VERSION ""

NS_ :

BS_:

BU_: CLU H_U CGW

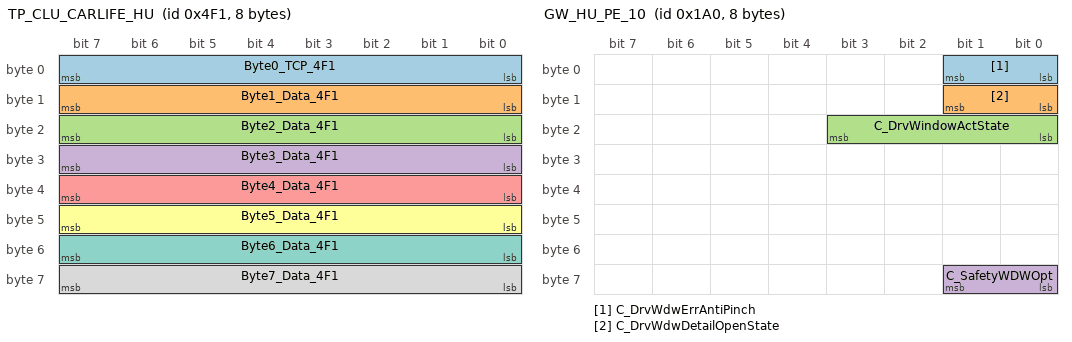
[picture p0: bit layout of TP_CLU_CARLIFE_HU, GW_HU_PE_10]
BO_ 1265 TP_CLU_CARLIFE_HU: 8 CLU
 SG_ Byte0_TCP_4F1 : 7|8@0+ (1,0) [0|0] ""  H_U
 SG_ Byte1_Data_4F1 : 15|8@0+ (1,0) [0|0] ""  H_U
 SG_ Byte2_Data_4F1 : 23|8@0+ (1,0) [0|0] ""  H_U
 SG_ Byte3_Data_4F1 : 31|8@0+ (1,0) [0|0] ""  H_U
 SG_ Byte4_Data_4F1 : 39|8@0+ (1,0) [0|0] ""  H_U
 SG_ Byte5_Data_4F1 : 47|8@0+ (1,0) [0|0] ""  H_U
 SG_ Byte6_Data_4F1 : 55|8@0+ (1,0) [0|0] ""  H_U
 SG_ Byte7_Data_4F1 : 63|8@0+ (1,0) [0|0] ""  H_U

BO_ 416 GW_HU_PE_10: 8 CGW
 SG_ C_DrvWdwErrAntiPinch : 1|2@0+ (1,0) [0|0] ""  H_U
 SG_ C_DrvWdwDetailOpenState : 9|2@0+ (1,0) [0|0] ""  H_U
 SG_ C_DrvWindowActState : 19|4@0+ (1,0) [0|0] ""  H_U
 SG_ C_SafetyWDWOpt : 57|2@0+ (1,0) [0|0] ""  H_U

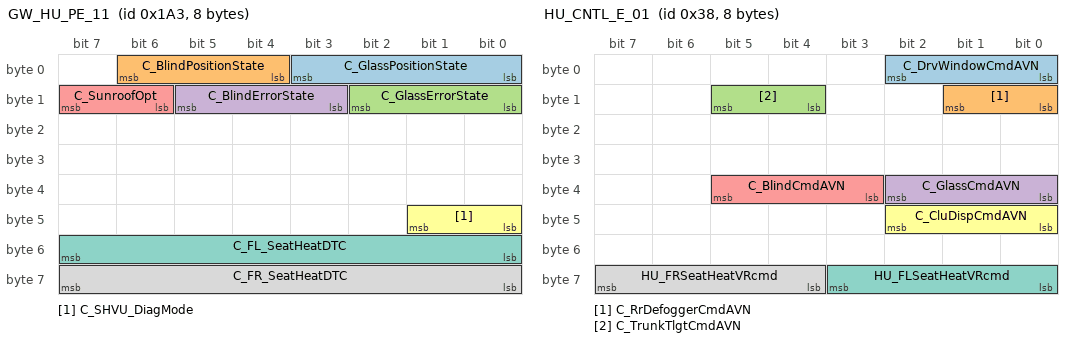
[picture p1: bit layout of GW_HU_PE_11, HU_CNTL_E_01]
BO_ 419 GW_HU_PE_11: 8 CGW
 SG_ C_GlassPositionState : 3|4@0+ (1,0) [0|0] ""  H_U
 SG_ C_BlindPositionState : 6|3@0+ (1,0) [0|0] ""  H_U
 SG_ C_GlassErrorState : 10|3@0+ (1,0) [0|0] ""  H_U
 SG_ C_BlindErrorState : 13|3@0+ (1,0) [0|0] ""  H_U
 SG_ C_SunroofOpt : 15|2@0+ (1,0) [0|0] ""  H_U
 SG_ C_SHVU_DiagMode : 41|2@0+ (1,0) [0|0] ""  H_U
 SG_ C_FL_SeatHeatDTC : 55|8@0+ (1,0) [0|0] ""  H_U
 SG_ C_FR_SeatHeatDTC : 63|8@0+ (1,0) [0|0] ""  H_U

BO_ 56 HU_CNTL_E_01: 8 H_U
 SG_ C_DrvWindowCmdAVN : 2|3@0+ (1,0) [0|0] ""  CGW,CLU
 SG_ C_RrDefoggerCmdAVN : 9|2@0+ (1,0) [0|0] ""  CGW,CLU
 SG_ C_TrunkTlgtCmdAVN : 13|2@0+ (1,0) [0|0] ""  CGW,CLU
 SG_ C_GlassCmdAVN : 34|3@0+ (1,0) [0|0] ""  CGW,CLU
 SG_ C_BlindCmdAVN : 37|3@0+ (1,0) [0|0] ""  CGW,CLU
 SG_ C_CluDispCmdAVN : 42|3@0+ (1,0) [0|0] ""  CLU
 SG_ HU_FLSeatHeatVRcmd : 59|4@0+ (1,0) [0|0] ""  CGW
 SG_ HU_FRSeatHeatVRcmd : 63|4@0+ (1,0) [0|0] ""  CGW

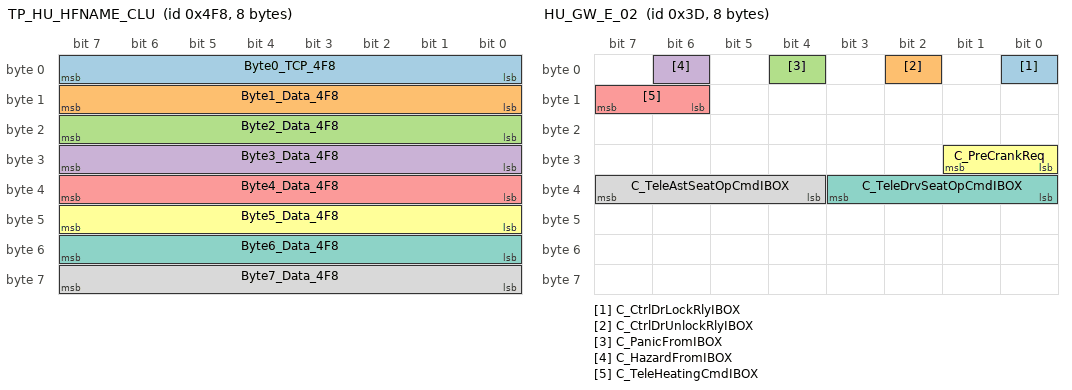
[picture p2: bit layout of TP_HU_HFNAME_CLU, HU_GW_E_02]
BO_ 1272 TP_HU_HFNAME_CLU: 8 H_U
 SG_ Byte0_TCP_4F8 : 7|8@0+ (1,0) [0|0] ""  CLU
 SG_ Byte1_Data_4F8 : 15|8@0+ (1,0) [0|0] ""  CLU
 SG_ Byte2_Data_4F8 : 23|8@0+ (1,0) [0|0] ""  CLU
 SG_ Byte3_Data_4F8 : 31|8@0+ (1,0) [0|0] ""  CLU
 SG_ Byte4_Data_4F8 : 39|8@0+ (1,0) [0|0] ""  CLU
 SG_ Byte5_Data_4F8 : 47|8@0+ (1,0) [0|0] ""  CLU
 SG_ Byte6_Data_4F8 : 55|8@0+ (1,0) [0|0] ""  CLU
 SG_ Byte7_Data_4F8 : 63|8@0+ (1,0) [0|0] ""  CLU

BO_ 61 HU_GW_E_02: 8 H_U
 SG_ C_CtrlDrLockRlyIBOX : 0|1@0+ (1,0) [0|0] ""  CGW
 SG_ C_CtrlDrUnlockRlyIBOX : 2|1@0+ (1,0) [0|0] ""  CGW
 SG_ C_PanicFromIBOX : 4|1@0+ (1,0) [0|0] ""  CGW
 SG_ C_HazardFromIBOX : 6|1@0+ (1,0) [0|0] ""  CGW
 SG_ C_TeleHeatingCmdIBOX : 15|2@0+ (1,0) [0|0] ""  CGW
 SG_ C_PreCrankReq : 25|2@0+ (1,0) [0|0] ""  CGW
 SG_ C_TeleDrvSeatOpCmdIBOX : 35|4@0+ (1,0) [0|0] ""  CGW
 SG_ C_TeleAstSeatOpCmdIBOX : 39|4@0+ (1,0) [0|0] ""  CGW

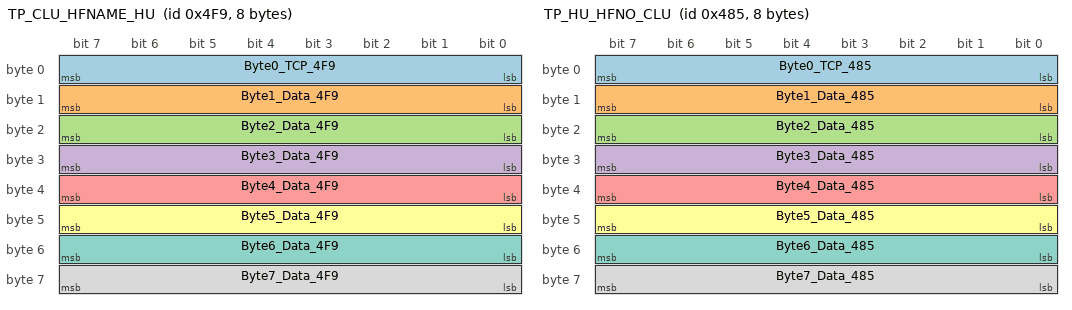
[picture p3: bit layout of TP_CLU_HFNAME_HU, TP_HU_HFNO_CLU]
BO_ 1273 TP_CLU_HFNAME_HU: 8 CLU
 SG_ Byte0_TCP_4F9 : 7|8@0+ (1,0) [0|0] ""  H_U
 SG_ Byte1_Data_4F9 : 15|8@0+ (1,0) [0|0] ""  H_U
 SG_ Byte2_Data_4F9 : 23|8@0+ (1,0) [0|0] ""  H_U
 SG_ Byte3_Data_4F9 : 31|8@0+ (1,0) [0|0] ""  H_U
 SG_ Byte4_Data_4F9 : 39|8@0+ (1,0) [0|0] ""  H_U
 SG_ Byte5_Data_4F9 : 47|8@0+ (1,0) [0|0] ""  H_U
 SG_ Byte6_Data_4F9 : 55|8@0+ (1,0) [0|0] ""  H_U
 SG_ Byte7_Data_4F9 : 63|8@0+ (1,0) [0|0] ""  H_U

BO_ 479 CLU_HU_PE_01: 8 CLU
 SG_ Clu_RheostatLvl : 55|5@0+ (1,0) [0|0] ""  CGW,H_U

BO_ 1157 TP_HU_HFNO_CLU: 8 H_U
 SG_ Byte0_TCP_485 : 7|8@0+ (1,0) [0|0] ""  CLU
 SG_ Byte1_Data_485 : 15|8@0+ (1,0) [0|0] ""  CLU
 SG_ Byte2_Data_485 : 23|8@0+ (1,0) [0|0] ""  CLU
 SG_ Byte3_Data_485 : 31|8@0+ (1,0) [0|0] ""  CLU
 SG_ Byte4_Data_485 : 39|8@0+ (1,0) [0|0] ""  CLU
 SG_ Byte5_Data_485 : 47|8@0+ (1,0) [0|0] ""  CLU
 SG_ Byte6_Data_485 : 55|8@0+ (1,0) [0|0] ""  CLU
 SG_ Byte7_Data_485 : 63|8@0+ (1,0) [0|0] ""  CLU

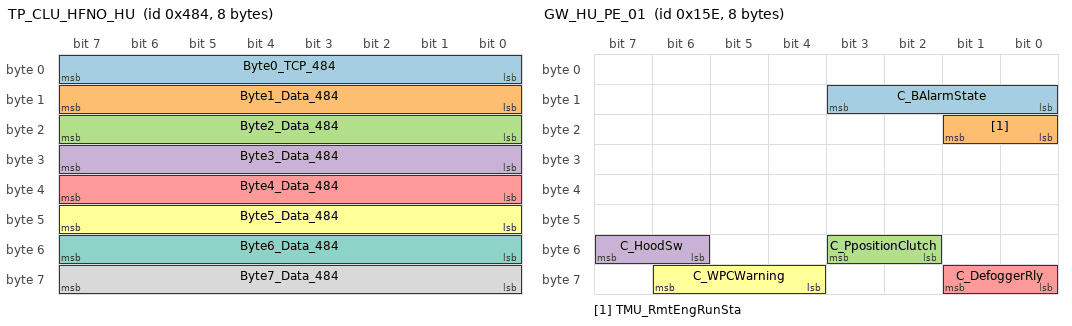
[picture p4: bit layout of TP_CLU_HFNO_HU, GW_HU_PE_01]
BO_ 1156 TP_CLU_HFNO_HU: 8 CLU
 SG_ Byte0_TCP_484 : 7|8@0+ (1,0) [0|0] ""  H_U
 SG_ Byte1_Data_484 : 15|8@0+ (1,0) [0|0] ""  H_U
 SG_ Byte2_Data_484 : 23|8@0+ (1,0) [0|0] ""  H_U
 SG_ Byte3_Data_484 : 31|8@0+ (1,0) [0|0] ""  H_U
 SG_ Byte4_Data_484 : 39|8@0+ (1,0) [0|0] ""  H_U
 SG_ Byte5_Data_484 : 47|8@0+ (1,0) [0|0] ""  H_U
 SG_ Byte6_Data_484 : 55|8@0+ (1,0) [0|0] ""  H_U
 SG_ Byte7_Data_484 : 63|8@0+ (1,0) [0|0] ""  H_U

BO_ 336 GW_AMP_PE_01: 8 CGW
 SG_ ANC_EngineCHR : 37|4@0+ (1,0) [0|15] ""  H_U

BO_ 1434 GW_HU_P_00: 8 CGW
 SG_ SAS_Angle : 7|16@0- (0.1,0) [-3276.8|3276.7] "Deg"  H_U

BO_ 350 GW_HU_PE_01: 8 CGW
 SG_ C_BAlarmState : 11|4@0+ (1,0) [0|0] ""  H_U
 SG_ TMU_RmtEngRunSta : 17|2@0+ (1,0) [0|0] ""  H_U
 SG_ C_PpositionClutch : 51|2@0+ (1,0) [0|0] ""  H_U
 SG_ C_HoodSw : 55|2@0+ (1,0) [0|0] ""  H_U
 SG_ C_DefoggerRly : 57|2@0+ (1,0) [0|0] ""  H_U
 SG_ C_WPCWarning : 62|3@0+ (1,0) [0|0] ""  H_U

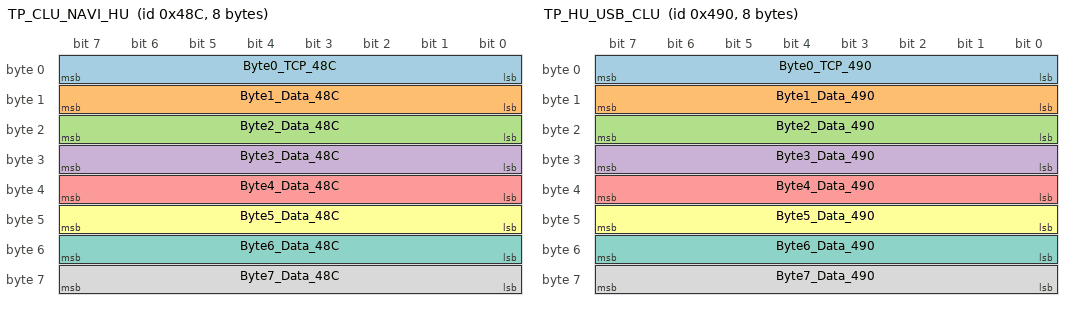
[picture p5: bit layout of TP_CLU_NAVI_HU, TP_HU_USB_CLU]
BO_ 1164 TP_CLU_NAVI_HU: 8 CLU
 SG_ Byte0_TCP_48C : 7|8@0+ (1,0) [0|0] ""  H_U
 SG_ Byte1_Data_48C : 15|8@0+ (1,0) [0|0] ""  H_U
 SG_ Byte2_Data_48C : 23|8@0+ (1,0) [0|0] ""  H_U
 SG_ Byte3_Data_48C : 31|8@0+ (1,0) [0|0] ""  H_U
 SG_ Byte4_Data_48C : 39|8@0+ (1,0) [0|0] ""  H_U
 SG_ Byte5_Data_48C : 47|8@0+ (1,0) [0|0] ""  H_U
 SG_ Byte6_Data_48C : 55|8@0+ (1,0) [0|0] ""  H_U
 SG_ Byte7_Data_48C : 63|8@0+ (1,0) [0|0] ""  H_U

BO_ 344 GW_CLU_PE: 8 CGW
 SG_ CF_Clu_LowfuelWarning : 13|2@0+ (1,0) [0|0] ""  H_U
 SG_ C_InhibitRMT : 15|2@0+ (1,0) [0|0] ""  H_U

BO_ 1168 TP_HU_USB_CLU: 8 H_U
 SG_ Byte0_TCP_490 : 7|8@0+ (1,0) [0|0] ""  CLU
 SG_ Byte1_Data_490 : 15|8@0+ (1,0) [0|0] ""  CLU
 SG_ Byte2_Data_490 : 23|8@0+ (1,0) [0|0] ""  CLU
 SG_ Byte3_Data_490 : 31|8@0+ (1,0) [0|0] ""  CLU
 SG_ Byte4_Data_490 : 39|8@0+ (1,0) [0|0] ""  CLU
 SG_ Byte5_Data_490 : 47|8@0+ (1,0) [0|0] ""  CLU
 SG_ Byte6_Data_490 : 55|8@0+ (1,0) [0|0] ""  CLU
 SG_ Byte7_Data_490 : 63|8@0+ (1,0) [0|0] ""  CLU

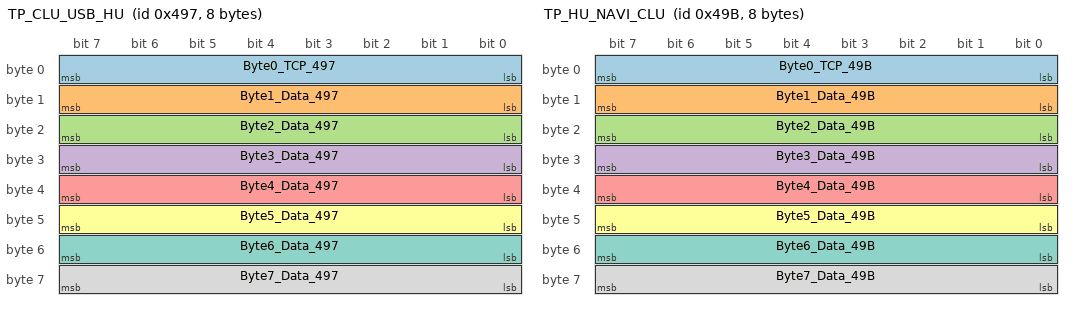
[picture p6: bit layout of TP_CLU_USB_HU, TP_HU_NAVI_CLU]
BO_ 1175 TP_CLU_USB_HU: 8 CLU
 SG_ Byte0_TCP_497 : 7|8@0+ (1,0) [0|0] ""  H_U
 SG_ Byte1_Data_497 : 15|8@0+ (1,0) [0|0] ""  H_U
 SG_ Byte2_Data_497 : 23|8@0+ (1,0) [0|0] ""  H_U
 SG_ Byte3_Data_497 : 31|8@0+ (1,0) [0|0] ""  H_U
 SG_ Byte4_Data_497 : 39|8@0+ (1,0) [0|0] ""  H_U
 SG_ Byte5_Data_497 : 47|8@0+ (1,0) [0|0] ""  H_U
 SG_ Byte6_Data_497 : 55|8@0+ (1,0) [0|0] ""  H_U
 SG_ Byte7_Data_497 : 63|8@0+ (1,0) [0|0] ""  H_U

BO_ 1179 TP_HU_NAVI_CLU: 8 H_U
 SG_ Byte0_TCP_49B : 7|8@0+ (1,0) [0|0] ""  CLU
 SG_ Byte1_Data_49B : 15|8@0+ (1,0) [0|0] ""  CLU
 SG_ Byte2_Data_49B : 23|8@0+ (1,0) [0|0] ""  CLU
 SG_ Byte3_Data_49B : 31|8@0+ (1,0) [0|0] ""  CLU
 SG_ Byte4_Data_49B : 39|8@0+ (1,0) [0|0] ""  CLU
 SG_ Byte5_Data_49B : 47|8@0+ (1,0) [0|0] ""  CLU
 SG_ Byte6_Data_49B : 55|8@0+ (1,0) [0|0] ""  CLU
 SG_ Byte7_Data_49B : 63|8@0+ (1,0) [0|0] ""  CLU

BO_ 448 HU_DATC_PE_00: 8 H_U
 SG_ HU_VRActivity : 33|2@0+ (1,0) [0|0] ""  CGW,CLU

BO_ 372 HU_GW_PE_02: 8 H_U
 SG_ HU_TeleSoCAlertValueSet : 7|8@0+ (1,0) [0|100] "%"  CGW
 SG_ HU_TeleVehicleStatusReq : 9|2@0+ (1,0) [0|3] ""  CGW

BO_ 369 HU_Car_PE_01: 8 H_U
 SG_ HU_VehiclePwr : 3|4@0+ (1,0) [0|0] ""  CLU

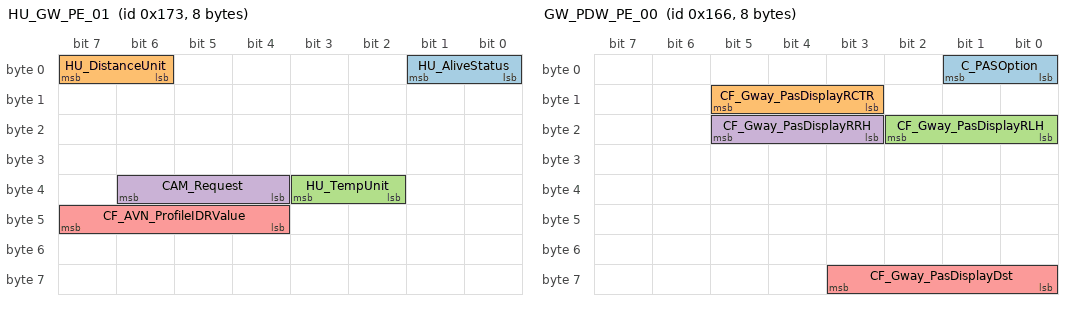
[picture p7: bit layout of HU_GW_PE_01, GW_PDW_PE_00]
BO_ 371 HU_GW_PE_01: 8 H_U
 SG_ HU_AliveStatus : 1|2@0+ (1,0) [0|0] ""  CGW,CLU
 SG_ HU_DistanceUnit : 7|2@0+ (1,0) [0|0] ""  CLU
 SG_ HU_TempUnit : 35|2@0+ (1,0) [0|0] ""  CGW,CLU
 SG_ CAM_Request : 38|3@0+ (1,0) [0|0] ""  CGW
 SG_ CF_AVN_ProfileIDRValue : 47|4@0+ (1,0) [0|0] ""  CGW,CLU

BO_ 232 HU_GW_E_00: 8 H_U
 SG_ C_SHVU_DTC_Mode : 29|2@0+ (1,0) [0|0] ""  CGW

BO_ 1329 DATC_P_02: 8 CGW
 SG_ DATC_AmbientTempC : 7|8@0+ (0.5,-41) [-40|60] "C"  H_U
 SG_ DATC_AmbientTempF : 23|8@0+ (1,-42) [-40|140] "F"  H_U

BO_ 383 GW_HU_PE_06: 8 CGW
 SG_ Warn_DrvDrSwSta : 1|2@0+ (1,0) [0|0] ""  H_U
 SG_ Warn_AsstDrSwSta : 3|2@0+ (1,0) [0|0] ""  H_U
 SG_ Warn_RrLftDrSwSta : 5|2@0+ (1,0) [0|0] ""  H_U
 SG_ Warn_RrRtDrSwSta : 7|2@0+ (1,0) [0|0] ""  H_U
 SG_ DoorLock_DrvDrUnLkSta : 9|2@0+ (1,0) [0|0] ""  H_U
 SG_ DoorLock_AsstDrUnLkSta : 11|2@0+ (1,0) [0|0] ""  H_U
 SG_ DoorLock_RrLftDrUnLkSta : 13|2@0+ (1,0) [0|0] ""  H_U
 SG_ DoorLock_RrRtDrUnLkSta : 15|2@0+ (1,0) [0|0] ""  H_U
 SG_ Trunk_TrnkTlgtSwSta : 17|2@0+ (1,0) [0|0] ""  H_U
 SG_ Warn_SunRoofOpnSta : 19|2@0+ (1,0) [0|0] ""  H_U
 SG_ BAlarm_PncAlrmReq : 21|2@0+ (1,0) [0|0] ""  H_U
 SG_ Lamp_AutoLtSnsrNightSta : 23|2@0+ (1,0) [0|0] ""  H_U
 SG_ ExtLamp_ExtrnlTailLmpSta : 25|2@0+ (1,0) [0|0] ""  H_U
 SG_ ExtLamp_FrFgLmpSta : 27|2@0+ (1,0) [0|0] ""  H_U
 SG_ ExtLamp_HdLmpHiSta : 29|2@0+ (1,0) [0|0] ""  H_U
 SG_ ExtLamp_HdLmpLoSta : 31|2@0+ (1,0) [0|0] ""  H_U
 SG_ C_DrvWindowOpenState : 33|2@0+ (1,0) [0|0] ""  H_U
 SG_ C_FOBBatteryStatusInfo : 41|2@0+ (1,0) [0|0] ""  H_U
 SG_ C_BrakeFluidSw : 43|2@0+ (1,0) [0|0] ""  H_U
 SG_ C_BCMFobID : 46|3@0+ (1,0) [0|0] ""  H_U
 SG_ C_SMKFobID : 50|3@0+ (1,0) [0|0] ""  H_U

BO_ 119 HU_BLE_E_03: 8 H_U
 SG_ C_BLE_Encrypted_Result4 : 7|64@0+ (1,0) [0|0] ""  CGW

BO_ 118 HU_BLE_E_02: 8 H_U
 SG_ C_BLE_Encrypted_Result3 : 7|64@0+ (1,0) [0|0] ""  CGW

BO_ 358 GW_PDW_PE_00: 8 CGW
 SG_ C_PASOption : 1|2@0+ (1,0) [0|0] ""  H_U
 SG_ CF_Gway_PasDisplayRCTR : 13|3@0+ (1,0) [0|0] ""  H_U
 SG_ CF_Gway_PasDisplayRLH : 18|3@0+ (1,0) [0|0] ""  H_U
 SG_ CF_Gway_PasDisplayRRH : 21|3@0+ (1,0) [0|0] ""  H_U
 SG_ CF_Gway_PasDisplayDst : 59|4@0+ (1,0) [0|0] ""  H_U

BO_ 117 HU_BLE_E_01: 8 H_U
 SG_ C_BLE_Encrypted_Result2 : 7|64@0+ (1,0) [0|0] ""  CGW

BO_ 116 HU_BLE_E_00: 8 H_U
 SG_ C_BLE_Encrypted_Result1 : 7|64@0+ (1,0) [0|0] ""  CGW

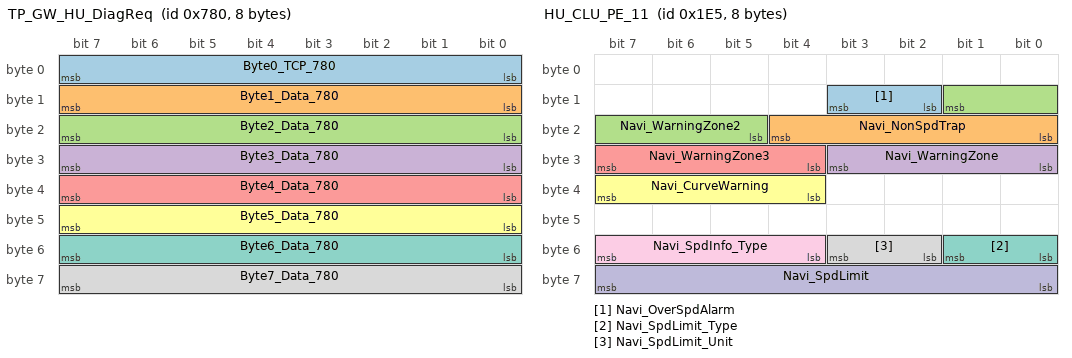
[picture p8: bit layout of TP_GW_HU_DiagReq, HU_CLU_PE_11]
BO_ 1920 TP_GW_HU_DiagReq: 8 CGW
 SG_ Byte0_TCP_780 : 7|8@0+ (1,0) [0|0] ""  H_U
 SG_ Byte1_Data_780 : 15|8@0+ (1,0) [0|0] ""  H_U
 SG_ Byte2_Data_780 : 23|8@0+ (1,0) [0|0] ""  H_U
 SG_ Byte3_Data_780 : 31|8@0+ (1,0) [0|0] ""  H_U
 SG_ Byte4_Data_780 : 39|8@0+ (1,0) [0|0] ""  H_U
 SG_ Byte5_Data_780 : 47|8@0+ (1,0) [0|0] ""  H_U
 SG_ Byte6_Data_780 : 55|8@0+ (1,0) [0|0] ""  H_U
 SG_ Byte7_Data_780 : 63|8@0+ (1,0) [0|0] ""  H_U

BO_ 485 HU_CLU_PE_11: 8 H_U
 SG_ Navi_OverSpdAlarm : 11|2@0+ (1,0) [0|0] ""  CGW,CLU
 SG_ Navi_NonSpdTrap : 20|5@0+ (1,0) [0|0] ""  CLU
 SG_ Navi_WarningZone2 : 9|5@0+ (1,0) [0|0] ""  CLU
 SG_ Navi_WarningZone : 27|4@0+ (1,0) [0|0] ""  CLU
 SG_ Navi_WarningZone3 : 31|4@0+ (1,0) [0|0] ""  CLU
 SG_ Navi_CurveWarning : 39|4@0+ (1,0) [0|0] ""  CLU
 SG_ Navi_SpdLimit_Type : 49|2@0+ (1,0) [0|0] ""  CLU
 SG_ Navi_SpdLimit_Unit : 51|2@0+ (1,0) [0|0] ""  CLU
 SG_ Navi_SpdInfo_Type : 55|4@0+ (1,0) [0|0] ""  CLU
 SG_ Navi_SpdLimit : 63|8@0+ (1,0) [1|254] ""  CLU

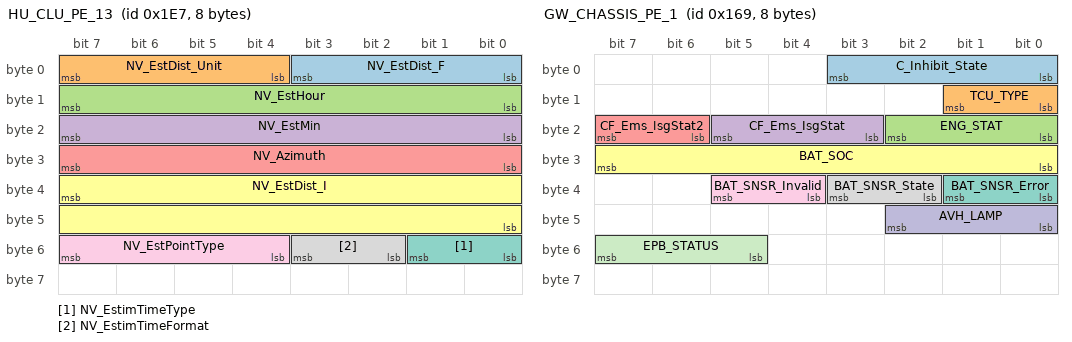
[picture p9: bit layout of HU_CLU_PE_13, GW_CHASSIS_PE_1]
BO_ 487 HU_CLU_PE_13: 8 H_U
 SG_ NV_EstDist_F : 3|4@0+ (1,0) [0|0] ""  CGW,CLU
 SG_ NV_EstDist_Unit : 7|4@0+ (1,0) [0|0] ""  CGW,CLU
 SG_ NV_EstHour : 15|8@0+ (1,0) [0|0] ""  CGW,CLU
 SG_ NV_EstMin : 23|8@0+ (1,0) [0|0] ""  CGW,CLU
 SG_ NV_Azimuth : 31|8@0+ (7.5,0) [0|352.5] "Degree"  CGW,CLU
 SG_ NV_EstDist_I : 39|16@0+ (1,0) [0|0] ""  CGW,CLU
 SG_ NV_EstimTimeType : 49|2@0+ (1,0) [0|0] ""  CGW,CLU
 SG_ NV_EstimTimeFormat : 51|2@0+ (1,0) [0|0] ""  CGW,CLU
 SG_ NV_EstPointType : 55|4@0+ (1,0) [0|0] ""  CGW,CLU

BO_ 361 GW_CHASSIS_PE_1: 8 CGW
 SG_ C_Inhibit_State : 3|4@0+ (1,0) [0|0] ""  H_U
 SG_ TCU_TYPE : 9|2@0+ (1,0) [0|3] ""  H_U
 SG_ ENG_STAT : 18|3@0+ (1,0) [0|7] ""  H_U
 SG_ CF_Ems_IsgStat : 21|3@0+ (1,0) [0|7] ""  H_U
 SG_ CF_Ems_IsgStat2 : 23|2@0+ (2,0) [0|3] ""  H_U
 SG_ BAT_SOC : 31|8@0+ (1,0) [0|100] "%"  H_U
 SG_ BAT_SNSR_Error : 33|2@0+ (1,0) [0|0] ""  H_U
 SG_ BAT_SNSR_State : 35|2@0+ (1,0) [0|0] ""  H_U
 SG_ BAT_SNSR_Invalid : 37|2@0+ (1,0) [0|0] ""  H_U
 SG_ AVH_LAMP : 42|3@0+ (1,0) [0|7] ""  H_U
 SG_ EPB_STATUS : 55|3@0+ (1,0) [0|7] ""  H_U

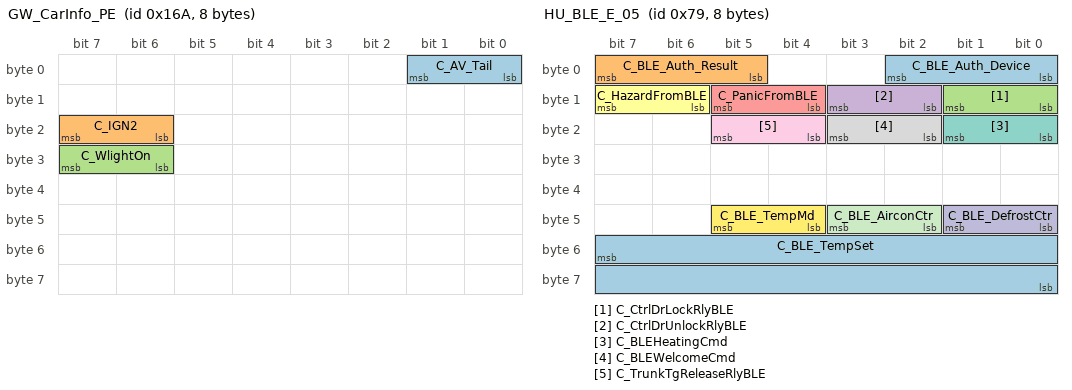
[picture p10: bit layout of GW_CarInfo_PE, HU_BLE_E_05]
BO_ 362 GW_CarInfo_PE: 8 CGW
 SG_ C_AV_Tail : 1|2@0+ (1,0) [0|0] ""  CLU,H_U
 SG_ C_IGN2 : 23|2@0+ (1,0) [0|0] ""  CLU,H_U
 SG_ C_WlightOn : 31|2@0+ (1,0) [0|0] ""  H_U

BO_ 121 HU_BLE_E_05: 8 H_U
 SG_ C_BLE_Auth_Device : 2|3@0+ (1,0) [0|0] ""  CGW
 SG_ C_BLE_Auth_Result : 7|3@0+ (1,0) [0|0] ""  CGW
 SG_ C_CtrlDrLockRlyBLE : 9|2@0+ (1,0) [0|0] ""  CGW
 SG_ C_CtrlDrUnlockRlyBLE : 11|2@0+ (1,0) [0|0] ""  CGW
 SG_ C_PanicFromBLE : 13|2@0+ (1,0) [0|0] ""  CGW
 SG_ C_HazardFromBLE : 15|2@0+ (1,0) [0|0] ""  CGW
 SG_ C_BLEHeatingCmd : 17|2@0+ (1,0) [0|0] ""  CGW
 SG_ C_BLEWelcomeCmd : 19|2@0+ (1,0) [0|0] ""  CGW
 SG_ C_TrunkTgReleaseRlyBLE : 21|2@0+ (1,0) [0|0] ""  CGW
 SG_ C_BLE_DefrostCtr : 41|2@0+ (1,0) [0|0] ""  CGW
 SG_ C_BLE_AirconCtr : 43|2@0+ (1,0) [0|0] ""  CGW
 SG_ C_BLE_TempMd : 45|2@0+ (1,0) [0|0] ""  CGW
 SG_ C_BLE_TempSet : 55|16@0+ (1,0) [0|0] ""  CGW

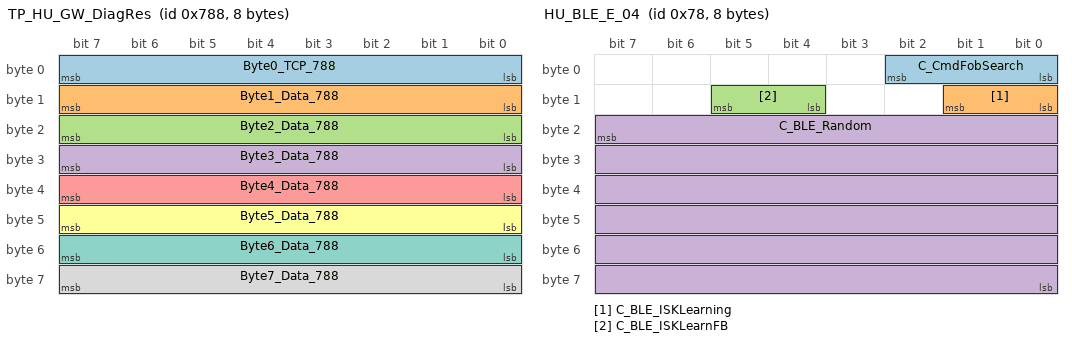
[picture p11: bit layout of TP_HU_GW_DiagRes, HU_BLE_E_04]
BO_ 1928 TP_HU_GW_DiagRes: 8 H_U
 SG_ Byte0_TCP_788 : 7|8@0+ (1,0) [0|0] ""  CGW
 SG_ Byte1_Data_788 : 15|8@0+ (1,0) [0|0] ""  CGW
 SG_ Byte2_Data_788 : 23|8@0+ (1,0) [0|0] ""  CGW
 SG_ Byte3_Data_788 : 31|8@0+ (1,0) [0|0] ""  CGW
 SG_ Byte4_Data_788 : 39|8@0+ (1,0) [0|0] ""  CGW
 SG_ Byte5_Data_788 : 47|8@0+ (1,0) [0|0] ""  CGW
 SG_ Byte6_Data_788 : 55|8@0+ (1,0) [0|0] ""  CGW
 SG_ Byte7_Data_788 : 63|8@0+ (1,0) [0|0] ""  CGW

BO_ 120 HU_BLE_E_04: 8 H_U
 SG_ C_CmdFobSearch : 2|3@0+ (1,0) [0|0] ""  CGW
 SG_ C_BLE_ISKLearning : 9|2@0+ (1,0) [0|0] ""  CGW
 SG_ C_BLE_ISKLearnFB : 13|2@0+ (1,0) [0|0] ""  CGW
 SG_ C_BLE_Random : 23|48@0+ (1,0) [0|0] ""  CGW

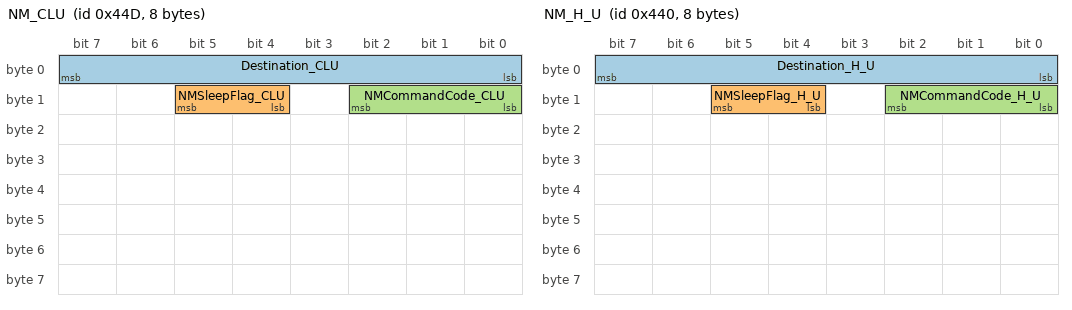
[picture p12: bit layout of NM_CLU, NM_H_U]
BO_ 1101 NM_CLU: 8 CLU
 SG_ Destination_CLU : 7|8@0+ (1,0) [0|0] ""  H_U,CGW
 SG_ NMSleepFlag_CLU : 13|2@0+ (1,0) [0|0] ""  H_U,CGW
 SG_ NMCommandCode_CLU : 10|3@0+ (1,0) [0|0] ""  H_U,CGW

BO_ 1088 NM_H_U: 8 H_U
 SG_ Destination_H_U : 7|8@0+ (1,0) [0|0] ""  CLU,CGW
 SG_ NMSleepFlag_H_U : 13|2@0+ (1,0) [0|0] ""  CLU,CGW
 SG_ NMCommandCode_H_U : 10|3@0+ (1,0) [0|0] ""  CLU,CGW

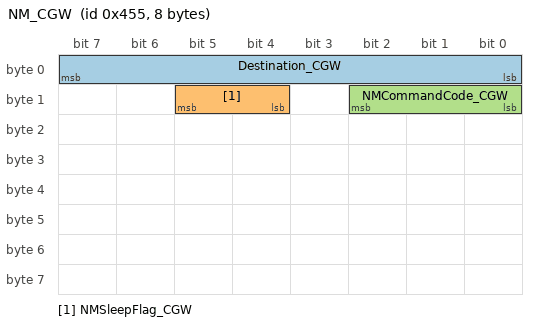
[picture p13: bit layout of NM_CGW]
BO_ 1109 NM_CGW: 8 CGW
 SG_ Destination_CGW : 7|8@0+ (1,0) [0|0] ""  CLU,H_U
 SG_ NMSleepFlag_CGW : 13|2@0+ (1,0) [0|0] ""  CLU,H_U
 SG_ NMCommandCode_CGW : 10|3@0+ (1,0) [0|0] ""  CLU,H_U

CM_ BO_ 1329 "[P] Periodic";
CM_ SG_ 1329 DATC_AmbientTempC "Ambient Temperature (C)";
CM_ SG_ 1329 DATC_AmbientTempF "Ambient Temperature (F)";
CM_ BO_ 336 "[PE] Periodic and On Event";
CM_ SG_ 336 ANC_EngineCHR "This signal indicates the characteristic of an engine system - which kind of fuel is used, whether the ETC (Electronic Throttle Contro) is applied or not.

When a normal engine system (gasoline fuel and no ETC) is used this value is 00H.

This signal is same with ENG_CHR (0x150 @CLU)";
CM_ BO_ 361 "[PE] Periodic and On Event";
CM_ SG_ 361 C_Inhibit_State "Information for TGS Lever Gear switch
- For Auto Transmission vehicles Only
- For Manual Transmission, Use C_InhibitRMT(@0x158) instead
- For IGN status, Should consider with this signal and C_IGN1(@0x15A) signal or wire
- This signal is valid only when C_IGN is on
- When C_IGN goes Off, Suppose this signal is OFF";
CM_ SG_ 361 TCU_TYPE "Information for Auto Transmission Type
 : AT 
/ CVT
 / DCT


* Manual transmission : no can signal";
CM_ SG_ 361 ENG_STAT "This signal indicates that a status of engine.
- Use ENG_STAT + CF_Ems_IsgStat or CF_Ems_IsgStat2 signal combination

- For detail logic, please refer to platform specification
* Do not use AltL status signal *";
CM_ SG_ 361 CF_Ems_IsgStat "1. ISG Status expressing CAN message divided by CF_EMS_IsgStat and CF_EMS_IsgStat2 
2. In EMS , CF_EMS_IsgStat and CF_EMS_IsgStat2 do not duplicate the output condition
(EX: If CF_EMS_IsgStat is 01h~07h, CF_EMS_IsgStat2 is 00h)

Use ENG_STAT + CF_Ems_IsgStat or CF_Ems_IsgStat2 signal combination 

For detail logic, please refer to platform specification";
CM_ SG_ 361 CF_Ems_IsgStat2 "1. ISG Status CAN message is divided by CF_EMS_IsgStat and CF_EMS_IsgStat2 
2. CF_EMS_IsgStat and CF_EMS_IsgStat2 do not duplicate the output condition
(EX: If CF_EMS_IsgStat2 is 01h~03h, CF_EMS_IsgStat is 00h)

Use ENG_STAT + CF_Ems_IsgStat or CF_Ems_IsgStat2 signal combination 

For detail logic, please refer to platform specification";
CM_ SG_ 361 BAT_SOC "This signal is battery State of Charge as calculated by battery sensor.
This signal is used for 'Scheduled Update Function' in Normal Vehicle.

PHY = 1 * (HEX Value)";
CM_ SG_ 361 BAT_SNSR_Error "This signal is response error status of battery LIN sensor signal.
HU use this signal for scheduled update function. 
Based on this single bit, HU can conclude the following : 

 - 0x0:operating correctly ==> Proceed the scheduled update.
 - 0x1:response error ==> Restrict the scheduled update.";
CM_ SG_ 361 BAT_SNSR_State "This signal is implausible state of battery SOC detection.
HU use this signal for scheduled update function. 
Based on this single bit, HU can conclude the following : 

 - 0x0:normal state ==> Proceed the scheduled update.
 - 0x1:implausible state ==> Restrict the scheduled update.";
CM_ SG_ 361 BAT_SNSR_Invalid "This signal is valid condition state of battery SOC.
HU use this signal for scheduled update function. 
Based on this single bit, HU can conclude the following : 

 - 0x0:Valid Condition ==> Proceed the scheduled update.
 - 0x1:Invalid Condition ==> Restrict the scheduled update.";
CM_ SG_ 361 AVH_LAMP "0x00 : Auto Hold Off Status
0x01 : Auto Hold Fail
0x02 : Auto Hold Active
0x03 : Auto Hold Ready
H/U should unlock the driver distraction mode even if signal is Auto hold Active(0x02).

Source: TCS15 message AVH_LAMP";
CM_ SG_ 361 EPB_STATUS "Information about the force status of the EPB.
(This signal is for NHTSA driving regulation)";
CM_ BO_ 344 "[PE] Periodic and On Event";
CM_ SG_ 344 CF_Clu_LowfuelWarning "Information for Low fuel warning for AVN";
CM_ SG_ 344 C_InhibitRMT "Information for TGS Lever - R for Manual Transmission Vehicle
For AT type, Use C_Inhibit_state(@0x169) instead";
CM_ BO_ 362 "[PE] Periodic and On Event";
CM_ SG_ 362 C_AV_Tail "Autolight Info";
CM_ SG_ 362 C_IGN2 "Information for IGN2 Status";
CM_ SG_ 362 C_WlightOn "Welcome light On/Off Order";
CM_ BO_ 350 "[PE] Periodic and On Event";
CM_ SG_ 350 C_BAlarmState "Information of Buglar Alarm State
For telematics";
CM_ SG_ 350 TMU_RmtEngRunSta "Information for Feedback of Tele-Cranking command
- Feedback of C_TeleCrankingCmdIBOX @HU_GW_PE_00(0x03D) signal";
CM_ SG_ 350 C_PpositionClutch "* Use for Telematics Remote start fail notification

This signal has different sources according to transmission type(AT/MT).
This siganl is valid when IBU has SMK function.
A/T : TGS Lever P Position Status (P Position Switch or Keyinterlock Switch)
- (Keyinterlock Switch) When TGS lever push button is pushed, though TGS lever is located at P position, this signal value can be 0x0, regardless TGS Lever Location  
M/T : Clutch Ignition Lock Switch";
CM_ SG_ 350 C_HoodSw "Information for Hood open status
For Telematics";
CM_ SG_ 350 C_DefoggerRly "This signal indicates rear glass defog status.";
CM_ SG_ 350 C_WPCWarning "Warning by WPC for User (Phone left in vehicle)

Display status of remote phone charging on H/U by using this signal.
Receiving 0x0 value means no phone or no WPC unit.
(In both cases, H/U indicates nothing)";
CM_ BO_ 383 "[PE] Periodic and On Event";
CM_ SG_ 383 Warn_DrvDrSwSta "Information for Driver Door Close SW
For H/U pre-booting, SVM(Surround View Module), Telematics Function";
CM_ SG_ 383 Warn_AsstDrSwSta "Information for Assist Door Close SW
For SVM(Surround View Module), Telematics Function";
CM_ SG_ 383 Warn_RrLftDrSwSta "Information for Rear Left Door Close SW
For SVM(Surround View Module), Telematics Function";
CM_ SG_ 383 Warn_RrRtDrSwSta "Information for Rear Right Door Close SW
For SVM(Surround View Module), Telematics Function";
CM_ SG_ 383 DoorLock_DrvDrUnLkSta "Driver Door Lock Status for Prebooting and telematics";
CM_ SG_ 383 DoorLock_AsstDrUnLkSta "Assist Door Lock Status for telematics";
CM_ SG_ 383 DoorLock_RrLftDrUnLkSta "Rear Left Door Lock Status for telematics";
CM_ SG_ 383 DoorLock_RrRtDrUnLkSta "Rear Right Door Lock Status for telematics";
CM_ SG_ 383 Trunk_TrnkTlgtSwSta "Information for Trunk Tailgate Door Close SW
For SVM(Surround View Module), Telematics Function";
CM_ SG_ 383 Warn_SunRoofOpnSta "Information of Sunroof Open/Close State";
CM_ SG_ 383 BAlarm_PncAlrmReq "Information of Panic State
For telematics";
CM_ SG_ 383 Lamp_AutoLtSnsrNightSta "This signal indicates autolight sensor output.
This signal also used for early evening status determination for LCD illumination.
* Early evening mode condition : 
When C_AV_Tail is 0x1 (Deactivated) and Lamp_AutoLtSnsrNightSta is 0x1 (Night), early evening status is activated";
CM_ SG_ 383 ExtLamp_ExtrnlTailLmpSta "Tail Lamp On/Off status signal";
CM_ SG_ 383 ExtLamp_FrFgLmpSta "Front fog lamp On/Off status signal";
CM_ SG_ 383 ExtLamp_HdLmpHiSta "High beam lead lamp On/Off status signal";
CM_ SG_ 383 ExtLamp_HdLmpLoSta "Low beam lead lamp On/Off status signal";
CM_ SG_ 383 C_DrvWindowOpenState "This signal indicates DRV Window Open/Close Status";
CM_ SG_ 383 C_FOBBatteryStatusInfo "Receive Fob Battery Status for Telematics Vehicle Information Service";
CM_ SG_ 383 C_BrakeFluidSw "Brake oil warning notification (on/off)";
CM_ SG_ 383 C_BCMFobID "Fob key ID for HU personalized function";
CM_ SG_ 383 C_SMKFobID "SMK ID for personalized function";
CM_ BO_ 416 "[PE] Periodic and On Event";
CM_ SG_ 416 C_DrvWdwErrAntiPinch "The DRV Window state whether Calibrated or not";
CM_ SG_ 416 C_DrvWdwDetailOpenState "This signal indicates DRV Window Open/Close Detail Status";
CM_ SG_ 416 C_DrvWindowActState "This signal indicates DRV Window Action Status";
CM_ SG_ 416 C_SafetyWDWOpt "Option flag for All Safety Window system";
CM_ BO_ 419 "[PE] Periodic and On Event";
CM_ SG_ 419 C_GlassPositionState "This signal indicates Sunroof Glass Open/Close Status";
CM_ SG_ 419 C_BlindPositionState "This signal indicates Sunroof Blind Open/Close Status";
CM_ SG_ 419 C_GlassErrorState "This signal indicates Sunroof Glass error Status";
CM_ SG_ 419 C_BlindErrorState "This signal indicates Sunroof Blind error Status";
CM_ SG_ 419 C_SunroofOpt "Option flag for Sunroof system";
CM_ SG_ 419 C_SHVU_DiagMode "Seat diagnosis status";
CM_ SG_ 419 C_FL_SeatHeatDTC "Driver seat DTC to show on HU";
CM_ SG_ 419 C_FR_SeatHeatDTC "Passenger seat DTC to show on HU";
CM_ BO_ 1434 "[P] Periodic";
CM_ SG_ 1434 SAS_Angle "Information regarding the steering wheel angle.

(PH) = (HEX) * 0.1 (0 <  HEX ≤ 7FFFH) or
(PH) = (HEX - 65536) * 0.1 (HEX > 7FFFH)";
CM_ BO_ 358 "[PE] Periodic and On Event";
CM_ SG_ 358 C_PASOption "PAS Option information";
CM_ SG_ 358 CF_Gway_PasDisplayRCTR "PAS Warning display : Rear Center";
CM_ SG_ 358 CF_Gway_PasDisplayRLH "PAS Warning display : Rear Left";
CM_ SG_ 358 CF_Gway_PasDisplayRRH "PAS Warning display : Rear Right";
CM_ SG_ 358 CF_Gway_PasDisplayDst "When in R gear status, IBU(BCM) send display signal to show rear distance info on HU RVM or SVM screen";
CM_ BO_ 1920 "[TP] TP Message";
CM_ BO_ 479 "[PE] Periodic and On Event";
CM_ SG_ 479 Clu_RheostatLvl "For LCD brightness Only
Keyboard brightness is using Hard Wire
Step 21 is Detent

This signal is valid at 'Tail On' condition";
CM_ BO_ 1265 "[TP] TP Message";
CM_ BO_ 1273 "[TP] TP Message";
CM_ BO_ 1156 "[TP] TP Message";
CM_ BO_ 1164 "[TP] TP Message";
CM_ BO_ 1175 "[TP] TP Message";
CM_ BO_ 116 "[EC] On Event and On Change";
CM_ SG_ 116 C_BLE_Encrypted_Result1 "This signal is for a send encrypted result of BLE.";
CM_ BO_ 117 "[EC] On Event and On Change";
CM_ SG_ 117 C_BLE_Encrypted_Result2 "This signal is for a send encrypted result of BLE.";
CM_ BO_ 118 "[EC] On Event and On Change";
CM_ SG_ 118 C_BLE_Encrypted_Result3 "This signal is for a send encrypted result of BLE.";
CM_ BO_ 119 "[EC] On Event and On Change";
CM_ SG_ 119 C_BLE_Encrypted_Result4 "This signal is for a send encrypted result of BLE.";
CM_ BO_ 120 "[EC] On Event and On Change";
CM_ SG_ 120 C_CmdFobSearch "Signal to request Fob search to IBU";
CM_ SG_ 120 C_BLE_ISKLearning "This signal is to request ISK Learning to IBU";
CM_ SG_ 120 C_BLE_ISKLearnFB "This signal is Learning Feedback";
CM_ SG_ 120 C_BLE_Random "Random number";
CM_ BO_ 121 "[EC] On Event and On Change";
CM_ SG_ 121 C_BLE_Auth_Device "This signal inform where ask to auth to HU";
CM_ SG_ 121 C_BLE_Auth_Result "This signal informs the result of authentication";
CM_ SG_ 121 C_CtrlDrLockRlyBLE "For BLE Remote Lock Command";
CM_ SG_ 121 C_CtrlDrUnlockRlyBLE "For BLE Remote UnLock Command";
CM_ SG_ 121 C_PanicFromBLE "For BLE Remote Panic Command";
CM_ SG_ 121 C_HazardFromBLE "For BLE Remote Hazard Command";
CM_ SG_ 121 C_BLEHeatingCmd "For BLE Remote Heating
(Steering Wheel, Rear Window, Side Mirror)";
CM_ SG_ 121 C_BLEWelcomeCmd "For BLE Welcome Command";
CM_ SG_ 121 C_TrunkTgReleaseRlyBLE "For BLE Remote Trunk Command";
CM_ SG_ 121 C_BLE_DefrostCtr "For BLE remote climate defrost Command";
CM_ SG_ 121 C_BLE_AirconCtr "For BLE remote climate control Command";
CM_ SG_ 121 C_BLE_TempMd "For BLE remote climate mode Command";
CM_ SG_ 121 C_BLE_TempSet "For BLE remote climate temp setting Command.
Value table
0x0:OFF, 0x1:LO, 0x2:15℃/58℉, 0x3:15.5℃/59℉, 0x4:16℃/60, 0x5:16.5℃/61℉, 0x6:17℃/62℉, 0x7:17.5℃/63℉, 0x8:18℃/64℉, 0x9:18.5℃/65℉, 0xA:19℃/66℉, 0xB:19.5℃/67℉, 0xC:20℃/68℉, 0xD:20.5℃/69℉, 0xE:21℃/70℉, 0xF:21.5℃/71℉, 0x10:22℃/72℉, 0x11:22.5℃/73℉, 0x12:23℃/74℉, 0x13:23.5℃/75℉, 0x14:24℃/76℉, 0x15:24.5℃/77℉, 0x16:25℃/78℉, 0x17:25.5℃/79℉, 0x18:26℃/80℉, 0x19:26.5℃/81℉, 0x1A:27℃/82℉, 0x1B:27.5℃/83℉, 0x1C:28℃/84℉, 0x1D:28.5℃/85℉, 0x1E:29℃/86℉, 0x1F:29.5℃/87℉, 0x20:30℃/88℉, 0x21:30.5℃/89℉, 0x22:31℃/90℉, 0x23:31.5℃/91℉, 0x24:32℃/92℉, 0xFE:HI, 0xFF:INVALID";
CM_ BO_ 485 "[PE] Periodic and On Event";
CM_ SG_ 485 Navi_OverSpdAlarm "Command for Alarm of Over speed";
CM_ SG_ 485 Navi_NonSpdTrap "Inform Non Speed-Traps";
CM_ SG_ 485 Navi_WarningZone2 "Inform warning zones";
CM_ SG_ 485 Navi_WarningZone "Inform warning zones";
CM_ SG_ 485 Navi_WarningZone3 "Inform warning zones";
CM_ SG_ 485 Navi_CurveWarning "Information for Warning a curve";
CM_ SG_ 485 Navi_SpdLimit_Type "Information for Type of Speed Limit Warning";
CM_ SG_ 485 Navi_SpdLimit_Unit "Informatin for Unit of Speed Limit Warning";
CM_ SG_ 485 Navi_SpdInfo_Type "Information for Type of Warning related with Speed";
CM_ SG_ 485 Navi_SpdLimit "Information for Speed of Speed Limit Warning";
CM_ BO_ 487 "[PE] Periodic and On Event";
CM_ SG_ 487 NV_EstDist_F "Information for distance to destination or stops (Under decimal point)";
CM_ SG_ 487 NV_EstDist_Unit "Information for distance unit
Unit for NV_EstDist_F & Nv_EstDist_F";
CM_ SG_ 487 NV_EstHour "Information for Estimate Time of Arrival / Necessary Time (Hour)";
CM_ SG_ 487 NV_EstMin "Information for Estimate Time of Arrival / Necessary Time (Minutes)";
CM_ SG_ 487 NV_Azimuth "Information for north azimuth angle
- 48 directions (7.5 deg. Interval)";
CM_ SG_ 487 NV_EstDist_I "Information for distance to destination or stops (Over decimal point)";
CM_ SG_ 487 NV_EstimTimeType "Information for Estimated time type
1. ETA(Estimated Time to Arrive)
2. RTA(Remaining Time to Arrive) - (Necessary Time)";
CM_ SG_ 487 NV_EstimTimeFormat "Information for Time Format of Estimated Arrival Time (12H/24H)";
CM_ SG_ 487 NV_EstPointType "Informatio for Destination / Waypoint Type";
CM_ BO_ 56 "[EC] On Event and On Change";
CM_ SG_ 56 C_DrvWindowCmdAVN "This signal indicates DRV Window Open/Close Command";
CM_ SG_ 56 C_RrDefoggerCmdAVN "This signal indicates Rear Defogger Button Command";
CM_ SG_ 56 C_TrunkTlgtCmdAVN "This signal indicates Trunk Open Button Command";
CM_ SG_ 56 C_GlassCmdAVN "This signal indicates Sunroof Glass Open/Close Command";
CM_ SG_ 56 C_BlindCmdAVN "This signal indicates Sunroof Blind Open/Close Command";
CM_ SG_ 56 C_CluDispCmdAVN "This signal indicates cluster display changing Command";
CM_ SG_ 56 HU_FLSeatHeatVRcmd "This signal indicated seat heat&vent VR control command (For driver seat)";
CM_ SG_ 56 HU_FRSeatHeatVRcmd "This signal indicated seat heat&vent VR control command (For passenger seat)";
CM_ BO_ 369 "[PE] Periodic and On Event";
CM_ SG_ 369 HU_VehiclePwr "Information for the H/U power status for ADM(Accessary Delay Mode)";
CM_ BO_ 448 "[PE] Periodic and On Event";
CM_ SG_ 448 HU_VRActivity "Information for Acitivity of VR (For All area)";
CM_ BO_ 232 "[EC] On Event and On Change";
CM_ SG_ 232 C_SHVU_DTC_Mode "HU diagnosis request to seat";
CM_ BO_ 61 "[EC] On Event and On Change";
CM_ SG_ 61 C_CtrlDrLockRlyIBOX "Command for Remote Door Lock";
CM_ SG_ 61 C_CtrlDrUnlockRlyIBOX "Command for Remote Door UnLock";
CM_ SG_ 61 C_PanicFromIBOX "Command for Remote Panic (Only for USA)";
CM_ SG_ 61 C_HazardFromIBOX "Command for Remote Hazard";
CM_ SG_ 61 C_TeleHeatingCmdIBOX "'Command for Remote Heating

(Steering Wheel, Rear Window, Side Mirror)";
CM_ SG_ 61 C_PreCrankReq "Command for B-CAN wake up signal
(Need to send this signal before other remote commands)";
CM_ SG_ 61 C_TeleDrvSeatOpCmdIBOX "Command for Remote Seat Heat/Vent control (Driver)";
CM_ SG_ 61 C_TeleAstSeatOpCmdIBOX "Command for Remote Seat Heat/Vent control (Passenger)";
CM_ BO_ 371 "[PE] Periodic and On Event";
CM_ SG_ 371 HU_AliveStatus "Information of the status of Head Unit
0x00 : Headunit is booting so, Headunit cant display any state
0x01 : Headunit is normal state, Headunit could display according to MM CAN  command.
0x02 : Headunit is doing their internal process, so Headunit cant communicate with other node.
For CLU/SCC/eCall
-AVN System transmission signal";
CM_ SG_ 371 HU_DistanceUnit "Request to set CLU Distance Unit";
CM_ SG_ 371 HU_TempUnit "Request to set DATC/CLU temperature unit";
CM_ SG_ 371 CAM_Request "HU command for AHD(Analog High Definition) camera to show different view screen";
CM_ SG_ 371 CF_AVN_ProfileIDRValue "This signal is User ID value in H/Unit.";
CM_ BO_ 372 "[PE] Periodic and On Event";
CM_ SG_ 372 HU_TeleSoCAlertValueSet "Alert reference value. The resolution is 1%.";
CM_ SG_ 372 HU_TeleVehicleStatusReq "Request vehicle status information.";
CM_ BO_ 1928 "[TP] TP Message";
CM_ SG_ 1928 Byte0_TCP_788 "Diagnosis Response to external tester through CGW";
CM_ SG_ 1928 Byte1_Data_788 "Diagnosis Response to external tester through CGW";
CM_ SG_ 1928 Byte2_Data_788 "Diagnosis Response to external tester through CGW";
CM_ SG_ 1928 Byte3_Data_788 "Diagnosis Response to external tester through CGW";
CM_ SG_ 1928 Byte4_Data_788 "Diagnosis Response to external tester through CGW";
CM_ SG_ 1928 Byte5_Data_788 "Diagnosis Response to external tester through CGW";
CM_ SG_ 1928 Byte6_Data_788 "Diagnosis Response to external tester through CGW";
CM_ SG_ 1928 Byte7_Data_788 "Diagnosis Response to external tester through CGW";
CM_ BO_ 1272 "[TP] TP Message";
CM_ BO_ 1157 "[TP] TP Message";
CM_ BO_ 1179 "[TP] TP Message";
CM_ BO_ 1168 "[TP] TP Message";
CM_ BO_ 1101 "NM Message";
CM_ BO_ 1088 "NM Message";
CM_ BO_ 1109 "NM Message";
BA_DEF_ SG_ "Gatewaysignal" ENUM "No","M-B","B-M","M-C","C-M","M-C-B" ;
BA_DEF_ SG_ "GenSigEnvVarType" ENUM "Int","Float","undef" ;
BA_DEF_ SG_ "GenSigSendType" ENUM "Cyclic","OnWrite","OnWriteWithRepetition","OnChange","OnChangeWithRepetition","IfActive","IfActiveWithRepetition","NoSigSendType" ;
BA_DEF_ SG_ "GenSigStartValue" INT 0 0 ;
BA_DEF_ SG_ "GwSigLatencyTime" INT 0 65535 ;
BA_DEF_ SG_ "GwSigMissingSourceType" ENUM "Undef","OldValue","DefaultValue","InitialValue" ;
BA_DEF_ SG_ "NmNetworkRequest" ENUM "No","Yes" ;
BA_DEF_ SG_ "NmNetworkRequestHoldingTime" INT 0 65535 ;
BA_DEF_ SG_ "Purpose" ENUM "<t.b.d.>","Function","Diagnostic","Development","NM" ;
BA_DEF_ SG_ "SignalCategory" HEX 10 15 ;
BA_DEF_ SG_ "TimeoutValue" STRING ;
BA_DEF_ SG_ "UpdateRateMax" INT 0 0 ;
BA_DEF_ SG_ "UpdateRateMin" INT 0 0 ;
BA_DEF_ SG_ "Validity" ENUM "B+","ACC","IGN1","IGN2" ;
BA_DEF_ BO_ "DiagRequest" ENUM "No","Yes" ;
BA_DEF_ BO_ "DiagResponse" ENUM "No","Yes" ;
BA_DEF_ BO_ "DiagState" ENUM "No","Yes" ;
BA_DEF_ BO_ "GenMsgCycleTime" INT 0 100000 ;
BA_DEF_ BO_ "GenMsgCycleTimeFast" INT 0 500 ;
BA_DEF_ BO_ "GenMsgDelayTime" INT 0 20 ;
BA_DEF_ BO_ "GenMsgEVName" STRING ;
BA_DEF_ BO_ "GenMsgILSupport" ENUM "No","Yes" ;
BA_DEF_ BO_ "GenMsgNrOfRepetition" INT 0 3 ;
BA_DEF_ BO_ "GenMsgSendType" ENUM "Cyclic","not_used","not_used","not_used","not_used","not_used","not_used","not_used","NoMsgSendType" ;
BA_DEF_ BO_ "GenMsgStartDelayTime" INT 0 2000 ;
BA_DEF_ BO_ "NmMessage" ENUM "No","Yes" ;
BA_DEF_ BO_ "RoutingType" ENUM "<n.a.>","Direct","Indirect" ;
BA_DEF_ BO_ "TpMessage" ENUM "No","Yes" ;
BA_DEF_ BO_ "TpTxIndex" INT 0 255 ;
BA_DEF_ SG_ "SigDescription" STRING ;
BA_DEF_ SG_ "Platform" STRING ;
BA_DEF_ SG_ "SigOldType" ENUM "No","Yes" ;
BA_DEF_REL_ BU_SG_REL_ "GenSigTimeoutTime" INT 0 7000 ;
BA_DEF_DEF_ "Gatewaysignal" "No" ;
BA_DEF_DEF_ "GenSigEnvVarType" "undef" ;
BA_DEF_DEF_ "GenSigSendType" "NoSigSendType" ;
BA_DEF_DEF_ "GenSigStartValue" 0 ;
BA_DEF_DEF_ "GwSigLatencyTime" 40 ;
BA_DEF_DEF_ "GwSigMissingSourceType" "Undef" ;
BA_DEF_DEF_ "NmNetworkRequest" "No" ;
BA_DEF_DEF_ "NmNetworkRequestHoldingTime" 0 ;
BA_DEF_DEF_ "Purpose" "<t.b.d.>" ;
BA_DEF_DEF_ "SignalCategory" 12 ;
BA_DEF_DEF_ "TimeoutValue" "" ;
BA_DEF_DEF_ "UpdateRateMax" 0 ;
BA_DEF_DEF_ "UpdateRateMin" 0 ;
BA_DEF_DEF_ "Validity" "ACC" ;
BA_DEF_DEF_ "DiagRequest" "No" ;
BA_DEF_DEF_ "DiagResponse" "No" ;
BA_DEF_DEF_ "DiagState" "No" ;
BA_DEF_DEF_ "GenMsgCycleTime" 0 ;
BA_DEF_DEF_ "GenMsgCycleTimeFast" 0 ;
BA_DEF_DEF_ "GenMsgDelayTime" 20 ;
BA_DEF_DEF_ "GenMsgEVName" "@Signame" ;
BA_DEF_DEF_ "GenMsgILSupport" "Yes" ;
BA_DEF_DEF_ "GenMsgNrOfRepetition" 0 ;
BA_DEF_DEF_ "GenMsgSendType" "NoMsgSendType" ;
BA_DEF_DEF_ "GenMsgStartDelayTime" 0 ;
BA_DEF_DEF_ "NmMessage" "No" ;
BA_DEF_DEF_ "RoutingType" "<n.a.>" ;
BA_DEF_DEF_ "TpMessage" "No" ;
BA_DEF_DEF_ "TpTxIndex" 0 ;
BA_DEF_DEF_ "SigDescription" "" ;
BA_DEF_DEF_ "Platform" "Standard AVN 4.0,Standard Audio 3.0,Premium AVN 3.0" ;
BA_DEF_DEF_ "SigOldType" "No" ;
BA_DEF_DEF_REL_ "GenSigTimeoutTime" 700 ;
BA_ "GenMsgSendType" BO_ 1329 0;
BA_ "GenMsgCycleTime" BO_ 1329 1000;
BA_ "GenMsgStartDelayTime" BO_ 1329 350;
BA_REL_ "GenSigTimeoutTime" BU_SG_REL_ H_U SG_ 1329 DATC_AmbientTempC 3500;
BA_ "Platform" SG_ 1329 DATC_AmbientTempC "";
BA_ "GenSigStartValue" SG_ 1329 DATC_AmbientTempC 255;
BA_ "Gatewaysignal" SG_ 1329 DATC_AmbientTempC 4;
BA_ "TimeoutValue" SG_ 1329 DATC_AmbientTempC "Old Value";
BA_ "Validity" SG_ 1329 DATC_AmbientTempC 2;
BA_REL_ "GenSigTimeoutTime" BU_SG_REL_ H_U SG_ 1329 DATC_AmbientTempF 3500;
BA_ "Platform" SG_ 1329 DATC_AmbientTempF "";
BA_ "GenSigStartValue" SG_ 1329 DATC_AmbientTempF 255;
BA_ "Gatewaysignal" SG_ 1329 DATC_AmbientTempF 4;
BA_ "TimeoutValue" SG_ 1329 DATC_AmbientTempF "Old Value";
BA_ "Validity" SG_ 1329 DATC_AmbientTempF 2;
BA_ "GenMsgSendType" BO_ 336 0;
BA_ "GenMsgCycleTime" BO_ 336 200;
BA_ "GenMsgStartDelayTime" BO_ 336 110;
BA_ "SigDescription" SG_ 336 ANC_EngineCHR "1. For the automatic variant coding at E.O.L : This signal value is valid 1.5sec later from initial IG-ON
2. In case of Delphi ECU, Output period tolerance(+1ms) will be applied to Engine Lamda3.";
BA_ "Platform" SG_ 336 ANC_EngineCHR "";
BA_ "GenSigSendType" SG_ 336 ANC_EngineCHR 3;
BA_ "Gatewaysignal" SG_ 336 ANC_EngineCHR 4;
BA_ "TimeoutValue" SG_ 336 ANC_EngineCHR "old value";
BA_ "Validity" SG_ 336 ANC_EngineCHR 2;
BA_ "GenMsgSendType" BO_ 361 0;
BA_ "GenMsgCycleTime" BO_ 361 200;
BA_ "GenMsgStartDelayTime" BO_ 361 110;
BA_ "Platform" SG_ 361 C_Inhibit_State "";
BA_ "GenSigSendType" SG_ 361 C_Inhibit_State 3;
BA_ "GenSigStartValue" SG_ 361 C_Inhibit_State 15;
BA_ "TimeoutValue" SG_ 361 C_Inhibit_State "0xF";
BA_ "Validity" SG_ 361 C_Inhibit_State 2;
BA_REL_ "GenSigTimeoutTime" BU_SG_REL_ H_U SG_ 361 TCU_TYPE 500;
BA_ "Platform" SG_ 361 TCU_TYPE "";
BA_ "GenSigSendType" SG_ 361 TCU_TYPE 3;
BA_ "Gatewaysignal" SG_ 361 TCU_TYPE 4;
BA_ "TimeoutValue" SG_ 361 TCU_TYPE "Old Value";
BA_ "Validity" SG_ 361 TCU_TYPE 2;
BA_ "Purpose" SG_ 361 ENG_STAT 1;
BA_REL_ "GenSigTimeoutTime" BU_SG_REL_ H_U SG_ 361 ENG_STAT 500;
BA_ "SigDescription" SG_ 361 ENG_STAT "In case of Delphi ECU, Output period tolerance(+1ms) will be applied to Engine Lamda3.
* ISG Applied vehicles should consider CF_Ems_IgsStat and CF_Ems_IgsStat2 signals for check alternator status ALT_L.
- If ENG_STAT is 0x3, ALT_L is On
- If ENG_STAT is not 0x3 and CF_Ems_IgsStat is 0x0 or 0x3~6, then ALT_L is off,
- If ENG_STAT is not 0x3 and CF_Ems_IgsStat2 is 0x0, 0x1 or 0x3, then ALT_L is off.
- If ENG_STAT and other signal values are diffrent from above, ALT_L is On.";
BA_ "Platform" SG_ 361 ENG_STAT "D-Audio,Integrated AVN1.0 High,Integrated AVN1.0 Mid,Standard AVN 4.0,Compact AVN";
BA_ "GenSigSendType" SG_ 361 ENG_STAT 3;
BA_ "Gatewaysignal" SG_ 361 ENG_STAT 4;
BA_ "Validity" SG_ 361 ENG_STAT 2;
BA_ "Purpose" SG_ 361 CF_Ems_IsgStat 1;
BA_REL_ "GenSigTimeoutTime" BU_SG_REL_ H_U SG_ 361 CF_Ems_IsgStat 500;
BA_ "SigDescription" SG_ 361 CF_Ems_IsgStat "In case of Delphi ECU, Output period tolerance(+1ms) will be applied to Engine Lamda3.
* ISG Applied vehicles should consider CF_Ems_IgsStat and CF_Ems_IgsStat2 signals for check alternator status ALT_L.
- If ENG_STAT is 0x3, ALT_L is On
- If ENG_STAT is not 0x3 and CF_Ems_IgsStat is 0x0 or 0x3~6, then ALT_L is off,
- If ENG_STAT is not 0x3 and CF_Ems_IgsStat2 is 0x0, 0x1 or 0x3, then ALT_L is off.
- If ENG_STAT and other signal values are diffrent from above, ALT_L is On.";
BA_ "Platform" SG_ 361 CF_Ems_IsgStat "Compact AVN,D-Audio,Integrated AVN1.0 High,Integrated AVN1.0 Mid,Standard AVN 4.0";
BA_ "GenSigSendType" SG_ 361 CF_Ems_IsgStat 3;
BA_ "Gatewaysignal" SG_ 361 CF_Ems_IsgStat 4;
BA_ "Validity" SG_ 361 CF_Ems_IsgStat 2;
BA_ "Purpose" SG_ 361 CF_Ems_IsgStat2 1;
BA_REL_ "GenSigTimeoutTime" BU_SG_REL_ H_U SG_ 361 CF_Ems_IsgStat2 500;
BA_ "SigDescription" SG_ 361 CF_Ems_IsgStat2 "In case of Delphi ECU, Output period tolerance(+1ms) will be applied to Engine Lamda3.
* ISG Applied vehicles should consider CF_Ems_IgsStat and CF_Ems_IgsStat2 signals for check alternator status ALT_L.
- If ENG_STAT is 0x3, ALT_L is On
- If ENG_STAT is not 0x3 and CF_Ems_IgsStat is 0x0 or 0x3~6, then ALT_L is off,
- If ENG_STAT is not 0x3 and CF_Ems_IgsStat2 is 0x0, 0x1 or 0x3, then ALT_L is off.
- If ENG_STAT and other signal values are diffrent from above, ALT_L is On.";
BA_ "Platform" SG_ 361 CF_Ems_IsgStat2 "Compact AVN,D-Audio,Integrated AVN1.0 High,Integrated AVN1.0 Mid,Standard AVN 4.0";
BA_ "GenSigSendType" SG_ 361 CF_Ems_IsgStat2 3;
BA_ "Validity" SG_ 361 CF_Ems_IsgStat2 2;
BA_ "Purpose" SG_ 361 BAT_SOC 1;
BA_REL_ "GenSigTimeoutTime" BU_SG_REL_ H_U SG_ 361 BAT_SOC 500;
BA_ "Platform" SG_ 361 BAT_SOC "Compact AVN,D-Audio,DIS 2,Economic Audio 3.0,Integrated AVN1.0 High,Integrated AVN1.0 Mid,Premium AVN 2.0,Standard AVN 4.0,Standard Audio 3.0,Standard Audio 4.0,UVO3 (D-Audio Kia)";
BA_ "GenSigSendType" SG_ 361 BAT_SOC 3;
BA_ "Gatewaysignal" SG_ 361 BAT_SOC 4;
BA_ "TimeoutValue" SG_ 361 BAT_SOC "0xFF";
BA_ "Validity" SG_ 361 BAT_SOC 2;
BA_ "Purpose" SG_ 361 BAT_SNSR_Error 1;
BA_REL_ "GenSigTimeoutTime" BU_SG_REL_ H_U SG_ 361 BAT_SNSR_Error 500;
BA_ "Platform" SG_ 361 BAT_SNSR_Error "Compact AVN,D-Audio,DIS 2,Economic Audio 3.0,Integrated AVN1.0 High,Integrated AVN1.0 Mid,Premium AVN 2.0,Standard AVN 4.0,Standard Audio 3.0,Standard Audio 4.0,UVO3 (D-Audio Kia)";
BA_ "GenSigSendType" SG_ 361 BAT_SNSR_Error 3;
BA_ "GenSigStartValue" SG_ 361 BAT_SNSR_Error 3;
BA_ "Gatewaysignal" SG_ 361 BAT_SNSR_Error 4;
BA_ "TimeoutValue" SG_ 361 BAT_SNSR_Error "0x3";
BA_ "Validity" SG_ 361 BAT_SNSR_Error 2;
BA_ "Purpose" SG_ 361 BAT_SNSR_State 1;
BA_REL_ "GenSigTimeoutTime" BU_SG_REL_ H_U SG_ 361 BAT_SNSR_State 500;
BA_ "Platform" SG_ 361 BAT_SNSR_State "Compact AVN,D-Audio,DIS 2,Economic Audio 3.0,Integrated AVN1.0 High,Integrated AVN1.0 Mid,Premium AVN 2.0,Standard AVN 4.0,Standard Audio 3.0,Standard Audio 4.0,UVO3 (D-Audio Kia)";
BA_ "GenSigSendType" SG_ 361 BAT_SNSR_State 3;
BA_ "GenSigStartValue" SG_ 361 BAT_SNSR_State 3;
BA_ "Gatewaysignal" SG_ 361 BAT_SNSR_State 4;
BA_ "TimeoutValue" SG_ 361 BAT_SNSR_State "0x3";
BA_ "Validity" SG_ 361 BAT_SNSR_State 2;
BA_ "Purpose" SG_ 361 BAT_SNSR_Invalid 1;
BA_REL_ "GenSigTimeoutTime" BU_SG_REL_ H_U SG_ 361 BAT_SNSR_Invalid 500;
BA_ "Platform" SG_ 361 BAT_SNSR_Invalid "Compact AVN,D-Audio,DIS 2,Economic Audio 3.0,Integrated AVN1.0 High,Integrated AVN1.0 Mid,Premium AVN 2.0,Standard AVN 4.0,Standard Audio 3.0,Standard Audio 4.0,UVO3 (D-Audio Kia)";
BA_ "GenSigSendType" SG_ 361 BAT_SNSR_Invalid 3;
BA_ "GenSigStartValue" SG_ 361 BAT_SNSR_Invalid 3;
BA_ "Gatewaysignal" SG_ 361 BAT_SNSR_Invalid 4;
BA_ "TimeoutValue" SG_ 361 BAT_SNSR_Invalid "0x3";
BA_ "Validity" SG_ 361 BAT_SNSR_Invalid 2;
BA_ "Purpose" SG_ 361 AVH_LAMP 1;
BA_REL_ "GenSigTimeoutTime" BU_SG_REL_ H_U SG_ 361 AVH_LAMP 500;
BA_ "SigDescription" SG_ 361 AVH_LAMP "This message is for “EPB (Electric Parking Brake)” system applied vehicle only.";
BA_ "Platform" SG_ 361 AVH_LAMP "Compact AVN,D-Audio,DIS 2,Economic Audio 3.0,Integrated AVN1.0 High,Integrated AVN1.0 Mid,Premium AVN 2.0,Standard AVN 4.0,Standard Audio 3.0,Standard Audio 4.0,UVO3 (D-Audio Kia)";
BA_ "GenSigSendType" SG_ 361 AVH_LAMP 3;
BA_ "TimeoutValue" SG_ 361 AVH_LAMP "0x7";
BA_ "Validity" SG_ 361 AVH_LAMP 2;
BA_ "Purpose" SG_ 361 EPB_STATUS 1;
BA_REL_ "GenSigTimeoutTime" BU_SG_REL_ H_U SG_ 361 EPB_STATUS 500;
BA_ "Platform" SG_ 361 EPB_STATUS "";
BA_ "GenSigSendType" SG_ 361 EPB_STATUS 3;
BA_ "Validity" SG_ 361 EPB_STATUS 2;
BA_ "GenMsgSendType" BO_ 344 0;
BA_ "GenMsgCycleTime" BO_ 344 200;
BA_ "GenMsgStartDelayTime" BO_ 344 120;
BA_ "Platform" SG_ 344 CF_Clu_LowfuelWarning "";
BA_ "GenSigSendType" SG_ 344 CF_Clu_LowfuelWarning 3;
BA_ "GenSigStartValue" SG_ 344 CF_Clu_LowfuelWarning 3;
BA_ "Gatewaysignal" SG_ 344 CF_Clu_LowfuelWarning 4;
BA_ "TimeoutValue" SG_ 344 CF_Clu_LowfuelWarning "Old Value";
BA_ "Platform" SG_ 344 C_InhibitRMT "";
BA_ "GenSigSendType" SG_ 344 C_InhibitRMT 3;
BA_ "GenSigStartValue" SG_ 344 C_InhibitRMT 3;
BA_ "Gatewaysignal" SG_ 344 C_InhibitRMT 2;
BA_ "TimeoutValue" SG_ 344 C_InhibitRMT "Old Value";
BA_ "Validity" SG_ 344 C_InhibitRMT 2;
BA_ "GenMsgSendType" BO_ 362 0;
BA_ "GenMsgCycleTime" BO_ 362 200;
BA_ "GenMsgStartDelayTime" BO_ 362 90;
BA_ "Platform" SG_ 362 C_AV_Tail "";
BA_ "GenSigSendType" SG_ 362 C_AV_Tail 3;
BA_ "GenSigStartValue" SG_ 362 C_AV_Tail 3;
BA_ "Gatewaysignal" SG_ 362 C_AV_Tail 4;
BA_ "TimeoutValue" SG_ 362 C_AV_Tail "0x3";
BA_ "GenMsgNrOfRepetition" BO_ 362 3;
BA_ "GenMsgCycleTimeFast" BO_ 362 40;
BA_REL_ "GenSigTimeoutTime" BU_SG_REL_ CLU SG_ 362 C_IGN2 1500;
BA_REL_ "GenSigTimeoutTime" BU_SG_REL_ H_U SG_ 362 C_IGN2 1500;
BA_ "Platform" SG_ 362 C_IGN2 "";
BA_ "GenSigSendType" SG_ 362 C_IGN2 4;
BA_ "GenSigStartValue" SG_ 362 C_IGN2 3;
BA_ "Gatewaysignal" SG_ 362 C_IGN2 2;
BA_ "NmNetworkRequest" SG_ 362 C_IGN2 1;
BA_ "TimeoutValue" SG_ 362 C_IGN2 "0x3";
BA_ "Validity" SG_ 362 C_IGN2 0;
BA_REL_ "GenSigTimeoutTime" BU_SG_REL_ H_U SG_ 362 C_WlightOn 1500;
BA_ "SigDescription" SG_ 362 C_WlightOn "0x0 : Welcome Light OFF
0x1 : Welcome Light ON
0x2 : Reserved
0x3 : Invalid";
BA_ "Platform" SG_ 362 C_WlightOn "";
BA_ "GenSigSendType" SG_ 362 C_WlightOn 4;
BA_ "Gatewaysignal" SG_ 362 C_WlightOn 2;
BA_ "NmNetworkRequest" SG_ 362 C_WlightOn 1;
BA_ "Validity" SG_ 362 C_WlightOn 0;
BA_ "GenMsgSendType" BO_ 350 0;
BA_ "GenMsgCycleTime" BO_ 350 200;
BA_ "GenMsgCycleTimeFast" BO_ 350 40;
BA_ "GenMsgNrOfRepetition" BO_ 350 3;
BA_ "GenMsgStartDelayTime" BO_ 350 60;
BA_REL_ "GenSigTimeoutTime" BU_SG_REL_ H_U SG_ 350 C_BAlarmState 1500;
BA_ "Platform" SG_ 350 C_BAlarmState "";
BA_ "GenSigSendType" SG_ 350 C_BAlarmState 4;
BA_ "Gatewaysignal" SG_ 350 C_BAlarmState 2;
BA_ "NmNetworkRequest" SG_ 350 C_BAlarmState 1;
BA_ "NmNetworkRequestHoldingTime" SG_ 350 C_BAlarmState 2;
BA_ "TimeoutValue" SG_ 350 C_BAlarmState "0x0";
BA_ "Validity" SG_ 350 C_BAlarmState 0;
BA_REL_ "GenSigTimeoutTime" BU_SG_REL_ H_U SG_ 350 TMU_RmtEngRunSta 1500;
BA_ "Platform" SG_ 350 TMU_RmtEngRunSta "";
BA_ "GenSigSendType" SG_ 350 TMU_RmtEngRunSta 4;
BA_ "Gatewaysignal" SG_ 350 TMU_RmtEngRunSta 2;
BA_ "NmNetworkRequest" SG_ 350 TMU_RmtEngRunSta 1;
BA_ "NmNetworkRequestHoldingTime" SG_ 350 TMU_RmtEngRunSta 2;
BA_ "TimeoutValue" SG_ 350 TMU_RmtEngRunSta "0x3";
BA_ "Validity" SG_ 350 TMU_RmtEngRunSta 0;
BA_REL_ "GenSigTimeoutTime" BU_SG_REL_ H_U SG_ 350 C_PpositionClutch 1500;
BA_ "SigDescription" SG_ 350 C_PpositionClutch "텔레매틱스 원격시동실패사유알림 용도";
BA_ "Platform" SG_ 350 C_PpositionClutch "D-Audio,Integrated AVN1.0 High,Premium AVN 2.0,UVO3 (D-Audio Kia)";
BA_ "GenSigSendType" SG_ 350 C_PpositionClutch 3;
BA_ "GenSigStartValue" SG_ 350 C_PpositionClutch 3;
BA_ "Gatewaysignal" SG_ 350 C_PpositionClutch 2;
BA_ "TimeoutValue" SG_ 350 C_PpositionClutch "0x3";
BA_ "Validity" SG_ 350 C_PpositionClutch 0;
BA_REL_ "GenSigTimeoutTime" BU_SG_REL_ H_U SG_ 350 C_HoodSw 1500;
BA_ "Platform" SG_ 350 C_HoodSw "";
BA_ "GenSigSendType" SG_ 350 C_HoodSw 3;
BA_ "GenSigStartValue" SG_ 350 C_HoodSw 3;
BA_ "Gatewaysignal" SG_ 350 C_HoodSw 2;
BA_ "TimeoutValue" SG_ 350 C_HoodSw "0x3";
BA_ "Validity" SG_ 350 C_HoodSw 0;
BA_REL_ "GenSigTimeoutTime" BU_SG_REL_ H_U SG_ 350 C_DefoggerRly 1500;
BA_ "SigDescription" SG_ 350 C_DefoggerRly "Use for Telematics Remote Heating Control";
BA_ "Platform" SG_ 350 C_DefoggerRly "Integrated AVN1.0 High,Premium AVN 2.0,D-Audio,UVO3 (D-Audio Kia)";
BA_ "GenSigSendType" SG_ 350 C_DefoggerRly 3;
BA_ "GenSigStartValue" SG_ 350 C_DefoggerRly 3;
BA_ "Gatewaysignal" SG_ 350 C_DefoggerRly 2;
BA_ "SignalCategory" SG_ 350 C_DefoggerRly 10;
BA_ "TimeoutValue" SG_ 350 C_DefoggerRly "0x3";
BA_ "Validity" SG_ 350 C_DefoggerRly 0;
BA_REL_ "GenSigTimeoutTime" BU_SG_REL_ H_U SG_ 350 C_WPCWarning 1500;
BA_ "Platform" SG_ 350 C_WPCWarning "";
BA_ "GenSigSendType" SG_ 350 C_WPCWarning 3;
BA_ "Gatewaysignal" SG_ 350 C_WPCWarning 2;
BA_ "TimeoutValue" SG_ 350 C_WPCWarning "0x7";
BA_ "GenMsgSendType" BO_ 383 0;
BA_ "GenMsgCycleTime" BO_ 383 200;
BA_ "GenMsgCycleTimeFast" BO_ 383 40;
BA_ "GenMsgNrOfRepetition" BO_ 383 3;
BA_ "GenMsgStartDelayTime" BO_ 383 100;
BA_REL_ "GenSigTimeoutTime" BU_SG_REL_ H_U SG_ 383 Warn_DrvDrSwSta 1500;
BA_ "Platform" SG_ 383 Warn_DrvDrSwSta "";
BA_ "GenSigSendType" SG_ 383 Warn_DrvDrSwSta 4;
BA_ "GenSigStartValue" SG_ 383 Warn_DrvDrSwSta 3;
BA_ "NmNetworkRequest" SG_ 383 Warn_DrvDrSwSta 1;
BA_ "NmNetworkRequestHoldingTime" SG_ 383 Warn_DrvDrSwSta 2;
BA_ "TimeoutValue" SG_ 383 Warn_DrvDrSwSta "0x3";
BA_ "Validity" SG_ 383 Warn_DrvDrSwSta 0;
BA_REL_ "GenSigTimeoutTime" BU_SG_REL_ H_U SG_ 383 Warn_AsstDrSwSta 1500;
BA_ "Platform" SG_ 383 Warn_AsstDrSwSta "";
BA_ "GenSigSendType" SG_ 383 Warn_AsstDrSwSta 3;
BA_ "GenSigStartValue" SG_ 383 Warn_AsstDrSwSta 3;
BA_ "TimeoutValue" SG_ 383 Warn_AsstDrSwSta "0x3";
BA_ "Validity" SG_ 383 Warn_AsstDrSwSta 0;
BA_REL_ "GenSigTimeoutTime" BU_SG_REL_ H_U SG_ 383 Warn_RrLftDrSwSta 1500;
BA_ "Platform" SG_ 383 Warn_RrLftDrSwSta "";
BA_ "GenSigSendType" SG_ 383 Warn_RrLftDrSwSta 3;
BA_ "GenSigStartValue" SG_ 383 Warn_RrLftDrSwSta 3;
BA_ "TimeoutValue" SG_ 383 Warn_RrLftDrSwSta "0x3";
BA_ "Validity" SG_ 383 Warn_RrLftDrSwSta 0;
BA_REL_ "GenSigTimeoutTime" BU_SG_REL_ H_U SG_ 383 Warn_RrRtDrSwSta 1500;
BA_ "Platform" SG_ 383 Warn_RrRtDrSwSta "";
BA_ "GenSigSendType" SG_ 383 Warn_RrRtDrSwSta 3;
BA_ "GenSigStartValue" SG_ 383 Warn_RrRtDrSwSta 3;
BA_ "TimeoutValue" SG_ 383 Warn_RrRtDrSwSta "0x3";
BA_ "Validity" SG_ 383 Warn_RrRtDrSwSta 0;
BA_REL_ "GenSigTimeoutTime" BU_SG_REL_ H_U SG_ 383 DoorLock_DrvDrUnLkSta 1500;
BA_ "Platform" SG_ 383 DoorLock_DrvDrUnLkSta "";
BA_ "GenSigSendType" SG_ 383 DoorLock_DrvDrUnLkSta 4;
BA_ "GenSigStartValue" SG_ 383 DoorLock_DrvDrUnLkSta 3;
BA_ "NmNetworkRequest" SG_ 383 DoorLock_DrvDrUnLkSta 1;
BA_ "NmNetworkRequestHoldingTime" SG_ 383 DoorLock_DrvDrUnLkSta 2;
BA_ "TimeoutValue" SG_ 383 DoorLock_DrvDrUnLkSta "0x3";
BA_ "Validity" SG_ 383 DoorLock_DrvDrUnLkSta 0;
BA_REL_ "GenSigTimeoutTime" BU_SG_REL_ H_U SG_ 383 DoorLock_AsstDrUnLkSta 1500;
BA_ "Platform" SG_ 383 DoorLock_AsstDrUnLkSta "";
BA_ "GenSigSendType" SG_ 383 DoorLock_AsstDrUnLkSta 3;
BA_ "GenSigStartValue" SG_ 383 DoorLock_AsstDrUnLkSta 3;
BA_ "TimeoutValue" SG_ 383 DoorLock_AsstDrUnLkSta "0x3";
BA_ "Validity" SG_ 383 DoorLock_AsstDrUnLkSta 0;
BA_REL_ "GenSigTimeoutTime" BU_SG_REL_ H_U SG_ 383 DoorLock_RrLftDrUnLkSta 1500;
BA_ "Platform" SG_ 383 DoorLock_RrLftDrUnLkSta "";
BA_ "GenSigSendType" SG_ 383 DoorLock_RrLftDrUnLkSta 3;
BA_ "GenSigStartValue" SG_ 383 DoorLock_RrLftDrUnLkSta 3;
BA_ "TimeoutValue" SG_ 383 DoorLock_RrLftDrUnLkSta "0x3";
BA_ "Validity" SG_ 383 DoorLock_RrLftDrUnLkSta 0;
BA_REL_ "GenSigTimeoutTime" BU_SG_REL_ H_U SG_ 383 DoorLock_RrRtDrUnLkSta 1500;
BA_ "Platform" SG_ 383 DoorLock_RrRtDrUnLkSta "";
BA_ "GenSigSendType" SG_ 383 DoorLock_RrRtDrUnLkSta 3;
BA_ "GenSigStartValue" SG_ 383 DoorLock_RrRtDrUnLkSta 3;
BA_ "TimeoutValue" SG_ 383 DoorLock_RrRtDrUnLkSta "0x3";
BA_ "Validity" SG_ 383 DoorLock_RrRtDrUnLkSta 0;
BA_REL_ "GenSigTimeoutTime" BU_SG_REL_ H_U SG_ 383 Trunk_TrnkTlgtSwSta 1500;
BA_ "Platform" SG_ 383 Trunk_TrnkTlgtSwSta "";
BA_ "GenSigSendType" SG_ 383 Trunk_TrnkTlgtSwSta 3;
BA_ "GenSigStartValue" SG_ 383 Trunk_TrnkTlgtSwSta 3;
BA_ "TimeoutValue" SG_ 383 Trunk_TrnkTlgtSwSta "0x3";
BA_ "Validity" SG_ 383 Trunk_TrnkTlgtSwSta 0;
BA_REL_ "GenSigTimeoutTime" BU_SG_REL_ H_U SG_ 383 Warn_SunRoofOpnSta 1500;
BA_ "Platform" SG_ 383 Warn_SunRoofOpnSta "";
BA_ "GenSigSendType" SG_ 383 Warn_SunRoofOpnSta 3;
BA_ "GenSigStartValue" SG_ 383 Warn_SunRoofOpnSta 3;
BA_ "TimeoutValue" SG_ 383 Warn_SunRoofOpnSta "0x3";
BA_ "Validity" SG_ 383 Warn_SunRoofOpnSta 0;
BA_REL_ "GenSigTimeoutTime" BU_SG_REL_ H_U SG_ 383 BAlarm_PncAlrmReq 1500;
BA_ "Platform" SG_ 383 BAlarm_PncAlrmReq "";
BA_ "GenSigSendType" SG_ 383 BAlarm_PncAlrmReq 4;
BA_ "GenSigStartValue" SG_ 383 BAlarm_PncAlrmReq 3;
BA_ "NmNetworkRequest" SG_ 383 BAlarm_PncAlrmReq 1;
BA_ "NmNetworkRequestHoldingTime" SG_ 383 BAlarm_PncAlrmReq 2;
BA_ "TimeoutValue" SG_ 383 BAlarm_PncAlrmReq "0x3";
BA_ "Validity" SG_ 383 BAlarm_PncAlrmReq 0;
BA_REL_ "GenSigTimeoutTime" BU_SG_REL_ H_U SG_ 383 Lamp_AutoLtSnsrNightSta 1500;
BA_ "Platform" SG_ 383 Lamp_AutoLtSnsrNightSta "";
BA_ "GenSigSendType" SG_ 383 Lamp_AutoLtSnsrNightSta 3;
BA_ "GenSigStartValue" SG_ 383 Lamp_AutoLtSnsrNightSta 3;
BA_ "TimeoutValue" SG_ 383 Lamp_AutoLtSnsrNightSta "0x3";
BA_REL_ "GenSigTimeoutTime" BU_SG_REL_ H_U SG_ 383 ExtLamp_ExtrnlTailLmpSta 1500;
BA_ "Platform" SG_ 383 ExtLamp_ExtrnlTailLmpSta "";
BA_ "GenSigSendType" SG_ 383 ExtLamp_ExtrnlTailLmpSta 3;
BA_ "GenSigStartValue" SG_ 383 ExtLamp_ExtrnlTailLmpSta 3;
BA_ "TimeoutValue" SG_ 383 ExtLamp_ExtrnlTailLmpSta "0x3";
BA_ "Validity" SG_ 383 ExtLamp_ExtrnlTailLmpSta 2;
BA_REL_ "GenSigTimeoutTime" BU_SG_REL_ H_U SG_ 383 ExtLamp_FrFgLmpSta 1500;
BA_ "Platform" SG_ 383 ExtLamp_FrFgLmpSta "";
BA_ "GenSigSendType" SG_ 383 ExtLamp_FrFgLmpSta 3;
BA_ "GenSigStartValue" SG_ 383 ExtLamp_FrFgLmpSta 3;
BA_ "TimeoutValue" SG_ 383 ExtLamp_FrFgLmpSta "0x3";
BA_ "Validity" SG_ 383 ExtLamp_FrFgLmpSta 2;
BA_REL_ "GenSigTimeoutTime" BU_SG_REL_ H_U SG_ 383 ExtLamp_HdLmpHiSta 1500;
BA_ "Platform" SG_ 383 ExtLamp_HdLmpHiSta "";
BA_ "GenSigSendType" SG_ 383 ExtLamp_HdLmpHiSta 3;
BA_ "GenSigStartValue" SG_ 383 ExtLamp_HdLmpHiSta 3;
BA_ "TimeoutValue" SG_ 383 ExtLamp_HdLmpHiSta "0x3";
BA_ "Validity" SG_ 383 ExtLamp_HdLmpHiSta 2;
BA_REL_ "GenSigTimeoutTime" BU_SG_REL_ H_U SG_ 383 ExtLamp_HdLmpLoSta 1500;
BA_ "Platform" SG_ 383 ExtLamp_HdLmpLoSta "";
BA_ "GenSigSendType" SG_ 383 ExtLamp_HdLmpLoSta 3;
BA_ "GenSigStartValue" SG_ 383 ExtLamp_HdLmpLoSta 3;
BA_ "TimeoutValue" SG_ 383 ExtLamp_HdLmpLoSta "0x3";
BA_ "Validity" SG_ 383 ExtLamp_HdLmpLoSta 2;
BA_REL_ "GenSigTimeoutTime" BU_SG_REL_ H_U SG_ 383 C_DrvWindowOpenState 1500;
BA_ "SigDescription" SG_ 383 C_DrvWindowOpenState "This signal indicates DRV Window Open/Close Status";
BA_ "Platform" SG_ 383 C_DrvWindowOpenState "Integrated AVN1.0 High";
BA_ "GenSigSendType" SG_ 383 C_DrvWindowOpenState 3;
BA_ "GenSigStartValue" SG_ 383 C_DrvWindowOpenState 3;
BA_ "TimeoutValue" SG_ 383 C_DrvWindowOpenState "0X3";
BA_ "Validity" SG_ 383 C_DrvWindowOpenState 0;
BA_REL_ "GenSigTimeoutTime" BU_SG_REL_ H_U SG_ 383 C_FOBBatteryStatusInfo 1500;
BA_ "SigDescription" SG_ 383 C_FOBBatteryStatusInfo "Receive Fob Battery Status for Telematics Vehicle Information Service";
BA_ "Platform" SG_ 383 C_FOBBatteryStatusInfo "Integrated AVN1.0 High";
BA_ "GenSigSendType" SG_ 383 C_FOBBatteryStatusInfo 3;
BA_ "GenSigStartValue" SG_ 383 C_FOBBatteryStatusInfo 3;
BA_ "TimeoutValue" SG_ 383 C_FOBBatteryStatusInfo "0x3";
BA_ "Validity" SG_ 383 C_FOBBatteryStatusInfo 0;
BA_REL_ "GenSigTimeoutTime" BU_SG_REL_ H_U SG_ 383 C_BrakeFluidSw 1500;
BA_ "SigDescription" SG_ 383 C_BrakeFluidSw "Brake oil warning notification (on/off)";
BA_ "Platform" SG_ 383 C_BrakeFluidSw "Integrated AVN1.0 High";
BA_ "GenSigSendType" SG_ 383 C_BrakeFluidSw 3;
BA_ "GenSigStartValue" SG_ 383 C_BrakeFluidSw 3;
BA_ "TimeoutValue" SG_ 383 C_BrakeFluidSw "0x3";
BA_ "Validity" SG_ 383 C_BrakeFluidSw 0;
BA_REL_ "GenSigTimeoutTime" BU_SG_REL_ H_U SG_ 383 C_BCMFobID 1500;
BA_ "Platform" SG_ 383 C_BCMFobID "";
BA_ "GenSigSendType" SG_ 383 C_BCMFobID 3;
BA_ "Gatewaysignal" SG_ 383 C_BCMFobID 2;
BA_ "TimeoutValue" SG_ 383 C_BCMFobID "0x7";
BA_REL_ "GenSigTimeoutTime" BU_SG_REL_ H_U SG_ 383 C_SMKFobID 1500;
BA_ "Platform" SG_ 383 C_SMKFobID "";
BA_ "GenSigSendType" SG_ 383 C_SMKFobID 3;
BA_ "Gatewaysignal" SG_ 383 C_SMKFobID 2;
BA_ "TimeoutValue" SG_ 383 C_SMKFobID "0x7";
BA_ "GenMsgSendType" BO_ 416 0;
BA_ "GenMsgCycleTime" BO_ 416 200;
BA_ "GenMsgStartDelayTime" BO_ 416 30;
BA_REL_ "GenSigTimeoutTime" BU_SG_REL_ H_U SG_ 416 C_DrvWdwErrAntiPinch 1500;
BA_ "Platform" SG_ 416 C_DrvWdwErrAntiPinch "";
BA_ "GenSigSendType" SG_ 416 C_DrvWdwErrAntiPinch 3;
BA_ "GenSigStartValue" SG_ 416 C_DrvWdwErrAntiPinch 1;
BA_ "TimeoutValue" SG_ 416 C_DrvWdwErrAntiPinch "0x3";
BA_REL_ "GenSigTimeoutTime" BU_SG_REL_ H_U SG_ 416 C_DrvWdwDetailOpenState 1500;
BA_ "Platform" SG_ 416 C_DrvWdwDetailOpenState "";
BA_ "GenSigSendType" SG_ 416 C_DrvWdwDetailOpenState 3;
BA_ "GenSigStartValue" SG_ 416 C_DrvWdwDetailOpenState 3;
BA_ "TimeoutValue" SG_ 416 C_DrvWdwDetailOpenState "0x3";
BA_REL_ "GenSigTimeoutTime" BU_SG_REL_ H_U SG_ 416 C_DrvWindowActState 1500;
BA_ "Platform" SG_ 416 C_DrvWindowActState "";
BA_ "GenSigSendType" SG_ 416 C_DrvWindowActState 3;
BA_ "GenSigStartValue" SG_ 416 C_DrvWindowActState 15;
BA_ "TimeoutValue" SG_ 416 C_DrvWindowActState "0xF";
BA_REL_ "GenSigTimeoutTime" BU_SG_REL_ H_U SG_ 416 C_SafetyWDWOpt 1500;
BA_ "Platform" SG_ 416 C_SafetyWDWOpt "";
BA_ "GenSigSendType" SG_ 416 C_SafetyWDWOpt 3;
BA_ "TimeoutValue" SG_ 416 C_SafetyWDWOpt "0x3";
BA_ "GenMsgSendType" BO_ 419 0;
BA_ "GenMsgCycleTime" BO_ 419 200;
BA_ "GenMsgStartDelayTime" BO_ 419 170;
BA_REL_ "GenSigTimeoutTime" BU_SG_REL_ H_U SG_ 419 C_GlassPositionState 1500;
BA_ "Platform" SG_ 419 C_GlassPositionState "";
BA_ "GenSigSendType" SG_ 419 C_GlassPositionState 3;
BA_ "GenSigStartValue" SG_ 419 C_GlassPositionState 15;
BA_ "TimeoutValue" SG_ 419 C_GlassPositionState "0xF";
BA_REL_ "GenSigTimeoutTime" BU_SG_REL_ H_U SG_ 419 C_BlindPositionState 1500;
BA_ "Platform" SG_ 419 C_BlindPositionState "";
BA_ "GenSigSendType" SG_ 419 C_BlindPositionState 3;
BA_ "GenSigStartValue" SG_ 419 C_BlindPositionState 7;
BA_ "TimeoutValue" SG_ 419 C_BlindPositionState "0x7";
BA_REL_ "GenSigTimeoutTime" BU_SG_REL_ H_U SG_ 419 C_GlassErrorState 1500;
BA_ "Platform" SG_ 419 C_GlassErrorState "";
BA_ "GenSigSendType" SG_ 419 C_GlassErrorState 3;
BA_ "TimeoutValue" SG_ 419 C_GlassErrorState "0x7";
BA_REL_ "GenSigTimeoutTime" BU_SG_REL_ H_U SG_ 419 C_BlindErrorState 1500;
BA_ "Platform" SG_ 419 C_BlindErrorState "";
BA_ "GenSigSendType" SG_ 419 C_BlindErrorState 3;
BA_ "TimeoutValue" SG_ 419 C_BlindErrorState "0x7";
BA_REL_ "GenSigTimeoutTime" BU_SG_REL_ H_U SG_ 419 C_SunroofOpt 1500;
BA_ "Platform" SG_ 419 C_SunroofOpt "";
BA_ "GenSigSendType" SG_ 419 C_SunroofOpt 3;
BA_ "TimeoutValue" SG_ 419 C_SunroofOpt "0x3";
BA_REL_ "GenSigTimeoutTime" BU_SG_REL_ H_U SG_ 419 C_SHVU_DiagMode 1500;
BA_ "SigDescription" SG_ 419 C_SHVU_DiagMode "This signal is used for displaying seat diagnosis info on HU engineer mode";
BA_ "Platform" SG_ 419 C_SHVU_DiagMode "";
BA_ "GenSigSendType" SG_ 419 C_SHVU_DiagMode 3;
BA_ "Gatewaysignal" SG_ 419 C_SHVU_DiagMode 2;
BA_ "TimeoutValue" SG_ 419 C_SHVU_DiagMode "Old Value";
BA_ "Validity" SG_ 419 C_SHVU_DiagMode 2;
BA_REL_ "GenSigTimeoutTime" BU_SG_REL_ H_U SG_ 419 C_FL_SeatHeatDTC 1500;
BA_ "SigDescription" SG_ 419 C_FL_SeatHeatDTC "This signal is used for displaying seat diagnosis info on HU engineer mode";
BA_ "Platform" SG_ 419 C_FL_SeatHeatDTC "";
BA_ "GenSigSendType" SG_ 419 C_FL_SeatHeatDTC 3;
BA_ "Gatewaysignal" SG_ 419 C_FL_SeatHeatDTC 2;
BA_ "TimeoutValue" SG_ 419 C_FL_SeatHeatDTC "Old Value";
BA_ "Validity" SG_ 419 C_FL_SeatHeatDTC 2;
BA_REL_ "GenSigTimeoutTime" BU_SG_REL_ H_U SG_ 419 C_FR_SeatHeatDTC 1500;
BA_ "SigDescription" SG_ 419 C_FR_SeatHeatDTC "This signal is for displaying seat diagnosis info on HU engineer mode";
BA_ "Platform" SG_ 419 C_FR_SeatHeatDTC "";
BA_ "GenSigSendType" SG_ 419 C_FR_SeatHeatDTC 3;
BA_ "Gatewaysignal" SG_ 419 C_FR_SeatHeatDTC 2;
BA_ "TimeoutValue" SG_ 419 C_FR_SeatHeatDTC "Old Value";
BA_ "Validity" SG_ 419 C_FR_SeatHeatDTC 2;
BA_ "GenMsgSendType" BO_ 1434 0;
BA_ "GenMsgCycleTime" BO_ 1434 100;
BA_ "Purpose" SG_ 1434 SAS_Angle 1;
BA_REL_ "GenSigTimeoutTime" BU_SG_REL_ H_U SG_ 1434 SAS_Angle 350;
BA_ "Platform" SG_ 1434 SAS_Angle "";
BA_ "GenSigStartValue" SG_ 1434 SAS_Angle 32767;
BA_ "Gatewaysignal" SG_ 1434 SAS_Angle 4;
BA_ "TimeoutValue" SG_ 1434 SAS_Angle "Old Value";
BA_ "Validity" SG_ 1434 SAS_Angle 2;
BA_ "GenMsgSendType" BO_ 358 0;
BA_ "GenMsgCycleTime" BO_ 358 200;
BA_ "GenMsgStartDelayTime" BO_ 358 150;
BA_REL_ "GenSigTimeoutTime" BU_SG_REL_ H_U SG_ 358 C_PASOption 2000;
BA_ "Platform" SG_ 358 C_PASOption "";
BA_ "GenSigSendType" SG_ 358 C_PASOption 3;
BA_ "TimeoutValue" SG_ 358 C_PASOption "Invalid";
BA_REL_ "GenSigTimeoutTime" BU_SG_REL_ H_U SG_ 358 CF_Gway_PasDisplayRCTR 2000;
BA_ "Platform" SG_ 358 CF_Gway_PasDisplayRCTR "";
BA_ "GenSigSendType" SG_ 358 CF_Gway_PasDisplayRCTR 3;
BA_ "TimeoutValue" SG_ 358 CF_Gway_PasDisplayRCTR "0x7";
BA_REL_ "GenSigTimeoutTime" BU_SG_REL_ H_U SG_ 358 CF_Gway_PasDisplayRLH 2000;
BA_ "Platform" SG_ 358 CF_Gway_PasDisplayRLH "";
BA_ "GenSigSendType" SG_ 358 CF_Gway_PasDisplayRLH 3;
BA_ "TimeoutValue" SG_ 358 CF_Gway_PasDisplayRLH "0x7";
BA_REL_ "GenSigTimeoutTime" BU_SG_REL_ H_U SG_ 358 CF_Gway_PasDisplayRRH 2000;
BA_ "Platform" SG_ 358 CF_Gway_PasDisplayRRH "";
BA_ "GenSigSendType" SG_ 358 CF_Gway_PasDisplayRRH 3;
BA_ "TimeoutValue" SG_ 358 CF_Gway_PasDisplayRRH "0x7";
BA_REL_ "GenSigTimeoutTime" BU_SG_REL_ H_U SG_ 358 CF_Gway_PasDisplayDst 2000;
BA_ "SigDescription" SG_ 358 CF_Gway_PasDisplayDst "This signal is only used in China OEM platform";
BA_ "Platform" SG_ 358 CF_Gway_PasDisplayDst "";
BA_ "GenSigSendType" SG_ 358 CF_Gway_PasDisplayDst 3;
BA_ "Gatewaysignal" SG_ 358 CF_Gway_PasDisplayDst 2;
BA_ "TimeoutValue" SG_ 358 CF_Gway_PasDisplayDst "0xF";
BA_ "DiagRequest" BO_ 1920 1;
BA_ "GenMsgILSupport" BO_ 1920 0;
BA_ "TpMessage" BO_ 1920 1;
BA_ "TpTxIndex" BO_ 1920 13;
BA_REL_ "GenSigTimeoutTime" BU_SG_REL_ H_U SG_ 1920 Byte0_TCP_780 0;
BA_ "Platform" SG_ 1920 Byte0_TCP_780 "";
BA_ "DiagRequest" BO_ 1920 1;
BA_ "GenMsgILSupport" BO_ 1920 0;
BA_ "TpMessage" BO_ 1920 1;
BA_ "TpTxIndex" BO_ 1920 13;
BA_REL_ "GenSigTimeoutTime" BU_SG_REL_ H_U SG_ 1920 Byte1_Data_780 0;
BA_ "Platform" SG_ 1920 Byte1_Data_780 "";
BA_ "DiagRequest" BO_ 1920 1;
BA_ "GenMsgILSupport" BO_ 1920 0;
BA_ "TpMessage" BO_ 1920 1;
BA_ "TpTxIndex" BO_ 1920 13;
BA_REL_ "GenSigTimeoutTime" BU_SG_REL_ H_U SG_ 1920 Byte2_Data_780 0;
BA_ "Platform" SG_ 1920 Byte2_Data_780 "";
BA_ "DiagRequest" BO_ 1920 1;
BA_ "GenMsgILSupport" BO_ 1920 0;
BA_ "TpMessage" BO_ 1920 1;
BA_ "TpTxIndex" BO_ 1920 13;
BA_REL_ "GenSigTimeoutTime" BU_SG_REL_ H_U SG_ 1920 Byte3_Data_780 0;
BA_ "Platform" SG_ 1920 Byte3_Data_780 "";
BA_ "DiagRequest" BO_ 1920 1;
BA_ "GenMsgILSupport" BO_ 1920 0;
BA_ "TpMessage" BO_ 1920 1;
BA_ "TpTxIndex" BO_ 1920 13;
BA_REL_ "GenSigTimeoutTime" BU_SG_REL_ H_U SG_ 1920 Byte4_Data_780 0;
BA_ "Platform" SG_ 1920 Byte4_Data_780 "";
BA_ "DiagRequest" BO_ 1920 1;
BA_ "GenMsgILSupport" BO_ 1920 0;
BA_ "TpMessage" BO_ 1920 1;
BA_ "TpTxIndex" BO_ 1920 13;
BA_REL_ "GenSigTimeoutTime" BU_SG_REL_ H_U SG_ 1920 Byte5_Data_780 0;
BA_ "Platform" SG_ 1920 Byte5_Data_780 "";
BA_ "DiagRequest" BO_ 1920 1;
BA_ "GenMsgILSupport" BO_ 1920 0;
BA_ "TpMessage" BO_ 1920 1;
BA_ "TpTxIndex" BO_ 1920 13;
BA_REL_ "GenSigTimeoutTime" BU_SG_REL_ H_U SG_ 1920 Byte6_Data_780 0;
BA_ "Platform" SG_ 1920 Byte6_Data_780 "";
BA_ "DiagRequest" BO_ 1920 1;
BA_ "GenMsgILSupport" BO_ 1920 0;
BA_ "TpMessage" BO_ 1920 1;
BA_ "TpTxIndex" BO_ 1920 13;
BA_REL_ "GenSigTimeoutTime" BU_SG_REL_ H_U SG_ 1920 Byte7_Data_780 0;
BA_ "Platform" SG_ 1920 Byte7_Data_780 "";
BA_ "GenMsgSendType" BO_ 479 0;
BA_ "GenMsgCycleTime" BO_ 479 200;
BA_ "GenMsgStartDelayTime" BO_ 479 140;
BA_ "SigDescription" SG_ 479 Clu_RheostatLvl "[Default Value]
Invalid (= Old value)";
BA_ "Platform" SG_ 479 Clu_RheostatLvl "";
BA_ "GenSigSendType" SG_ 479 Clu_RheostatLvl 3;
BA_ "GenSigStartValue" SG_ 479 Clu_RheostatLvl 31;
BA_ "TimeoutValue" SG_ 479 Clu_RheostatLvl "Old Value";
BA_ "GenMsgILSupport" BO_ 1265 0;
BA_ "TpMessage" BO_ 1265 1;
BA_ "TpTxIndex" BO_ 1265 38;
BA_REL_ "GenSigTimeoutTime" BU_SG_REL_ H_U SG_ 1265 Byte0_TCP_4F1 0;
BA_ "Platform" SG_ 1265 Byte0_TCP_4F1 "";
BA_ "GenMsgILSupport" BO_ 1265 0;
BA_ "TpMessage" BO_ 1265 1;
BA_ "TpTxIndex" BO_ 1265 38;
BA_REL_ "GenSigTimeoutTime" BU_SG_REL_ H_U SG_ 1265 Byte1_Data_4F1 0;
BA_ "Platform" SG_ 1265 Byte1_Data_4F1 "";
BA_ "GenMsgILSupport" BO_ 1265 0;
BA_ "TpMessage" BO_ 1265 1;
BA_ "TpTxIndex" BO_ 1265 38;
BA_REL_ "GenSigTimeoutTime" BU_SG_REL_ H_U SG_ 1265 Byte2_Data_4F1 0;
BA_ "Platform" SG_ 1265 Byte2_Data_4F1 "";
BA_ "GenMsgILSupport" BO_ 1265 0;
BA_ "TpMessage" BO_ 1265 1;
BA_ "TpTxIndex" BO_ 1265 38;
BA_REL_ "GenSigTimeoutTime" BU_SG_REL_ H_U SG_ 1265 Byte3_Data_4F1 0;
BA_ "Platform" SG_ 1265 Byte3_Data_4F1 "";
BA_ "GenMsgILSupport" BO_ 1265 0;
BA_ "TpMessage" BO_ 1265 1;
BA_ "TpTxIndex" BO_ 1265 38;
BA_REL_ "GenSigTimeoutTime" BU_SG_REL_ H_U SG_ 1265 Byte4_Data_4F1 0;
BA_ "Platform" SG_ 1265 Byte4_Data_4F1 "";
BA_ "GenMsgILSupport" BO_ 1265 0;
BA_ "TpMessage" BO_ 1265 1;
BA_ "TpTxIndex" BO_ 1265 38;
BA_REL_ "GenSigTimeoutTime" BU_SG_REL_ H_U SG_ 1265 Byte5_Data_4F1 0;
BA_ "Platform" SG_ 1265 Byte5_Data_4F1 "";
BA_ "GenMsgILSupport" BO_ 1265 0;
BA_ "TpMessage" BO_ 1265 1;
BA_ "TpTxIndex" BO_ 1265 38;
BA_REL_ "GenSigTimeoutTime" BU_SG_REL_ H_U SG_ 1265 Byte6_Data_4F1 0;
BA_ "Platform" SG_ 1265 Byte6_Data_4F1 "";
BA_ "GenMsgILSupport" BO_ 1265 0;
BA_ "TpMessage" BO_ 1265 1;
BA_ "TpTxIndex" BO_ 1265 38;
BA_REL_ "GenSigTimeoutTime" BU_SG_REL_ H_U SG_ 1265 Byte7_Data_4F1 0;
BA_ "Platform" SG_ 1265 Byte7_Data_4F1 "";
BA_ "GenMsgILSupport" BO_ 1273 0;
BA_ "TpMessage" BO_ 1273 1;
BA_ "TpTxIndex" BO_ 1273 47;
BA_REL_ "GenSigTimeoutTime" BU_SG_REL_ H_U SG_ 1273 Byte0_TCP_4F9 0;
BA_ "Platform" SG_ 1273 Byte0_TCP_4F9 "";
BA_ "GenMsgILSupport" BO_ 1273 0;
BA_ "TpMessage" BO_ 1273 1;
BA_ "TpTxIndex" BO_ 1273 47;
BA_REL_ "GenSigTimeoutTime" BU_SG_REL_ H_U SG_ 1273 Byte1_Data_4F9 0;
BA_ "Platform" SG_ 1273 Byte1_Data_4F9 "";
BA_ "GenMsgILSupport" BO_ 1273 0;
BA_ "TpMessage" BO_ 1273 1;
BA_ "TpTxIndex" BO_ 1273 47;
BA_REL_ "GenSigTimeoutTime" BU_SG_REL_ H_U SG_ 1273 Byte2_Data_4F9 0;
BA_ "Platform" SG_ 1273 Byte2_Data_4F9 "";
BA_ "GenMsgILSupport" BO_ 1273 0;
BA_ "TpMessage" BO_ 1273 1;
BA_ "TpTxIndex" BO_ 1273 47;
BA_REL_ "GenSigTimeoutTime" BU_SG_REL_ H_U SG_ 1273 Byte3_Data_4F9 0;
BA_ "Platform" SG_ 1273 Byte3_Data_4F9 "";
BA_ "GenMsgILSupport" BO_ 1273 0;
BA_ "TpMessage" BO_ 1273 1;
BA_ "TpTxIndex" BO_ 1273 47;
BA_REL_ "GenSigTimeoutTime" BU_SG_REL_ H_U SG_ 1273 Byte4_Data_4F9 0;
BA_ "Platform" SG_ 1273 Byte4_Data_4F9 "";
BA_ "GenMsgILSupport" BO_ 1273 0;
BA_ "TpMessage" BO_ 1273 1;
BA_ "TpTxIndex" BO_ 1273 47;
BA_REL_ "GenSigTimeoutTime" BU_SG_REL_ H_U SG_ 1273 Byte5_Data_4F9 0;
BA_ "Platform" SG_ 1273 Byte5_Data_4F9 "";
BA_ "GenMsgILSupport" BO_ 1273 0;
BA_ "TpMessage" BO_ 1273 1;
BA_ "TpTxIndex" BO_ 1273 47;
BA_REL_ "GenSigTimeoutTime" BU_SG_REL_ H_U SG_ 1273 Byte6_Data_4F9 0;
BA_ "Platform" SG_ 1273 Byte6_Data_4F9 "";
BA_ "GenMsgILSupport" BO_ 1273 0;
BA_ "TpMessage" BO_ 1273 1;
BA_ "TpTxIndex" BO_ 1273 47;
BA_REL_ "GenSigTimeoutTime" BU_SG_REL_ H_U SG_ 1273 Byte7_Data_4F9 0;
BA_ "Platform" SG_ 1273 Byte7_Data_4F9 "";
BA_ "GenMsgILSupport" BO_ 1156 0;
BA_ "TpMessage" BO_ 1156 1;
BA_ "TpTxIndex" BO_ 1156 10;
BA_REL_ "GenSigTimeoutTime" BU_SG_REL_ H_U SG_ 1156 Byte0_TCP_484 0;
BA_ "Platform" SG_ 1156 Byte0_TCP_484 "";
BA_ "GenMsgILSupport" BO_ 1156 0;
BA_ "TpMessage" BO_ 1156 1;
BA_ "TpTxIndex" BO_ 1156 10;
BA_REL_ "GenSigTimeoutTime" BU_SG_REL_ H_U SG_ 1156 Byte1_Data_484 0;
BA_ "Platform" SG_ 1156 Byte1_Data_484 "";
BA_ "GenMsgILSupport" BO_ 1156 0;
BA_ "TpMessage" BO_ 1156 1;
BA_ "TpTxIndex" BO_ 1156 10;
BA_REL_ "GenSigTimeoutTime" BU_SG_REL_ H_U SG_ 1156 Byte2_Data_484 0;
BA_ "Platform" SG_ 1156 Byte2_Data_484 "";
BA_ "GenMsgILSupport" BO_ 1156 0;
BA_ "TpMessage" BO_ 1156 1;
BA_ "TpTxIndex" BO_ 1156 10;
BA_REL_ "GenSigTimeoutTime" BU_SG_REL_ H_U SG_ 1156 Byte3_Data_484 0;
BA_ "Platform" SG_ 1156 Byte3_Data_484 "";
BA_ "GenMsgILSupport" BO_ 1156 0;
BA_ "TpMessage" BO_ 1156 1;
BA_ "TpTxIndex" BO_ 1156 10;
BA_REL_ "GenSigTimeoutTime" BU_SG_REL_ H_U SG_ 1156 Byte4_Data_484 0;
BA_ "Platform" SG_ 1156 Byte4_Data_484 "";
BA_ "GenMsgILSupport" BO_ 1156 0;
BA_ "TpMessage" BO_ 1156 1;
BA_ "TpTxIndex" BO_ 1156 10;
BA_REL_ "GenSigTimeoutTime" BU_SG_REL_ H_U SG_ 1156 Byte5_Data_484 0;
BA_ "Platform" SG_ 1156 Byte5_Data_484 "";
BA_ "GenMsgILSupport" BO_ 1156 0;
BA_ "TpMessage" BO_ 1156 1;
BA_ "TpTxIndex" BO_ 1156 10;
BA_REL_ "GenSigTimeoutTime" BU_SG_REL_ H_U SG_ 1156 Byte6_Data_484 0;
BA_ "Platform" SG_ 1156 Byte6_Data_484 "";
BA_ "GenMsgILSupport" BO_ 1156 0;
BA_ "TpMessage" BO_ 1156 1;
BA_ "TpTxIndex" BO_ 1156 10;
BA_REL_ "GenSigTimeoutTime" BU_SG_REL_ H_U SG_ 1156 Byte7_Data_484 0;
BA_ "Platform" SG_ 1156 Byte7_Data_484 "";
BA_ "GenMsgILSupport" BO_ 1164 0;
BA_ "TpMessage" BO_ 1164 1;
BA_ "TpTxIndex" BO_ 1164 9;
BA_REL_ "GenSigTimeoutTime" BU_SG_REL_ H_U SG_ 1164 Byte0_TCP_48C 0;
BA_ "Platform" SG_ 1164 Byte0_TCP_48C "";
BA_ "GenMsgILSupport" BO_ 1164 0;
BA_ "TpMessage" BO_ 1164 1;
BA_ "TpTxIndex" BO_ 1164 9;
BA_REL_ "GenSigTimeoutTime" BU_SG_REL_ H_U SG_ 1164 Byte1_Data_48C 0;
BA_ "Platform" SG_ 1164 Byte1_Data_48C "";
BA_ "GenMsgILSupport" BO_ 1164 0;
BA_ "TpMessage" BO_ 1164 1;
BA_ "TpTxIndex" BO_ 1164 9;
BA_REL_ "GenSigTimeoutTime" BU_SG_REL_ H_U SG_ 1164 Byte2_Data_48C 0;
BA_ "Platform" SG_ 1164 Byte2_Data_48C "";
BA_ "GenMsgILSupport" BO_ 1164 0;
BA_ "TpMessage" BO_ 1164 1;
BA_ "TpTxIndex" BO_ 1164 9;
BA_REL_ "GenSigTimeoutTime" BU_SG_REL_ H_U SG_ 1164 Byte3_Data_48C 0;
BA_ "Platform" SG_ 1164 Byte3_Data_48C "";
BA_ "GenMsgILSupport" BO_ 1164 0;
BA_ "TpMessage" BO_ 1164 1;
BA_ "TpTxIndex" BO_ 1164 9;
BA_REL_ "GenSigTimeoutTime" BU_SG_REL_ H_U SG_ 1164 Byte4_Data_48C 0;
BA_ "Platform" SG_ 1164 Byte4_Data_48C "";
BA_ "GenMsgILSupport" BO_ 1164 0;
BA_ "TpMessage" BO_ 1164 1;
BA_ "TpTxIndex" BO_ 1164 9;
BA_REL_ "GenSigTimeoutTime" BU_SG_REL_ H_U SG_ 1164 Byte5_Data_48C 0;
BA_ "Platform" SG_ 1164 Byte5_Data_48C "";
BA_ "GenMsgILSupport" BO_ 1164 0;
BA_ "TpMessage" BO_ 1164 1;
BA_ "TpTxIndex" BO_ 1164 9;
BA_REL_ "GenSigTimeoutTime" BU_SG_REL_ H_U SG_ 1164 Byte6_Data_48C 0;
BA_ "Platform" SG_ 1164 Byte6_Data_48C "";
BA_ "GenMsgILSupport" BO_ 1164 0;
BA_ "TpMessage" BO_ 1164 1;
BA_ "TpTxIndex" BO_ 1164 9;
BA_REL_ "GenSigTimeoutTime" BU_SG_REL_ H_U SG_ 1164 Byte7_Data_48C 0;
BA_ "Platform" SG_ 1164 Byte7_Data_48C "";
BA_ "GenMsgILSupport" BO_ 1175 0;
BA_ "TpMessage" BO_ 1175 1;
BA_ "TpTxIndex" BO_ 1175 14;
BA_REL_ "GenSigTimeoutTime" BU_SG_REL_ H_U SG_ 1175 Byte0_TCP_497 0;
BA_ "Platform" SG_ 1175 Byte0_TCP_497 "";
BA_ "GenMsgILSupport" BO_ 1175 0;
BA_ "TpMessage" BO_ 1175 1;
BA_ "TpTxIndex" BO_ 1175 14;
BA_REL_ "GenSigTimeoutTime" BU_SG_REL_ H_U SG_ 1175 Byte1_Data_497 0;
BA_ "Platform" SG_ 1175 Byte1_Data_497 "";
BA_ "GenMsgILSupport" BO_ 1175 0;
BA_ "TpMessage" BO_ 1175 1;
BA_ "TpTxIndex" BO_ 1175 14;
BA_REL_ "GenSigTimeoutTime" BU_SG_REL_ H_U SG_ 1175 Byte2_Data_497 0;
BA_ "Platform" SG_ 1175 Byte2_Data_497 "";
BA_ "GenMsgILSupport" BO_ 1175 0;
BA_ "TpMessage" BO_ 1175 1;
BA_ "TpTxIndex" BO_ 1175 14;
BA_REL_ "GenSigTimeoutTime" BU_SG_REL_ H_U SG_ 1175 Byte3_Data_497 0;
BA_ "Platform" SG_ 1175 Byte3_Data_497 "";
BA_ "GenMsgILSupport" BO_ 1175 0;
BA_ "TpMessage" BO_ 1175 1;
BA_ "TpTxIndex" BO_ 1175 14;
BA_REL_ "GenSigTimeoutTime" BU_SG_REL_ H_U SG_ 1175 Byte4_Data_497 0;
BA_ "Platform" SG_ 1175 Byte4_Data_497 "";
BA_ "GenMsgILSupport" BO_ 1175 0;
BA_ "TpMessage" BO_ 1175 1;
BA_ "TpTxIndex" BO_ 1175 14;
BA_REL_ "GenSigTimeoutTime" BU_SG_REL_ H_U SG_ 1175 Byte5_Data_497 0;
BA_ "Platform" SG_ 1175 Byte5_Data_497 "";
BA_ "GenMsgILSupport" BO_ 1175 0;
BA_ "TpMessage" BO_ 1175 1;
BA_ "TpTxIndex" BO_ 1175 14;
BA_REL_ "GenSigTimeoutTime" BU_SG_REL_ H_U SG_ 1175 Byte6_Data_497 0;
BA_ "Platform" SG_ 1175 Byte6_Data_497 "";
BA_ "GenMsgILSupport" BO_ 1175 0;
BA_ "TpMessage" BO_ 1175 1;
BA_ "TpTxIndex" BO_ 1175 14;
BA_REL_ "GenSigTimeoutTime" BU_SG_REL_ H_U SG_ 1175 Byte7_Data_497 0;
BA_ "Platform" SG_ 1175 Byte7_Data_497 "";
BA_REL_ "GenSigTimeoutTime" BU_SG_REL_ CGW SG_ 116 C_BLE_Encrypted_Result1 0;
BA_ "Platform" SG_ 116 C_BLE_Encrypted_Result1 "";
BA_ "GenSigSendType" SG_ 116 C_BLE_Encrypted_Result1 3;
BA_ "Gatewaysignal" SG_ 116 C_BLE_Encrypted_Result1 1;
BA_ "Validity" SG_ 116 C_BLE_Encrypted_Result1 0;
BA_REL_ "GenSigTimeoutTime" BU_SG_REL_ CGW SG_ 117 C_BLE_Encrypted_Result2 0;
BA_ "Platform" SG_ 117 C_BLE_Encrypted_Result2 "";
BA_ "GenSigSendType" SG_ 117 C_BLE_Encrypted_Result2 3;
BA_ "Gatewaysignal" SG_ 117 C_BLE_Encrypted_Result2 1;
BA_ "Validity" SG_ 117 C_BLE_Encrypted_Result2 0;
BA_REL_ "GenSigTimeoutTime" BU_SG_REL_ CGW SG_ 118 C_BLE_Encrypted_Result3 0;
BA_ "Platform" SG_ 118 C_BLE_Encrypted_Result3 "";
BA_ "GenSigSendType" SG_ 118 C_BLE_Encrypted_Result3 3;
BA_ "Gatewaysignal" SG_ 118 C_BLE_Encrypted_Result3 1;
BA_ "Validity" SG_ 118 C_BLE_Encrypted_Result3 0;
BA_REL_ "GenSigTimeoutTime" BU_SG_REL_ CGW SG_ 119 C_BLE_Encrypted_Result4 0;
BA_ "Platform" SG_ 119 C_BLE_Encrypted_Result4 "";
BA_ "GenSigSendType" SG_ 119 C_BLE_Encrypted_Result4 3;
BA_ "Gatewaysignal" SG_ 119 C_BLE_Encrypted_Result4 1;
BA_ "Validity" SG_ 119 C_BLE_Encrypted_Result4 0;
BA_REL_ "GenSigTimeoutTime" BU_SG_REL_ CGW SG_ 120 C_CmdFobSearch 0;
BA_ "Platform" SG_ 120 C_CmdFobSearch "";
BA_ "GenSigSendType" SG_ 120 C_CmdFobSearch 3;
BA_ "Gatewaysignal" SG_ 120 C_CmdFobSearch 1;
BA_ "Validity" SG_ 120 C_CmdFobSearch 0;
BA_REL_ "GenSigTimeoutTime" BU_SG_REL_ CGW SG_ 120 C_BLE_ISKLearning 0;
BA_ "Platform" SG_ 120 C_BLE_ISKLearning "";
BA_ "GenSigSendType" SG_ 120 C_BLE_ISKLearning 3;
BA_ "Gatewaysignal" SG_ 120 C_BLE_ISKLearning 1;
BA_ "Validity" SG_ 120 C_BLE_ISKLearning 0;
BA_REL_ "GenSigTimeoutTime" BU_SG_REL_ CGW SG_ 120 C_BLE_ISKLearnFB 0;
BA_ "Platform" SG_ 120 C_BLE_ISKLearnFB "";
BA_ "GenSigSendType" SG_ 120 C_BLE_ISKLearnFB 3;
BA_ "Gatewaysignal" SG_ 120 C_BLE_ISKLearnFB 1;
BA_ "Validity" SG_ 120 C_BLE_ISKLearnFB 0;
BA_REL_ "GenSigTimeoutTime" BU_SG_REL_ CGW SG_ 120 C_BLE_Random 0;
BA_ "Platform" SG_ 120 C_BLE_Random "";
BA_ "GenSigSendType" SG_ 120 C_BLE_Random 3;
BA_ "Gatewaysignal" SG_ 120 C_BLE_Random 1;
BA_ "Validity" SG_ 120 C_BLE_Random 0;
BA_ "GenMsgCycleTimeFast" BO_ 121 40;
BA_ "GenMsgNrOfRepetition" BO_ 121 3;
BA_REL_ "GenSigTimeoutTime" BU_SG_REL_ CGW SG_ 121 C_BLE_Auth_Device 0;
BA_ "Platform" SG_ 121 C_BLE_Auth_Device "";
BA_ "GenSigSendType" SG_ 121 C_BLE_Auth_Device 4;
BA_ "Gatewaysignal" SG_ 121 C_BLE_Auth_Device 1;
BA_ "NmNetworkRequest" SG_ 121 C_BLE_Auth_Device 1;
BA_ "Validity" SG_ 121 C_BLE_Auth_Device 0;
BA_REL_ "GenSigTimeoutTime" BU_SG_REL_ CGW SG_ 121 C_BLE_Auth_Result 0;
BA_ "Platform" SG_ 121 C_BLE_Auth_Result "";
BA_ "GenSigSendType" SG_ 121 C_BLE_Auth_Result 3;
BA_ "Gatewaysignal" SG_ 121 C_BLE_Auth_Result 1;
BA_ "Validity" SG_ 121 C_BLE_Auth_Result 0;
BA_REL_ "GenSigTimeoutTime" BU_SG_REL_ CGW SG_ 121 C_CtrlDrLockRlyBLE 0;
BA_ "Platform" SG_ 121 C_CtrlDrLockRlyBLE "";
BA_ "GenSigSendType" SG_ 121 C_CtrlDrLockRlyBLE 4;
BA_ "NmNetworkRequest" SG_ 121 C_CtrlDrLockRlyBLE 1;
BA_ "Validity" SG_ 121 C_CtrlDrLockRlyBLE 0;
BA_REL_ "GenSigTimeoutTime" BU_SG_REL_ CGW SG_ 121 C_CtrlDrUnlockRlyBLE 0;
BA_ "Platform" SG_ 121 C_CtrlDrUnlockRlyBLE "";
BA_ "GenSigSendType" SG_ 121 C_CtrlDrUnlockRlyBLE 4;
BA_ "Gatewaysignal" SG_ 121 C_CtrlDrUnlockRlyBLE 1;
BA_ "NmNetworkRequest" SG_ 121 C_CtrlDrUnlockRlyBLE 1;
BA_ "Validity" SG_ 121 C_CtrlDrUnlockRlyBLE 0;
BA_REL_ "GenSigTimeoutTime" BU_SG_REL_ CGW SG_ 121 C_PanicFromBLE 0;
BA_ "Platform" SG_ 121 C_PanicFromBLE "";
BA_ "GenSigSendType" SG_ 121 C_PanicFromBLE 4;
BA_ "Gatewaysignal" SG_ 121 C_PanicFromBLE 1;
BA_ "NmNetworkRequest" SG_ 121 C_PanicFromBLE 1;
BA_ "Validity" SG_ 121 C_PanicFromBLE 0;
BA_REL_ "GenSigTimeoutTime" BU_SG_REL_ CGW SG_ 121 C_HazardFromBLE 0;
BA_ "Platform" SG_ 121 C_HazardFromBLE "";
BA_ "GenSigSendType" SG_ 121 C_HazardFromBLE 4;
BA_ "Gatewaysignal" SG_ 121 C_HazardFromBLE 1;
BA_ "NmNetworkRequest" SG_ 121 C_HazardFromBLE 1;
BA_ "Validity" SG_ 121 C_HazardFromBLE 0;
BA_REL_ "GenSigTimeoutTime" BU_SG_REL_ CGW SG_ 121 C_BLEHeatingCmd 0;
BA_ "Platform" SG_ 121 C_BLEHeatingCmd "";
BA_ "GenSigSendType" SG_ 121 C_BLEHeatingCmd 4;
BA_ "NmNetworkRequest" SG_ 121 C_BLEHeatingCmd 1;
BA_ "Validity" SG_ 121 C_BLEHeatingCmd 0;
BA_REL_ "GenSigTimeoutTime" BU_SG_REL_ CGW SG_ 121 C_BLEWelcomeCmd 0;
BA_ "Platform" SG_ 121 C_BLEWelcomeCmd "";
BA_ "GenSigSendType" SG_ 121 C_BLEWelcomeCmd 4;
BA_ "Gatewaysignal" SG_ 121 C_BLEWelcomeCmd 1;
BA_ "NmNetworkRequest" SG_ 121 C_BLEWelcomeCmd 1;
BA_ "Validity" SG_ 121 C_BLEWelcomeCmd 0;
BA_REL_ "GenSigTimeoutTime" BU_SG_REL_ CGW SG_ 121 C_TrunkTgReleaseRlyBLE 0;
BA_ "Platform" SG_ 121 C_TrunkTgReleaseRlyBLE "";
BA_ "GenSigSendType" SG_ 121 C_TrunkTgReleaseRlyBLE 4;
BA_ "Gatewaysignal" SG_ 121 C_TrunkTgReleaseRlyBLE 1;
BA_ "NmNetworkRequest" SG_ 121 C_TrunkTgReleaseRlyBLE 1;
BA_ "Validity" SG_ 121 C_TrunkTgReleaseRlyBLE 0;
BA_REL_ "GenSigTimeoutTime" BU_SG_REL_ CGW SG_ 121 C_BLE_DefrostCtr 0;
BA_ "Platform" SG_ 121 C_BLE_DefrostCtr "";
BA_ "GenSigSendType" SG_ 121 C_BLE_DefrostCtr 3;
BA_ "Validity" SG_ 121 C_BLE_DefrostCtr 0;
BA_REL_ "GenSigTimeoutTime" BU_SG_REL_ CGW SG_ 121 C_BLE_AirconCtr 0;
BA_ "Platform" SG_ 121 C_BLE_AirconCtr "";
BA_ "GenSigSendType" SG_ 121 C_BLE_AirconCtr 3;
BA_ "Validity" SG_ 121 C_BLE_AirconCtr 0;
BA_REL_ "GenSigTimeoutTime" BU_SG_REL_ CGW SG_ 121 C_BLE_TempMd 0;
BA_ "Platform" SG_ 121 C_BLE_TempMd "";
BA_ "GenSigSendType" SG_ 121 C_BLE_TempMd 3;
BA_ "Validity" SG_ 121 C_BLE_TempMd 0;
BA_REL_ "GenSigTimeoutTime" BU_SG_REL_ CGW SG_ 121 C_BLE_TempSet 0;
BA_ "Platform" SG_ 121 C_BLE_TempSet "";
BA_ "GenSigSendType" SG_ 121 C_BLE_TempSet 4;
BA_ "NmNetworkRequest" SG_ 121 C_BLE_TempSet 1;
BA_ "Validity" SG_ 121 C_BLE_TempSet 0;
BA_ "GenMsgSendType" BO_ 485 0;
BA_ "GenMsgCycleTime" BO_ 485 200;
BA_ "GenMsgCycleTimeFast" BO_ 485 40;
BA_ "GenMsgNrOfRepetition" BO_ 485 3;
BA_ "GenMsgStartDelayTime" BO_ 485 140;
BA_ "Platform" SG_ 485 Navi_OverSpdAlarm "";
BA_ "GenSigSendType" SG_ 485 Navi_OverSpdAlarm 4;
BA_ "GenSigStartValue" SG_ 485 Navi_OverSpdAlarm 3;
BA_ "Gatewaysignal" SG_ 485 Navi_OverSpdAlarm 1;
BA_ "NmNetworkRequest" SG_ 485 Navi_OverSpdAlarm 1;
BA_ "SignalCategory" SG_ 485 Navi_OverSpdAlarm 13;
BA_ "TimeoutValue" SG_ 485 Navi_OverSpdAlarm "Old value";
BA_ "Platform" SG_ 485 Navi_NonSpdTrap "";
BA_ "GenSigSendType" SG_ 485 Navi_NonSpdTrap 3;
BA_ "GenSigStartValue" SG_ 485 Navi_NonSpdTrap 31;
BA_ "TimeoutValue" SG_ 485 Navi_NonSpdTrap "Old Value";
BA_ "Platform" SG_ 485 Navi_WarningZone2 "";
BA_ "GenSigSendType" SG_ 485 Navi_WarningZone2 3;
BA_ "GenSigStartValue" SG_ 485 Navi_WarningZone2 31;
BA_ "TimeoutValue" SG_ 485 Navi_WarningZone2 "Old Value";
BA_ "Platform" SG_ 485 Navi_WarningZone "";
BA_ "GenSigSendType" SG_ 485 Navi_WarningZone 3;
BA_ "GenSigStartValue" SG_ 485 Navi_WarningZone 15;
BA_ "TimeoutValue" SG_ 485 Navi_WarningZone "Old Value";
BA_ "Platform" SG_ 485 Navi_WarningZone3 "";
BA_ "GenSigSendType" SG_ 485 Navi_WarningZone3 3;
BA_ "GenSigStartValue" SG_ 485 Navi_WarningZone3 15;
BA_ "TimeoutValue" SG_ 485 Navi_WarningZone3 "Old Value";
BA_ "Platform" SG_ 485 Navi_CurveWarning "";
BA_ "GenSigSendType" SG_ 485 Navi_CurveWarning 4;
BA_ "GenSigStartValue" SG_ 485 Navi_CurveWarning 15;
BA_ "NmNetworkRequest" SG_ 485 Navi_CurveWarning 1;
BA_ "SignalCategory" SG_ 485 Navi_CurveWarning 13;
BA_ "TimeoutValue" SG_ 485 Navi_CurveWarning "Old Value";
BA_ "Platform" SG_ 485 Navi_SpdLimit_Type "";
BA_ "GenSigSendType" SG_ 485 Navi_SpdLimit_Type 4;
BA_ "GenSigStartValue" SG_ 485 Navi_SpdLimit_Type 3;
BA_ "NmNetworkRequest" SG_ 485 Navi_SpdLimit_Type 1;
BA_ "TimeoutValue" SG_ 485 Navi_SpdLimit_Type "Old Value";
BA_ "Platform" SG_ 485 Navi_SpdLimit_Unit "";
BA_ "GenSigSendType" SG_ 485 Navi_SpdLimit_Unit 4;
BA_ "GenSigStartValue" SG_ 485 Navi_SpdLimit_Unit 3;
BA_ "NmNetworkRequest" SG_ 485 Navi_SpdLimit_Unit 1;
BA_ "TimeoutValue" SG_ 485 Navi_SpdLimit_Unit "Old Value";
BA_ "SigDescription" SG_ 485 Navi_SpdInfo_Type "권장 : 고급형 2.0, 표준형 4.5(DH)의 수출향과 향후 플랫폼은 Navi_FixedSpdTrap, Navi_MobileSpdTrap, Navi)SpdRedlightTrap 신호 대신 이 신호 사용.";
BA_ "Platform" SG_ 485 Navi_SpdInfo_Type "";
BA_ "GenSigSendType" SG_ 485 Navi_SpdInfo_Type 3;
BA_ "GenSigStartValue" SG_ 485 Navi_SpdInfo_Type 15;
BA_ "TimeoutValue" SG_ 485 Navi_SpdInfo_Type "Old Value";
BA_ "Platform" SG_ 485 Navi_SpdLimit "";
BA_ "GenSigSendType" SG_ 485 Navi_SpdLimit 4;
BA_ "GenSigStartValue" SG_ 485 Navi_SpdLimit 255;
BA_ "NmNetworkRequest" SG_ 485 Navi_SpdLimit 1;
BA_ "TimeoutValue" SG_ 485 Navi_SpdLimit "Old Value";
BA_ "GenMsgSendType" BO_ 487 0;
BA_ "GenMsgCycleTime" BO_ 487 200;
BA_ "GenMsgStartDelayTime" BO_ 487 170;
BA_ "Platform" SG_ 487 NV_EstDist_F "";
BA_ "GenSigSendType" SG_ 487 NV_EstDist_F 3;
BA_ "GenSigStartValue" SG_ 487 NV_EstDist_F 15;
BA_ "Platform" SG_ 487 NV_EstDist_Unit "";
BA_ "GenSigSendType" SG_ 487 NV_EstDist_Unit 3;
BA_ "GenSigStartValue" SG_ 487 NV_EstDist_Unit 15;
BA_ "Platform" SG_ 487 NV_EstHour "";
BA_ "GenSigSendType" SG_ 487 NV_EstHour 3;
BA_ "GenSigStartValue" SG_ 487 NV_EstHour 255;
BA_ "Platform" SG_ 487 NV_EstMin "";
BA_ "GenSigSendType" SG_ 487 NV_EstMin 3;
BA_ "GenSigStartValue" SG_ 487 NV_EstMin 255;
BA_ "Platform" SG_ 487 NV_Azimuth "";
BA_ "GenSigSendType" SG_ 487 NV_Azimuth 3;
BA_ "GenSigStartValue" SG_ 487 NV_Azimuth 255;
BA_ "Platform" SG_ 487 NV_EstDist_I "";
BA_ "GenSigSendType" SG_ 487 NV_EstDist_I 3;
BA_ "GenSigStartValue" SG_ 487 NV_EstDist_I 65535;
BA_ "Platform" SG_ 487 NV_EstimTimeType "";
BA_ "GenSigSendType" SG_ 487 NV_EstimTimeType 3;
BA_ "GenSigStartValue" SG_ 487 NV_EstimTimeType 3;
BA_ "SignalCategory" SG_ 487 NV_EstimTimeType 13;
BA_ "TimeoutValue" SG_ 487 NV_EstimTimeType "Old Value";
BA_ "Platform" SG_ 487 NV_EstimTimeFormat "";
BA_ "GenSigSendType" SG_ 487 NV_EstimTimeFormat 3;
BA_ "GenSigStartValue" SG_ 487 NV_EstimTimeFormat 3;
BA_ "TimeoutValue" SG_ 487 NV_EstimTimeFormat "Old Value";
BA_ "Platform" SG_ 487 NV_EstPointType "";
BA_ "GenSigSendType" SG_ 487 NV_EstPointType 3;
BA_ "GenSigStartValue" SG_ 487 NV_EstPointType 15;
BA_REL_ "GenSigTimeoutTime" BU_SG_REL_ CGW SG_ 56 C_DrvWindowCmdAVN 0;
BA_REL_ "GenSigTimeoutTime" BU_SG_REL_ CLU SG_ 56 C_DrvWindowCmdAVN 0;
BA_ "Platform" SG_ 56 C_DrvWindowCmdAVN "";
BA_ "GenSigSendType" SG_ 56 C_DrvWindowCmdAVN 3;
BA_ "GenSigStartValue" SG_ 56 C_DrvWindowCmdAVN 7;
BA_REL_ "GenSigTimeoutTime" BU_SG_REL_ CGW SG_ 56 C_RrDefoggerCmdAVN 0;
BA_REL_ "GenSigTimeoutTime" BU_SG_REL_ CLU SG_ 56 C_RrDefoggerCmdAVN 0;
BA_ "Platform" SG_ 56 C_RrDefoggerCmdAVN "";
BA_ "GenSigSendType" SG_ 56 C_RrDefoggerCmdAVN 3;
BA_ "GenSigStartValue" SG_ 56 C_RrDefoggerCmdAVN 3;
BA_ "Validity" SG_ 56 C_RrDefoggerCmdAVN 2;
BA_REL_ "GenSigTimeoutTime" BU_SG_REL_ CGW SG_ 56 C_TrunkTlgtCmdAVN 0;
BA_REL_ "GenSigTimeoutTime" BU_SG_REL_ CLU SG_ 56 C_TrunkTlgtCmdAVN 0;
BA_ "Platform" SG_ 56 C_TrunkTlgtCmdAVN "";
BA_ "GenSigSendType" SG_ 56 C_TrunkTlgtCmdAVN 3;
BA_ "GenSigStartValue" SG_ 56 C_TrunkTlgtCmdAVN 3;
BA_ "Validity" SG_ 56 C_TrunkTlgtCmdAVN 2;
BA_REL_ "GenSigTimeoutTime" BU_SG_REL_ CGW SG_ 56 C_GlassCmdAVN 0;
BA_REL_ "GenSigTimeoutTime" BU_SG_REL_ CLU SG_ 56 C_GlassCmdAVN 0;
BA_ "Platform" SG_ 56 C_GlassCmdAVN "";
BA_ "GenSigSendType" SG_ 56 C_GlassCmdAVN 3;
BA_ "GenSigStartValue" SG_ 56 C_GlassCmdAVN 7;
BA_REL_ "GenSigTimeoutTime" BU_SG_REL_ CGW SG_ 56 C_BlindCmdAVN 0;
BA_REL_ "GenSigTimeoutTime" BU_SG_REL_ CLU SG_ 56 C_BlindCmdAVN 0;
BA_ "Platform" SG_ 56 C_BlindCmdAVN "";
BA_ "GenSigSendType" SG_ 56 C_BlindCmdAVN 3;
BA_ "GenSigStartValue" SG_ 56 C_BlindCmdAVN 7;
BA_REL_ "GenSigTimeoutTime" BU_SG_REL_ CLU SG_ 56 C_CluDispCmdAVN 0;
BA_ "Platform" SG_ 56 C_CluDispCmdAVN "";
BA_ "GenSigSendType" SG_ 56 C_CluDispCmdAVN 3;
BA_ "GenSigStartValue" SG_ 56 C_CluDispCmdAVN 7;
BA_ "Validity" SG_ 56 C_CluDispCmdAVN 2;
BA_REL_ "GenSigTimeoutTime" BU_SG_REL_ CGW SG_ 56 HU_FLSeatHeatVRcmd 0;
BA_ "SigDescription" SG_ 56 HU_FLSeatHeatVRcmd "Seat heat&vent VR control signal";
BA_ "Platform" SG_ 56 HU_FLSeatHeatVRcmd "";
BA_ "GenSigSendType" SG_ 56 HU_FLSeatHeatVRcmd 3;
BA_ "Gatewaysignal" SG_ 56 HU_FLSeatHeatVRcmd 1;
BA_ "Validity" SG_ 56 HU_FLSeatHeatVRcmd 2;
BA_REL_ "GenSigTimeoutTime" BU_SG_REL_ CGW SG_ 56 HU_FRSeatHeatVRcmd 0;
BA_ "SigDescription" SG_ 56 HU_FRSeatHeatVRcmd "Seat heat&vent VR control signal";
BA_ "Platform" SG_ 56 HU_FRSeatHeatVRcmd "";
BA_ "GenSigSendType" SG_ 56 HU_FRSeatHeatVRcmd 3;
BA_ "Gatewaysignal" SG_ 56 HU_FRSeatHeatVRcmd 1;
BA_ "Validity" SG_ 56 HU_FRSeatHeatVRcmd 2;
BA_ "GenMsgSendType" BO_ 369 0;
BA_ "GenMsgCycleTime" BO_ 369 200;
BA_ "GenMsgCycleTimeFast" BO_ 369 40;
BA_ "GenMsgNrOfRepetition" BO_ 369 3;
BA_ "GenMsgStartDelayTime" BO_ 369 120;
BA_ "SigDescription" SG_ 369 HU_VehiclePwr "[Default Value]
0x0
[KBD Wake-up Condition]
Door Open/Door Unlock/Welcome On (Pre-booting from Vehicle interrupt)";
BA_ "Platform" SG_ 369 HU_VehiclePwr "";
BA_ "GenSigSendType" SG_ 369 HU_VehiclePwr 4;
BA_ "NmNetworkRequest" SG_ 369 HU_VehiclePwr 1;
BA_ "NmNetworkRequestHoldingTime" SG_ 369 HU_VehiclePwr 5;
BA_ "TimeoutValue" SG_ 369 HU_VehiclePwr "0x0";
BA_ "Validity" SG_ 369 HU_VehiclePwr 0;
BA_ "GenMsgSendType" BO_ 448 0;
BA_ "GenMsgCycleTime" BO_ 448 1000;
BA_ "GenMsgCycleTimeFast" BO_ 448 40;
BA_ "GenMsgNrOfRepetition" BO_ 448 3;
BA_ "GenMsgStartDelayTime" BO_ 448 220;
BA_REL_ "GenSigTimeoutTime" BU_SG_REL_ CGW SG_ 448 HU_VRActivity 3500;
BA_REL_ "GenSigTimeoutTime" BU_SG_REL_ CLU SG_ 448 HU_VRActivity 3500;
BA_ "Platform" SG_ 448 HU_VRActivity "";
BA_ "GenSigSendType" SG_ 448 HU_VRActivity 4;
BA_ "GenSigStartValue" SG_ 448 HU_VRActivity 3;
BA_ "Gatewaysignal" SG_ 448 HU_VRActivity 3;
BA_ "NmNetworkRequest" SG_ 448 HU_VRActivity 1;
BA_ "SignalCategory" SG_ 448 HU_VRActivity 13;
BA_ "TimeoutValue" SG_ 448 HU_VRActivity "Old Value";
BA_REL_ "GenSigTimeoutTime" BU_SG_REL_ CGW SG_ 232 C_SHVU_DTC_Mode 0;
BA_ "SigDescription" SG_ 232 C_SHVU_DTC_Mode "This signal is used for displaying seat diagnosis info on HU engineer mode";
BA_ "Platform" SG_ 232 C_SHVU_DTC_Mode "";
BA_ "GenSigSendType" SG_ 232 C_SHVU_DTC_Mode 3;
BA_ "GenSigStartValue" SG_ 232 C_SHVU_DTC_Mode 2;
BA_ "Gatewaysignal" SG_ 232 C_SHVU_DTC_Mode 1;
BA_ "Validity" SG_ 232 C_SHVU_DTC_Mode 2;
BA_ "GenMsgCycleTimeFast" BO_ 61 40;
BA_ "GenMsgNrOfRepetition" BO_ 61 3;
BA_REL_ "GenSigTimeoutTime" BU_SG_REL_ CGW SG_ 61 C_CtrlDrLockRlyIBOX 0;
BA_ "SigDescription" SG_ 61 C_CtrlDrLockRlyIBOX "Remote Control message";
BA_ "Platform" SG_ 61 C_CtrlDrLockRlyIBOX "";
BA_ "GenSigSendType" SG_ 61 C_CtrlDrLockRlyIBOX 4;
BA_ "Gatewaysignal" SG_ 61 C_CtrlDrLockRlyIBOX 1;
BA_ "NmNetworkRequest" SG_ 61 C_CtrlDrLockRlyIBOX 1;
BA_ "NmNetworkRequestHoldingTime" SG_ 61 C_CtrlDrLockRlyIBOX 2;
BA_ "SignalCategory" SG_ 61 C_CtrlDrLockRlyIBOX 10;
BA_ "Validity" SG_ 61 C_CtrlDrLockRlyIBOX 0;
BA_REL_ "GenSigTimeoutTime" BU_SG_REL_ CGW SG_ 61 C_CtrlDrUnlockRlyIBOX 0;
BA_ "SigDescription" SG_ 61 C_CtrlDrUnlockRlyIBOX "Remote Control message";
BA_ "Platform" SG_ 61 C_CtrlDrUnlockRlyIBOX "";
BA_ "GenSigSendType" SG_ 61 C_CtrlDrUnlockRlyIBOX 4;
BA_ "Gatewaysignal" SG_ 61 C_CtrlDrUnlockRlyIBOX 1;
BA_ "NmNetworkRequest" SG_ 61 C_CtrlDrUnlockRlyIBOX 1;
BA_ "NmNetworkRequestHoldingTime" SG_ 61 C_CtrlDrUnlockRlyIBOX 2;
BA_ "SignalCategory" SG_ 61 C_CtrlDrUnlockRlyIBOX 10;
BA_ "Validity" SG_ 61 C_CtrlDrUnlockRlyIBOX 0;
BA_REL_ "GenSigTimeoutTime" BU_SG_REL_ CGW SG_ 61 C_PanicFromIBOX 0;
BA_ "SigDescription" SG_ 61 C_PanicFromIBOX "Remote Control message";
BA_ "Platform" SG_ 61 C_PanicFromIBOX "";
BA_ "GenSigSendType" SG_ 61 C_PanicFromIBOX 4;
BA_ "Gatewaysignal" SG_ 61 C_PanicFromIBOX 1;
BA_ "NmNetworkRequest" SG_ 61 C_PanicFromIBOX 1;
BA_ "NmNetworkRequestHoldingTime" SG_ 61 C_PanicFromIBOX 2;
BA_ "SignalCategory" SG_ 61 C_PanicFromIBOX 10;
BA_ "Validity" SG_ 61 C_PanicFromIBOX 0;
BA_REL_ "GenSigTimeoutTime" BU_SG_REL_ CGW SG_ 61 C_HazardFromIBOX 0;
BA_ "SigDescription" SG_ 61 C_HazardFromIBOX "Remote Control message";
BA_ "Platform" SG_ 61 C_HazardFromIBOX "";
BA_ "GenSigSendType" SG_ 61 C_HazardFromIBOX 4;
BA_ "Gatewaysignal" SG_ 61 C_HazardFromIBOX 1;
BA_ "NmNetworkRequest" SG_ 61 C_HazardFromIBOX 1;
BA_ "NmNetworkRequestHoldingTime" SG_ 61 C_HazardFromIBOX 2;
BA_ "SignalCategory" SG_ 61 C_HazardFromIBOX 10;
BA_ "Validity" SG_ 61 C_HazardFromIBOX 0;
BA_REL_ "GenSigTimeoutTime" BU_SG_REL_ CGW SG_ 61 C_TeleHeatingCmdIBOX 0;
BA_ "Platform" SG_ 61 C_TeleHeatingCmdIBOX "";
BA_ "GenSigSendType" SG_ 61 C_TeleHeatingCmdIBOX 4;
BA_ "GenSigStartValue" SG_ 61 C_TeleHeatingCmdIBOX 3;
BA_ "NmNetworkRequest" SG_ 61 C_TeleHeatingCmdIBOX 1;
BA_ "SignalCategory" SG_ 61 C_TeleHeatingCmdIBOX 10;
BA_ "Validity" SG_ 61 C_TeleHeatingCmdIBOX 0;
BA_REL_ "GenSigTimeoutTime" BU_SG_REL_ CGW SG_ 61 C_PreCrankReq 0;
BA_ "SigDescription" SG_ 61 C_PreCrankReq "Remote Control message";
BA_ "Platform" SG_ 61 C_PreCrankReq "";
BA_ "GenSigSendType" SG_ 61 C_PreCrankReq 4;
BA_ "Gatewaysignal" SG_ 61 C_PreCrankReq 1;
BA_ "NmNetworkRequest" SG_ 61 C_PreCrankReq 1;
BA_ "Validity" SG_ 61 C_PreCrankReq 0;
BA_REL_ "GenSigTimeoutTime" BU_SG_REL_ CGW SG_ 61 C_TeleDrvSeatOpCmdIBOX 0;
BA_ "SigDescription" SG_ 61 C_TeleDrvSeatOpCmdIBOX "Remote Control message";
BA_ "Platform" SG_ 61 C_TeleDrvSeatOpCmdIBOX "";
BA_ "GenSigSendType" SG_ 61 C_TeleDrvSeatOpCmdIBOX 3;
BA_ "Validity" SG_ 61 C_TeleDrvSeatOpCmdIBOX 2;
BA_REL_ "GenSigTimeoutTime" BU_SG_REL_ CGW SG_ 61 C_TeleAstSeatOpCmdIBOX 0;
BA_ "SigDescription" SG_ 61 C_TeleAstSeatOpCmdIBOX "Remote Control message";
BA_ "Platform" SG_ 61 C_TeleAstSeatOpCmdIBOX "";
BA_ "GenSigSendType" SG_ 61 C_TeleAstSeatOpCmdIBOX 3;
BA_ "Validity" SG_ 61 C_TeleAstSeatOpCmdIBOX 2;
BA_ "GenMsgSendType" BO_ 371 0;
BA_ "GenMsgCycleTime" BO_ 371 200;
BA_ "GenMsgCycleTimeFast" BO_ 371 40;
BA_ "GenMsgNrOfRepetition" BO_ 371 3;
BA_ "GenMsgStartDelayTime" BO_ 371 140;
BA_ "Platform" SG_ 371 HU_AliveStatus "";
BA_ "GenSigSendType" SG_ 371 HU_AliveStatus 4;
BA_ "GenSigStartValue" SG_ 371 HU_AliveStatus 3;
BA_ "NmNetworkRequest" SG_ 371 HU_AliveStatus 1;
BA_ "TimeoutValue" SG_ 371 HU_AliveStatus "0x00";
BA_ "Validity" SG_ 371 HU_AliveStatus 0;
BA_ "SigDescription" SG_ 371 HU_DistanceUnit "J.H.J. DR Request";
BA_ "Platform" SG_ 371 HU_DistanceUnit "";
BA_ "GenSigSendType" SG_ 371 HU_DistanceUnit 4;
BA_ "GenSigStartValue" SG_ 371 HU_DistanceUnit 3;
BA_ "NmNetworkRequest" SG_ 371 HU_DistanceUnit 1;
BA_ "TimeoutValue" SG_ 371 HU_DistanceUnit "Old";
BA_ "Platform" SG_ 371 HU_TempUnit "DIS 2,Integrated AVN1.0 High,Integrated AVN1.0 Mid,Premium AVN 2.0";
BA_ "GenSigSendType" SG_ 371 HU_TempUnit 3;
BA_ "GenSigStartValue" SG_ 371 HU_TempUnit 3;
BA_ "TimeoutValue" SG_ 371 HU_TempUnit "Invalid";
BA_ "SigDescription" SG_ 371 CAM_Request "This signal is used for AHD(Analog High Definition) camera function, and this function is only used on China OEM platform";
BA_ "Platform" SG_ 371 CAM_Request "";
BA_ "GenSigSendType" SG_ 371 CAM_Request 3;
BA_ "Gatewaysignal" SG_ 371 CAM_Request 3;
BA_ "TimeoutValue" SG_ 371 CAM_Request "Old Value";
BA_ "Validity" SG_ 371 CAM_Request 2;
BA_ "SigDescription" SG_ 371 CF_AVN_ProfileIDRValue "This signal is only used in User Profile applied H/Unit";
BA_ "Platform" SG_ 371 CF_AVN_ProfileIDRValue "";
BA_ "GenSigSendType" SG_ 371 CF_AVN_ProfileIDRValue 3;
BA_ "GenSigStartValue" SG_ 371 CF_AVN_ProfileIDRValue 15;
BA_ "Gatewaysignal" SG_ 371 CF_AVN_ProfileIDRValue 5;
BA_ "TimeoutValue" SG_ 371 CF_AVN_ProfileIDRValue "0xF";
BA_ "Validity" SG_ 371 CF_AVN_ProfileIDRValue 0;
BA_ "GenMsgSendType" BO_ 372 0;
BA_ "GenMsgCycleTime" BO_ 372 1000;
BA_ "GenMsgStartDelayTime" BO_ 372 10;
BA_ "Purpose" SG_ 372 HU_TeleSoCAlertValueSet 1;
BA_REL_ "GenSigTimeoutTime" BU_SG_REL_ CGW SG_ 372 HU_TeleSoCAlertValueSet 2500;
BA_ "SigDescription" SG_ 372 HU_TeleSoCAlertValueSet "Alert reference value. The resolution is 1%.";
BA_ "Platform" SG_ 372 HU_TeleSoCAlertValueSet "";
BA_ "GenSigSendType" SG_ 372 HU_TeleSoCAlertValueSet 3;
BA_ "GenSigStartValue" SG_ 372 HU_TeleSoCAlertValueSet 255;
BA_ "TimeoutValue" SG_ 372 HU_TeleSoCAlertValueSet "Old Value";
BA_ "Validity" SG_ 372 HU_TeleSoCAlertValueSet 0;
BA_REL_ "GenSigTimeoutTime" BU_SG_REL_ CGW SG_ 372 HU_TeleVehicleStatusReq 2500;
BA_ "SigDescription" SG_ 372 HU_TeleVehicleStatusReq "Request vehicle status information.";
BA_ "Platform" SG_ 372 HU_TeleVehicleStatusReq "";
BA_ "GenSigSendType" SG_ 372 HU_TeleVehicleStatusReq 3;
BA_ "GenSigStartValue" SG_ 372 HU_TeleVehicleStatusReq 3;
BA_ "TimeoutValue" SG_ 372 HU_TeleVehicleStatusReq "Old Value";
BA_ "Validity" SG_ 372 HU_TeleVehicleStatusReq 0;
BA_ "DiagResponse" BO_ 1928 1;
BA_ "GenMsgILSupport" BO_ 1928 0;
BA_ "TpMessage" BO_ 1928 1;
BA_ "TpTxIndex" BO_ 1928 13;
BA_REL_ "GenSigTimeoutTime" BU_SG_REL_ CGW SG_ 1928 Byte0_TCP_788 0;
BA_ "Platform" SG_ 1928 Byte0_TCP_788 "";
BA_ "DiagResponse" BO_ 1928 1;
BA_ "GenMsgILSupport" BO_ 1928 0;
BA_ "TpMessage" BO_ 1928 1;
BA_ "TpTxIndex" BO_ 1928 13;
BA_REL_ "GenSigTimeoutTime" BU_SG_REL_ CGW SG_ 1928 Byte1_Data_788 0;
BA_ "Platform" SG_ 1928 Byte1_Data_788 "";
BA_ "DiagResponse" BO_ 1928 1;
BA_ "GenMsgILSupport" BO_ 1928 0;
BA_ "TpMessage" BO_ 1928 1;
BA_ "TpTxIndex" BO_ 1928 13;
BA_REL_ "GenSigTimeoutTime" BU_SG_REL_ CGW SG_ 1928 Byte2_Data_788 0;
BA_ "Platform" SG_ 1928 Byte2_Data_788 "";
BA_ "DiagResponse" BO_ 1928 1;
BA_ "GenMsgILSupport" BO_ 1928 0;
BA_ "TpMessage" BO_ 1928 1;
BA_ "TpTxIndex" BO_ 1928 13;
BA_REL_ "GenSigTimeoutTime" BU_SG_REL_ CGW SG_ 1928 Byte3_Data_788 0;
BA_ "Platform" SG_ 1928 Byte3_Data_788 "";
BA_ "DiagResponse" BO_ 1928 1;
BA_ "GenMsgILSupport" BO_ 1928 0;
BA_ "TpMessage" BO_ 1928 1;
BA_ "TpTxIndex" BO_ 1928 13;
BA_REL_ "GenSigTimeoutTime" BU_SG_REL_ CGW SG_ 1928 Byte4_Data_788 0;
BA_ "Platform" SG_ 1928 Byte4_Data_788 "";
BA_ "DiagResponse" BO_ 1928 1;
BA_ "GenMsgILSupport" BO_ 1928 0;
BA_ "TpMessage" BO_ 1928 1;
BA_ "TpTxIndex" BO_ 1928 13;
BA_REL_ "GenSigTimeoutTime" BU_SG_REL_ CGW SG_ 1928 Byte5_Data_788 0;
BA_ "Platform" SG_ 1928 Byte5_Data_788 "";
BA_ "DiagResponse" BO_ 1928 1;
BA_ "GenMsgILSupport" BO_ 1928 0;
BA_ "TpMessage" BO_ 1928 1;
BA_ "TpTxIndex" BO_ 1928 13;
BA_REL_ "GenSigTimeoutTime" BU_SG_REL_ CGW SG_ 1928 Byte6_Data_788 0;
BA_ "Platform" SG_ 1928 Byte6_Data_788 "";
BA_ "DiagResponse" BO_ 1928 1;
BA_ "GenMsgILSupport" BO_ 1928 0;
BA_ "TpMessage" BO_ 1928 1;
BA_ "TpTxIndex" BO_ 1928 13;
BA_REL_ "GenSigTimeoutTime" BU_SG_REL_ CGW SG_ 1928 Byte7_Data_788 0;
BA_ "Platform" SG_ 1928 Byte7_Data_788 "";
BA_ "GenMsgILSupport" BO_ 1272 0;
BA_ "TpMessage" BO_ 1272 1;
BA_ "TpTxIndex" BO_ 1272 47;
BA_REL_ "GenSigTimeoutTime" BU_SG_REL_ CLU SG_ 1272 Byte0_TCP_4F8 0;
BA_ "Platform" SG_ 1272 Byte0_TCP_4F8 "";
BA_ "GenMsgILSupport" BO_ 1272 0;
BA_ "TpMessage" BO_ 1272 1;
BA_ "TpTxIndex" BO_ 1272 47;
BA_REL_ "GenSigTimeoutTime" BU_SG_REL_ CLU SG_ 1272 Byte1_Data_4F8 0;
BA_ "Platform" SG_ 1272 Byte1_Data_4F8 "";
BA_ "GenMsgILSupport" BO_ 1272 0;
BA_ "TpMessage" BO_ 1272 1;
BA_ "TpTxIndex" BO_ 1272 47;
BA_REL_ "GenSigTimeoutTime" BU_SG_REL_ CLU SG_ 1272 Byte2_Data_4F8 0;
BA_ "Platform" SG_ 1272 Byte2_Data_4F8 "";
BA_ "GenMsgILSupport" BO_ 1272 0;
BA_ "TpMessage" BO_ 1272 1;
BA_ "TpTxIndex" BO_ 1272 47;
BA_REL_ "GenSigTimeoutTime" BU_SG_REL_ CLU SG_ 1272 Byte3_Data_4F8 0;
BA_ "Platform" SG_ 1272 Byte3_Data_4F8 "";
BA_ "GenMsgILSupport" BO_ 1272 0;
BA_ "TpMessage" BO_ 1272 1;
BA_ "TpTxIndex" BO_ 1272 47;
BA_REL_ "GenSigTimeoutTime" BU_SG_REL_ CLU SG_ 1272 Byte4_Data_4F8 0;
BA_ "Platform" SG_ 1272 Byte4_Data_4F8 "";
BA_ "GenMsgILSupport" BO_ 1272 0;
BA_ "TpMessage" BO_ 1272 1;
BA_ "TpTxIndex" BO_ 1272 47;
BA_REL_ "GenSigTimeoutTime" BU_SG_REL_ CLU SG_ 1272 Byte5_Data_4F8 0;
BA_ "Platform" SG_ 1272 Byte5_Data_4F8 "";
BA_ "GenMsgILSupport" BO_ 1272 0;
BA_ "TpMessage" BO_ 1272 1;
BA_ "TpTxIndex" BO_ 1272 47;
BA_REL_ "GenSigTimeoutTime" BU_SG_REL_ CLU SG_ 1272 Byte6_Data_4F8 0;
BA_ "Platform" SG_ 1272 Byte6_Data_4F8 "";
BA_ "GenMsgILSupport" BO_ 1272 0;
BA_ "TpMessage" BO_ 1272 1;
BA_ "TpTxIndex" BO_ 1272 47;
BA_REL_ "GenSigTimeoutTime" BU_SG_REL_ CLU SG_ 1272 Byte7_Data_4F8 0;
BA_ "Platform" SG_ 1272 Byte7_Data_4F8 "";
BA_ "GenMsgILSupport" BO_ 1157 0;
BA_ "TpMessage" BO_ 1157 1;
BA_ "TpTxIndex" BO_ 1157 10;
BA_REL_ "GenSigTimeoutTime" BU_SG_REL_ CLU SG_ 1157 Byte0_TCP_485 0;
BA_ "Platform" SG_ 1157 Byte0_TCP_485 "";
BA_ "GenMsgILSupport" BO_ 1157 0;
BA_ "TpMessage" BO_ 1157 1;
BA_ "TpTxIndex" BO_ 1157 10;
BA_REL_ "GenSigTimeoutTime" BU_SG_REL_ CLU SG_ 1157 Byte1_Data_485 0;
BA_ "Platform" SG_ 1157 Byte1_Data_485 "";
BA_ "GenMsgILSupport" BO_ 1157 0;
BA_ "TpMessage" BO_ 1157 1;
BA_ "TpTxIndex" BO_ 1157 10;
BA_REL_ "GenSigTimeoutTime" BU_SG_REL_ CLU SG_ 1157 Byte2_Data_485 0;
BA_ "Platform" SG_ 1157 Byte2_Data_485 "";
BA_ "GenMsgILSupport" BO_ 1157 0;
BA_ "TpMessage" BO_ 1157 1;
BA_ "TpTxIndex" BO_ 1157 10;
BA_REL_ "GenSigTimeoutTime" BU_SG_REL_ CLU SG_ 1157 Byte3_Data_485 0;
BA_ "Platform" SG_ 1157 Byte3_Data_485 "";
BA_ "GenMsgILSupport" BO_ 1157 0;
BA_ "TpMessage" BO_ 1157 1;
BA_ "TpTxIndex" BO_ 1157 10;
BA_REL_ "GenSigTimeoutTime" BU_SG_REL_ CLU SG_ 1157 Byte4_Data_485 0;
BA_ "Platform" SG_ 1157 Byte4_Data_485 "";
BA_ "GenMsgILSupport" BO_ 1157 0;
BA_ "TpMessage" BO_ 1157 1;
BA_ "TpTxIndex" BO_ 1157 10;
BA_REL_ "GenSigTimeoutTime" BU_SG_REL_ CLU SG_ 1157 Byte5_Data_485 0;
BA_ "Platform" SG_ 1157 Byte5_Data_485 "";
BA_ "GenMsgILSupport" BO_ 1157 0;
BA_ "TpMessage" BO_ 1157 1;
BA_ "TpTxIndex" BO_ 1157 10;
BA_REL_ "GenSigTimeoutTime" BU_SG_REL_ CLU SG_ 1157 Byte6_Data_485 0;
BA_ "Platform" SG_ 1157 Byte6_Data_485 "";
BA_ "GenMsgILSupport" BO_ 1157 0;
BA_ "TpMessage" BO_ 1157 1;
BA_ "TpTxIndex" BO_ 1157 10;
BA_REL_ "GenSigTimeoutTime" BU_SG_REL_ CLU SG_ 1157 Byte7_Data_485 0;
BA_ "Platform" SG_ 1157 Byte7_Data_485 "";
BA_ "GenMsgILSupport" BO_ 1179 0;
BA_ "TpMessage" BO_ 1179 1;
BA_ "TpTxIndex" BO_ 1179 9;
BA_REL_ "GenSigTimeoutTime" BU_SG_REL_ CLU SG_ 1179 Byte0_TCP_49B 0;
BA_ "Platform" SG_ 1179 Byte0_TCP_49B "";
BA_ "GenMsgILSupport" BO_ 1179 0;
BA_ "TpMessage" BO_ 1179 1;
BA_ "TpTxIndex" BO_ 1179 9;
BA_REL_ "GenSigTimeoutTime" BU_SG_REL_ CLU SG_ 1179 Byte1_Data_49B 0;
BA_ "Platform" SG_ 1179 Byte1_Data_49B "";
BA_ "GenMsgILSupport" BO_ 1179 0;
BA_ "TpMessage" BO_ 1179 1;
BA_ "TpTxIndex" BO_ 1179 9;
BA_REL_ "GenSigTimeoutTime" BU_SG_REL_ CLU SG_ 1179 Byte2_Data_49B 0;
BA_ "Platform" SG_ 1179 Byte2_Data_49B "";
BA_ "GenMsgILSupport" BO_ 1179 0;
BA_ "TpMessage" BO_ 1179 1;
BA_ "TpTxIndex" BO_ 1179 9;
BA_REL_ "GenSigTimeoutTime" BU_SG_REL_ CLU SG_ 1179 Byte3_Data_49B 0;
BA_ "Platform" SG_ 1179 Byte3_Data_49B "";
BA_ "GenMsgILSupport" BO_ 1179 0;
BA_ "TpMessage" BO_ 1179 1;
BA_ "TpTxIndex" BO_ 1179 9;
BA_REL_ "GenSigTimeoutTime" BU_SG_REL_ CLU SG_ 1179 Byte4_Data_49B 0;
BA_ "Platform" SG_ 1179 Byte4_Data_49B "";
BA_ "GenMsgILSupport" BO_ 1179 0;
BA_ "TpMessage" BO_ 1179 1;
BA_ "TpTxIndex" BO_ 1179 9;
BA_REL_ "GenSigTimeoutTime" BU_SG_REL_ CLU SG_ 1179 Byte5_Data_49B 0;
BA_ "Platform" SG_ 1179 Byte5_Data_49B "";
BA_ "GenMsgILSupport" BO_ 1179 0;
BA_ "TpMessage" BO_ 1179 1;
BA_ "TpTxIndex" BO_ 1179 9;
BA_REL_ "GenSigTimeoutTime" BU_SG_REL_ CLU SG_ 1179 Byte6_Data_49B 0;
BA_ "Platform" SG_ 1179 Byte6_Data_49B "";
BA_ "GenMsgILSupport" BO_ 1179 0;
BA_ "TpMessage" BO_ 1179 1;
BA_ "TpTxIndex" BO_ 1179 9;
BA_REL_ "GenSigTimeoutTime" BU_SG_REL_ CLU SG_ 1179 Byte7_Data_49B 0;
BA_ "Platform" SG_ 1179 Byte7_Data_49B "";
BA_ "GenMsgILSupport" BO_ 1168 0;
BA_ "TpMessage" BO_ 1168 1;
BA_ "TpTxIndex" BO_ 1168 14;
BA_REL_ "GenSigTimeoutTime" BU_SG_REL_ CLU SG_ 1168 Byte0_TCP_490 0;
BA_ "Platform" SG_ 1168 Byte0_TCP_490 "";
BA_ "GenMsgILSupport" BO_ 1168 0;
BA_ "TpMessage" BO_ 1168 1;
BA_ "TpTxIndex" BO_ 1168 14;
BA_REL_ "GenSigTimeoutTime" BU_SG_REL_ CLU SG_ 1168 Byte1_Data_490 0;
BA_ "Platform" SG_ 1168 Byte1_Data_490 "";
BA_ "GenMsgILSupport" BO_ 1168 0;
BA_ "TpMessage" BO_ 1168 1;
BA_ "TpTxIndex" BO_ 1168 14;
BA_REL_ "GenSigTimeoutTime" BU_SG_REL_ CLU SG_ 1168 Byte2_Data_490 0;
BA_ "Platform" SG_ 1168 Byte2_Data_490 "";
BA_ "GenMsgILSupport" BO_ 1168 0;
BA_ "TpMessage" BO_ 1168 1;
BA_ "TpTxIndex" BO_ 1168 14;
BA_REL_ "GenSigTimeoutTime" BU_SG_REL_ CLU SG_ 1168 Byte3_Data_490 0;
BA_ "Platform" SG_ 1168 Byte3_Data_490 "";
BA_ "GenMsgILSupport" BO_ 1168 0;
BA_ "TpMessage" BO_ 1168 1;
BA_ "TpTxIndex" BO_ 1168 14;
BA_REL_ "GenSigTimeoutTime" BU_SG_REL_ CLU SG_ 1168 Byte4_Data_490 0;
BA_ "Platform" SG_ 1168 Byte4_Data_490 "";
BA_ "GenMsgILSupport" BO_ 1168 0;
BA_ "TpMessage" BO_ 1168 1;
BA_ "TpTxIndex" BO_ 1168 14;
BA_REL_ "GenSigTimeoutTime" BU_SG_REL_ CLU SG_ 1168 Byte5_Data_490 0;
BA_ "Platform" SG_ 1168 Byte5_Data_490 "";
BA_ "GenMsgILSupport" BO_ 1168 0;
BA_ "TpMessage" BO_ 1168 1;
BA_ "TpTxIndex" BO_ 1168 14;
BA_REL_ "GenSigTimeoutTime" BU_SG_REL_ CLU SG_ 1168 Byte6_Data_490 0;
BA_ "Platform" SG_ 1168 Byte6_Data_490 "";
BA_ "GenMsgILSupport" BO_ 1168 0;
BA_ "TpMessage" BO_ 1168 1;
BA_ "TpTxIndex" BO_ 1168 14;
BA_REL_ "GenSigTimeoutTime" BU_SG_REL_ CLU SG_ 1168 Byte7_Data_490 0;
BA_ "Platform" SG_ 1168 Byte7_Data_490 "";
BA_ "NmMessage" BO_ 1101 1;
BA_ "GenMsgILSupport" BO_ 1101 0;
BA_ "NmMessage" BO_ 1088 1;
BA_ "GenMsgILSupport" BO_ 1088 0;
BA_ "NmMessage" BO_ 1109 1;
BA_ "GenMsgILSupport" BO_ 1109 0;
VAL_ 1329 DATC_AmbientTempC 0 "Off (Blank display)" 1 "Not Used(BlankDisplay )" 2 "0x2~0xCA:phy=(Hex) *0.5-41." 202 "0x2~0xCA:phy=(Hex) *0.5-41." 203 "Not used" 204 "Not used" 205 "Not used" 206 "Not used" 207 "Not used" 208 "Not used" 209 "Not used" 210 "Not used" 211 "Not used" 212 "Not used" 213 "Not used" 214 "Not used" 215 "Not used" 216 "Not used" 217 "Not used" 218 "Not used" 219 "Not used" 220 "Not used" 221 "Not used" 222 "Not used" 223 "Not used" 224 "Not used" 225 "Not used" 226 "Not used" 227 "Not used" 228 "Not used" 229 "Not used" 230 "Not used" 231 "Not used" 232 "Not used" 233 "Not used" 234 "Not used" 235 "Not used" 236 "Not used" 237 "Not used" 238 "Not used" 239 "Not used" 240 "Not used" 241 "Not used" 242 "Not used" 243 "Not used" 244 "Not used" 245 "Not used" 246 "Not used" 247 "Not used" 248 "Not used" 249 "Not used" 250 "Not used" 251 "Not used" 252 "Not used" 253 "Not used" 254 "Sensor Error ( -- Display)" 255 "Invalid" ;
VAL_ 1329 DATC_AmbientTempF 0 "Off (Blank display)" 1 "Not Used(BlankDisplay )" 2 "0x2~0xB6:phy=(Hex)-42" 182 "0x2~0xB6:phy=(Hex)-42" 183 "Not used" 184 "Not used" 185 "Not used" 186 "Not used" 187 "Not used" 188 "Not used" 189 "Not used" 190 "Not used" 191 "Not used" 192 "Not used" 193 "Not used" 194 "Not used" 195 "Not used" 196 "Not used" 197 "Not used" 198 "Not used" 199 "Not used" 200 "Not used" 201 "Not used" 202 "Not used" 203 "Not used" 204 "Not used" 205 "Not used" 206 "Not used" 207 "Not used" 208 "Not used" 209 "Not used" 210 "Not used" 211 "Not used" 212 "Not used" 213 "Not used" 214 "Not used" 215 "Not used" 216 "Not used" 217 "Not used" 218 "Not used" 219 "Not used" 220 "Not used" 221 "Not used" 222 "Not used" 223 "Not used" 224 "Not used" 225 "Not used" 226 "Not used" 227 "Not used" 228 "Not used" 229 "Not used" 230 "Not used" 231 "Not used" 232 "Not used" 233 "Not used" 234 "Not used" 235 "Not used" 236 "Not used" 237 "Not used" 238 "Not used" 239 "Not used" 240 "Not used" 241 "Not used" 242 "Not used" 243 "Not used" 244 "Not used" 245 "Not used" 246 "Not used" 247 "Not used" 248 "Not used" 249 "Not used" 250 "Not used" 251 "Not used" 252 "Not used" 253 "Not used" 254 "Sensor Error ( -- Display)" 255 "Invalid" ;
VAL_ 336 ANC_EngineCHR 0 "Fuel - Gasoline,  ETC - No" 1 "Fuel - LPI(LPG),  ETC - No" 2 "Fuel - Diesel,     ETC - No" 3 "Reserved" 4 "Fuel - Gasoline,  ETC - Applied" 5 "Fuel - LPI(LPG),  ETC - Applied" 6 "Fuel - Diesel,    ETC - Applied" 7 "GDI type engine" 8 "Fuel - FFV ETC - No" 9 "Fuel - FFV ETC - Applied" 12 "Fuel - Gasoline, ETC - Applied" 14 "Disel2" ;
VAL_ 361 C_Inhibit_State 0 "P" 1 "L" 2 "2" 3 "3" 4 "DS Mode" 5 "D" 6 "N" 7 "R" 8 "SportsMode_ManualShift" 9 "NotDisplayAtCluster" 10 "Sub-RomCommunication" 11 "Sub-RomCommunicationError" 12 "PaddleShift(D-position)" 13 "None-EOL Data" 14 "IntermediatePosition" 15 "fault" ;
VAL_ 361 TCU_TYPE 0 "Reserved" 1 "Step AT" 2 "CVT" 3 "DCT" ;
VAL_ 361 ENG_STAT 0 "Engine Stop" 1 "Cranking" 2 "Stalled" 3 "Running" 4 "Reserved" 5 "Reserved" 6 "Reserved" 7 "Fault" ;
VAL_ 361 CF_Ems_IsgStat 0 "ISG is not operating Normal engine operating without ISG" 1 "Idle stop is activated Idle is stopped by ECU during driving" 2 "Automatically started by ECU Engine is automatically started by ECU regardless driver’s volition during idle stop because the condition that ISG function to be prohibited is satisfied, for example SOC is too low." 3 "ISG is prohibited Driver prohibits to activate ISG in order to avoid start lag when he met traffic jam for example." 4 "Fault is existing in ISG There is fault, which is related with ISG. So, idle stop is prohibited and engine started automatically if it is idle stop condition. But for the vehicles that use CF_EMS_ISGStat2, the condition for not-activated battery sensor can be ignored." 5 "Idle stop is inhibited by system automatically for safety and  convenient condition related with battery SOC, brake vacuum pressure etc. ISG function check for EOL." 6 "Auto start is deactivated system automatically to keep safety, Such as door open, hood open and seat belt unlock." 7 "If driver shift gear N to D range without braking to make auto starting. (Economy ISG Only)" ;
VAL_ 361 CF_Ems_IsgStat2 0 "Default" 1 "The condition for not-activated battery sensor. (Except EOL condition.)" 2 "In Auto Start status, when rapidly accelerating before complete gear shift. (Economy ISG Only)" ;
VAL_ 361 BAT_SOC 0 "0x00~0xFE:PHY = 1 * (HEX Value) [%]" 254 "0x00~0xFE:PHY = 1 * (HEX Value) [%]" 255 "Invalid" ;
VAL_ 361 BAT_SNSR_Error 0 "operating correctly" 1 "response error" 2 "reserved" 3 "invalid" ;
VAL_ 361 BAT_SNSR_State 0 "normal state" 1 "implausible state" 2 "reserved" 3 "invalid" ;
VAL_ 361 BAT_SNSR_Invalid 0 "Valid Condition" 1 "Invalid Condition" 2 "Reserved" 3 "Invalid" ;
VAL_ 361 AVH_LAMP 0 "AVH Off (Lamp Status" 1 "AVH failure (Lamp Status" 2 "AVH ACTIVE (Lamp Status" 3 "AVH READY (Lamp Status" 4 "Lamp Status" 5 "Lamp Status" 6 "Lamp Status" 7 "Invalid" ;
VAL_ 361 EPB_STATUS 0 "See details in EPB_FRC_ERR" 1 "Released" 2 "Clamped" 3 "Clamping in progress" 4 "Releasing in progress" 5 "Dynamic braking via EPB" 6 "Releasing in progress by switch" 7 "Clamping in progress by switch" ;
VAL_ 344 CF_Clu_LowfuelWarning 0 "Off" 1 "Warning" 2 "reserved" 3 "Invalid" ;
VAL_ 344 C_InhibitRMT 0 "Off" 1 "On" 2 "reserved" 3 "Invalid" ;
VAL_ 362 C_AV_Tail 0 "Default" 1 "Deactived" 2 "Actived" 3 "Invalid" ;
VAL_ 362 C_IGN2 0 "IGN2 OFF" 1 "IGN2 ON" 3 "Invalid" ;
VAL_ 362 C_WlightOn 0 "Off" 1 "On" 2 "Reserved" 3 "Invalid" ;
VAL_ 350 C_BAlarmState 0 "Off" 1 "DisArm" 2 "" 3 "PreArm" 4 "ArmWait" 5 "ArmHold(Trunk)" 6 "ReArm" 7 "AutoLockTimer1" 8 "AutoLockTimer2" 9 "Alarm" 10 "Default" 11 "AutoLockTimer3(Tailgate)" ;
VAL_ 350 TMU_RmtEngRunSta 0 "Off" 1 "Tele Running" 2 "reserved" 3 "Invalid" ;
VAL_ 350 C_PpositionClutch 0 "Off" 1 "On" 2 "Reserved" 3 "Invalid" ;
VAL_ 350 C_HoodSw 0 "Off" 1 "On" 2 "Reserved" 3 "Invalid" ;
VAL_ 350 C_DefoggerRly 0 "Off" 1 "On" 2 "Reserved" 3 "Invalid" ;
VAL_ 350 C_WPCWarning 0 "Off" 1 "Cellphone on the pad" 2 "Charging" 3 "Charging complete" 4 "Cellphone reminder" 5 "Charging error" 6 "Reserved" 7 "Invalid" ;
VAL_ 383 Warn_DrvDrSwSta 0 "Close" 1 "Open" 2 "reserved" 3 "Invalid" ;
VAL_ 383 Warn_AsstDrSwSta 0 "Close" 1 "Open" 2 "reserved" 3 "Invalid" ;
VAL_ 383 Warn_RrLftDrSwSta 0 "Close" 1 "Open" 2 "reserved" 3 "Invalid" ;
VAL_ 383 Warn_RrRtDrSwSta 0 "Close" 1 "Open" 2 "reserved" 3 "Invalid" ;
VAL_ 383 DoorLock_DrvDrUnLkSta 0 "Lock" 1 "Unlock" 2 "reserved" 3 "Invalid" ;
VAL_ 383 DoorLock_AsstDrUnLkSta 0 "Lock" 1 "Unlock" 2 "reserved" 3 "Invalid" ;
VAL_ 383 DoorLock_RrLftDrUnLkSta 0 "Lock" 1 "Unlock" 2 "reserved" 3 "Invalid" ;
VAL_ 383 DoorLock_RrRtDrUnLkSta 0 "Lock" 1 "Unlock" 2 "reserved" 3 "Invalid" ;
VAL_ 383 Trunk_TrnkTlgtSwSta 0 "Close(Full Lock)" 1 "Open(Not Full Lock)" 2 "reserved" 3 "Invalid" ;
VAL_ 383 Warn_SunRoofOpnSta 0 "Close" 1 "Open" 2 "reserved" 3 "Invalid" ;
VAL_ 383 BAlarm_PncAlrmReq 0 "Off" 1 "On (Panic Alarm ON)" 2 "reserved" 3 "Invalid" ;
VAL_ 383 Lamp_AutoLtSnsrNightSta 0 "Off" 1 "Night" 2 "reserved" 3 "Invalid" ;
VAL_ 383 ExtLamp_ExtrnlTailLmpSta 0 "Off" 1 "On" 2 "reserved" 3 "Invalid" ;
VAL_ 383 ExtLamp_FrFgLmpSta 0 "Off" 1 "On" 2 "reserved" 3 "Invalid" ;
VAL_ 383 ExtLamp_HdLmpHiSta 0 "Off" 1 "On" 2 "reserved" 3 "Invalid" ;
VAL_ 383 ExtLamp_HdLmpLoSta 0 "Off" 1 "On" 2 "reserved" 3 "Invalid" ;
VAL_ 383 C_DrvWindowOpenState 0 "window close" 1 "window Open" 2 "reserved" 3 "invalid" ;
VAL_ 383 C_FOBBatteryStatusInfo 0 "Normal or No Information" 1 "Recent used FOB is in discharge warning voltage level" 2 "Reserved" 3 "Invalid" ;
VAL_ 383 C_BrakeFluidSw 0 "Off" 1 "On" 2 "Reserved" 3 "Invalid" ;
VAL_ 383 C_BCMFobID 0 "None" 1 "ID1" 2 "ID2" 3 "ID3" 4 "ID4" 5 "Reserved" 6 "Reserved" 7 "Invalid" ;
VAL_ 383 C_SMKFobID 0 "None" 1 "ID1" 2 "ID2" 3 "ID3" 4 "ID4" 5 "Reserved" 6 "Reserved" 7 "Invalid" ;
VAL_ 416 C_DrvWdwErrAntiPinch 0 "Calibrated" 1 "De-Calibrated" 2 "Reserved" 3 "Invalid" ;
VAL_ 416 C_DrvWdwDetailOpenState 0 "Close" 1 "Partial Open" 2 "Full Open" 3 "Invalid" ;
VAL_ 416 C_DrvWindowActState 0 "No Action" 1 "Manual Down" 2 "Manual Up" 3 "RLY Stuck/FET Error" 4 "Motor Stop Error" 5 "Auto Down" 6 "Auto Up" 7 "Reverse" 8 "Reserved" 9 "Reserved" 10 "Reserved" 11 "Reserved" 12 "Reserved" 13 "Reserved" 14 "Reserved" 15 "Invalid" ;
VAL_ 416 C_SafetyWDWOpt 0 "NONE" 1 "All Safety Window Applied" 2 "Reserved" 3 "Invalid" ;
VAL_ 419 C_GlassPositionState 0 "Glass Tilt up" 1 "Glass Vent area" 2 "Glass Anti pinch in vent" 3 "Glass Fully close" 4 "Glass Anti pinch in partially slide" 5 "Glass Partially slide" 6 "Glass Fully open" 7 "Glass Position Loss" 8 "Reserved" 9 "Reserved" 10 "Reserved" 11 "Reserved" 12 "Reserved" 13 "Reserved" 14 "Reserved" 15 "invalid" ;
VAL_ 419 C_BlindPositionState 0 "R/Blind Fully close" 1 "R/Blind Partially open" 2 "R/Blind Anti pinch in partially slide" 3 "R/Blind Fully open" 4 "R/Blind Position Loss" 5 "Reserved" 6 "Reserved" 7 "invalid" ;
VAL_ 419 C_GlassErrorState 0 "Glass No error" 1 "Glass Thermal Protection Active" 2 "Glass Initialized Status" 3 "Glass Undefined ECU Error" 4 "Glass Switch Error" 5 "Glass Voltage error" 6 "Complex Error" 7 "invalid" ;
VAL_ 419 C_BlindErrorState 0 "R/Blind No error" 1 "R/Blind Thermal Protection Active" 2 "R/Blind Initialized Status" 3 "R/Blind Undefined ECU Error" 4 "R/Blind Switch Error" 5 "R/Blind Voltage error" 6 "Complex Error" 7 "invalid" ;
VAL_ 419 C_SunroofOpt 0 "NONE" 1 "Sunroof applied" 2 "reserved" 3 "Invalid" ;
VAL_ 419 C_SHVU_DiagMode 0 "Default" 1 "DTC Mode" 2 "Normal Mode" 3 "Invalid" ;
VAL_ 419 C_FL_SeatHeatDTC 0 "DTC is not exist (Fail is not exist)" 1 "IGN2 Fuse Open Detection" 2 "Switch Input Detection at Same Time" 3 "NTC / Heating wire Open Detection" 4 "NTC+/NTC- Terminal Short Detection" 5 "NTC+ / Heater+ Terminal Short Detection" 6 "NTC+ / Heater-, Heater+/Heater-, Heater+/NTC- Terminal Short, NTC+/NTC- Wiring Short Detection" 7 "NTC+/ Heater- Wiring Short Detection" 8 "NTC+/Heater-, Heater+/Heater-,Heater+/NTC- Wiring Short Detection" 9 "Target Temperature Dissatisfied" 10 "Blower+/Blower- Short, Blower+/Blower Speed, Blower-/Blower Speed Wiring Short Detection" 11 "Blower+/Blower RPM, Blower-/Blower RPM, Blower Speed/Blower RPM Short Detection" 12 "Blower+, Blower-, Blower Speed Signal open Detection" 13 "Blower RPM signal Open Detection" 14 "0x0E~0xFD:Unused" 253 "0x0E~0xFD:Unused" 254 "No Display" 255 "Invalid" ;
VAL_ 419 C_FR_SeatHeatDTC 0 "DTC is not exist (Fail is not exist)" 1 "IGN2 Fuse Open Detection" 2 "Switch Input Detection at Same Time" 3 "NTC / Heating wire Open Detection" 4 "NTC+/NTC- Terminal Short Detection" 5 "NTC+ / Heater+ Terminal Short Detection" 6 "NTC+ / Heater-, Heater+/Heater-, Heater+/NTC- Termianl Short, NTC+/NTC- Wiring Short Detection" 7 "NTC+/ Heater- Wiring Short Detection" 8 "NTC+/Heater-, Heater+/Heater-,Heater+/NTC- Wiring Short Detection" 9 "Target Temperature Dissatisfied" 10 "Blower+/Blower- Short, Blower+/Blower Speed, Blower-/Blower Speed Wiring Short Detection" 11 "Blower+/Blower RPM, Blower-/Blower RPM, Blower Speed/Blower RPM Short Detection" 12 "Blower+, Blower-, Blower Speed Signal open Detection" 13 "Blower RPM signal Open Detection" 14 "0x0E~0xFD:Unused" 253 "0x0E~0xFD:Unused" 254 "No Display" 255 "Invalid" ;
VAL_ 358 C_PASOption 0 "Default" 1 "RPAS(Rear)" 2 "PAS(Front&Rear)" 3 "Invalid" ;
VAL_ 358 CF_Gway_PasDisplayRCTR 0 "Off" 1 "1st Warning" 2 "2nd Warning" 3 "3rd Warning" 4 "Error" 5 "Reserved" 6 "Reserved" 7 "Invalid" ;
VAL_ 358 CF_Gway_PasDisplayRLH 0 "Off" 1 "1st Warning" 2 "2nd Warning" 3 "3rd Warning" 4 "Error" 5 "Reserved" 6 "Reserved" 7 "Invalid" ;
VAL_ 358 CF_Gway_PasDisplayRRH 0 "Off" 1 "1st Warning" 2 "2nd Warning" 3 "3rd Warning" 4 "Error" 5 "Reserved" 6 "Reserved" 7 "Invalid" ;
VAL_ 358 CF_Gway_PasDisplayDst 0 "Off" 1 "Under 0.3m" 2 "0.3m" 3 "0.4m" 4 "0.5m" 5 "0.6m" 6 "0.7m" 7 "0.8m" 8 "0.9m" 9 "1m" 10 "Reserved" 11 "Reserved" 12 "Reserved" 13 "Reserved" 14 "Reserved" 15 "Invalid" ;
VAL_ 479 Clu_RheostatLvl 0 "reserved" 1 "Step 1" 2 "Step 2" 3 "Step 3" 4 "Step 4" 5 "Step 5" 6 "Step 6" 7 "Step 7" 8 "Step 8" 9 "Step 9" 10 "Step 10" 11 "Step 11" 12 "Step 12" 13 "Step 13" 14 "Step 14" 15 "Step 15" 16 "Step 16" 17 "Step 17" 18 "Step 18" 19 "Step 19" 20 "Step 20(Reset Value)" 21 "Step 21 (Detent)" 31 "Invalid" ;
VAL_ 120 C_CmdFobSearch 0 "None" 1 "Search a fob inside" 2 "Reserved" 3 "Reserved" 4 "Reserved" 5 "Reserved" 6 "Reserved" 7 "Invalid" ;
VAL_ 120 C_BLE_ISKLearning 0 "Default(Normal)" 1 "Start" 2 "Stop" 3 "Invalid" ;
VAL_ 120 C_BLE_ISKLearnFB 0 "Default" 1 "Positive" 2 "Negative" 3 "Invalid" ;
VAL_ 121 C_BLE_Auth_Device 0 "None" 1 "Region0" 2 "Region1" 3 "Region2" 4 "Reserved" 5 "Reserved" 6 "Reserved" 7 "Invalid" ;
VAL_ 121 C_BLE_Auth_Result 0 "Default" 1 "Success" 2 "Failure" 3 "Reserved" 4 "Reserved" 5 "Reserved" 6 "Reserved" 7 "Invalid" ;
VAL_ 121 C_CtrlDrLockRlyBLE 0 "Off (default)" 1 "On(Remote Lock command)" 2 "Reserved" 3 "Invalid" ;
VAL_ 121 C_CtrlDrUnlockRlyBLE 0 "Off (default)" 1 "On(Remote Unlock command)" 2 "Reserved" 3 "Invalid" ;
VAL_ 121 C_PanicFromBLE 0 "Off (default)" 1 "On(Remote Horn & Hazard On)" 2 "Reserved" 3 "Invalid" ;
VAL_ 121 C_HazardFromBLE 0 "Off (default)" 1 "On(Remote Hazard On)" 2 "Reserved" 3 "Invalid" ;
VAL_ 121 C_BLEHeatingCmd 0 "Off (default)" 1 "On(Remote Heating On)" 2 "Reserved" 3 "Invalid" ;
VAL_ 121 C_BLEWelcomeCmd 0 "Off (default)" 1 "On(Welcome On)" 2 "Reserved" 3 "Invalid" ;
VAL_ 121 C_TrunkTgReleaseRlyBLE 0 "Off (default)" 1 "On(Remote Trunk command)" 2 "Reserved" 3 "Invalid" ;
VAL_ 121 C_BLE_DefrostCtr 0 "Deactivate" 1 "Activate" 2 "Reserved" 3 "Invalid" ;
VAL_ 121 C_BLE_AirconCtr 0 "Deactivate" 1 "Activate" 2 "Reserved" 3 "Invalid" ;
VAL_ 121 C_BLE_TempMd 0 "Centigrade" 1 "Fahrenheit" 2 "Reserved" 3 "Invalid" ;
VAL_ 485 Navi_OverSpdAlarm 0 "None" 1 "Alarm" 2 "reserved" 3 "Invalid" ;
VAL_ 485 Navi_NonSpdTrap 0 "None" 1 "Red Light Trap" 2 "Bus Only Trap" 3 "Cut In Trap" 4 "Parking/Stopping Trap" 5 "Overloaded Trap" 6 "Badloaded Trap" 7 "Shoulder Trap" 8 "Plate Recogn. Camera" 9 "Traffic Camera" 10 "Intersection Block Trap" 11 "Ramp Metering Trap" 12 "User Registered Camera" 13 "Others" 31 "Invalid" ;
VAL_ 485 Navi_WarningZone2 0 "None" 1 "continuous decent" 16 "Steep decent" 17 "tunnel" 18 "Road floods" 19 "Uneven road surface" 20 "Unguarded railroad crossing" 21 "Zipper road" 22 "Two-way traffic" 23 "Cattle crossing" 24 "Hills on the right" 25 "Embankment on the right" 26 "Embankment on the left" 27 "Village" 28 "Pass left or right obstacle" 29 "pass left of obstacle" 30 "pass right of obstacle" 31 "Invarid" 2 "cross wind" 3 "Hills on the left" 4 "humpback bridge" 5 "Confluence from the left" 6 "confluence from the right" 7 "Stop to give way" 8 "Road narrows from both sides" 9 "Narrow bridge" 10 "Road narrows from the left" 11 "Road narrows from the right" 12 "Falling rocks on the left" 13 "Falling rocks on the right" 14 "slippery road" 15 "Steep ascent" ;
VAL_ 485 Navi_WarningZone 0 "None" 1 "Black Spot" 2 "School Zone" 3 "Falling Rocks" 4 "Railway Crossing" 5 "Foggy Area" 6 "Downhill" 7 "Roadkill" 8 "Speed Bump" 9 "Bottleneck" 10 "Under Construction" 15 "Invalid" ;
VAL_ 485 Navi_WarningZone3 0 "None" 1 "danger ahead" 2 "overtaking allowed" 3 "audible warning" 4 "text warning sign which ia not included in GB5768-1999" 5 "yield to oncoming traffic" 6 "yield" 7 "tunnel lights" 8 "tidal lane" 9 "road lying" 10 "Hov lane" 11 "Reserved" 12 "Reserved" 13 "Reserved" 14 "Reserved" 15 "Invalid" ;
VAL_ 485 Navi_CurveWarning 0 "None" 1 "Right" 2 "Left" 3 "Right Curve Continuously" 4 "Left Curve Continuously" 5 "Curve Continuously" 6 "Winding road" 7 "Reserved" 8 "Reserved" 9 "Reserved" 10 "Reserved" 11 "Reserved" 12 "Reserved" 13 "Reserved" 14 "Reserved" 15 "Invalid" ;
VAL_ 485 Navi_SpdLimit_Type 0 "None" 1 "US" 2 "Canada" 3 "Invalid" ;
VAL_ 485 Navi_SpdLimit_Unit 0 "None" 1 "Kilometer" 2 "Mile" 3 "Invalid" ;
VAL_ 485 Navi_SpdInfo_Type 0 "Off" 1 "FixedSpeedTrap" 2 "FixedSpeedTrapNoInfo" 3 "MobileSpeedTrap" 4 "MobileSpeedTrapNoInfo" 5 "SpeedRedlightTrap" 6 "SpeedRedlightTrapNoInfo" 7 "BusSpeedTrap" 8 "BusSpeedTrapNoInfo" 9 "SpeedLimitType1" 10 "SpeedLimitSchoolzoneType1" 11 "SpeedLimitType2" 12 "SpeedLimitSchoolzoneType2" 13 "EU Camera zone warning" 15 "Invalid" ;
VAL_ 485 Navi_SpdLimit 0 "None" 1 "0x01~0xFE:1~254" 254 "0x01~0xFE:1~254" 255 "Invalid" ;
VAL_ 487 NV_EstDist_F 0 "physical distance" 1 "physical distance" 2 "physical distance" 3 "physical distance" 4 "physical distance" 5 "physical distance" 6 "physical distance" 7 "physical distance" 8 "physical distance" 9 "physical distance" 10 "Reserved" 11 "Reserved" 12 "Reserved" 13 "Reserved" 14 "Reserved" 15 "invalid" ;
VAL_ 487 NV_EstDist_Unit 0 "meter" 1 "kilometer" 2 "mile" 3 "feet" 5 "Reserved" 6 "Reserved" 7 "Reserved" 8 "Reserved" 9 "Reserved" 10 "Reserved" 11 "Reserved" 12 "Reserved" 13 "Reserved" 14 "Reserved" 15 "invalid" 4 "yard" ;
VAL_ 487 NV_EstHour 0 "hour" 23 "hour" 255 "invalid" ;
VAL_ 487 NV_EstMin 0 "minutes" 59 "minutes" 255 "invalid" ;
VAL_ 487 NV_Azimuth 0 "Increase value (0~352.5 deg.)" 1 "Increase value (0~352.5 deg.)" 2 "Increase value (0~352.5 deg.)" 3 "Increase value (0~352.5 deg.)" 4 "Increase value (0~352.5 deg.)" 5 "Increase value (0~352.5 deg.)" 6 "Increase value (0~352.5 deg.)" 7 "Increase value (0~352.5 deg.)" 8 "Increase value (0~352.5 deg.)" 9 "Increase value (0~352.5 deg.)" 10 "Increase value (0~352.5 deg.)" 11 "Increase value (0~352.5 deg.)" 12 "Increase value (0~352.5 deg.)" 13 "Increase value (0~352.5 deg.)" 14 "Increase value (0~352.5 deg.)" 15 "Increase value (0~352.5 deg.)" 16 "Increase value (0~352.5 deg.)" 17 "Increase value (0~352.5 deg.)" 18 "Increase value (0~352.5 deg.)" 19 "Increase value (0~352.5 deg.)" 20 "Increase value (0~352.5 deg.)" 21 "Increase value (0~352.5 deg.)" 22 "Increase value (0~352.5 deg.)" 23 "Increase value (0~352.5 deg.)" 24 "Increase value (0~352.5 deg.)" 25 "Increase value (0~352.5 deg.)" 26 "Increase value (0~352.5 deg.)" 27 "Increase value (0~352.5 deg.)" 28 "Increase value (0~352.5 deg.)" 29 "Increase value (0~352.5 deg.)" 30 "Increase value (0~352.5 deg.)" 31 "Increase value (0~352.5 deg.)" 32 "Increase value (0~352.5 deg.)" 33 "Increase value (0~352.5 deg.)" 34 "Increase value (0~352.5 deg.)" 35 "Increase value (0~352.5 deg.)" 36 "Increase value (0~352.5 deg.)" 37 "Increase value (0~352.5 deg.)" 38 "Increase value (0~352.5 deg.)" 39 "Increase value (0~352.5 deg.)" 40 "Increase value (0~352.5 deg.)" 41 "Increase value (0~352.5 deg.)" 42 "Increase value (0~352.5 deg.)" 43 "Increase value (0~352.5 deg.)" 44 "Increase value (0~352.5 deg.)" 45 "Increase value (0~352.5 deg.)" 46 "Increase value (0~352.5 deg.)" 47 "Increase value (0~352.5 deg.)" 255 "Invalid" ;
VAL_ 487 NV_EstDist_I 0 "0" 65534 "65534" 65535 "invalid" ;
VAL_ 487 NV_EstimTimeType 0 "None" 1 "Estimate Time of Arrival" 2 "Remaining Time to Arrive" 3 "Invalid" ;
VAL_ 487 NV_EstimTimeFormat 0 "None" 1 "12 hour" 2 "24 hour" 3 "Invalid" ;
VAL_ 487 NV_EstPointType 0 "destination" 1 "waypoint1" 2 "waypoint2" 3 "waypoint3" 4 "waypoint4" 5 "reserved" 6 "reserved" 7 "reserved" 8 "reserved" 9 "reserved" 10 "reserved" 11 "reserved" 12 "reserved" 13 "reserved" 14 "reserved" 15 "invalid" ;
VAL_ 56 C_DrvWindowCmdAVN 0 "No action" 1 "Manual Down" 2 "Manual Up" 3 "25% Open" 4 "50% Open" 5 "Auto Down" 6 "Auto Up" 7 "Invalid" ;
VAL_ 56 C_RrDefoggerCmdAVN 0 "Off" 1 "On" 2 "Reserved" 3 "Invalid" ;
VAL_ 56 C_TrunkTlgtCmdAVN 0 "Off" 1 "Open(Release)" 2 "Reserved" 3 "Invalid" ;
VAL_ 56 C_GlassCmdAVN 0 "No Action" 1 "Glass Auto Open" 2 "Glass Auto Close" 3 "Glass Auto Tilt Up" 4 "Stop" 5 "reserved" 6 "reserved" 7 "Invalid" ;
VAL_ 56 C_BlindCmdAVN 0 "No Action" 1 "R/Blind Auto Open" 2 "R/Blind Auto Close" 3 "Stop" 4 "reserved" 5 "reserved" 6 "reserved" 7 "Invalid" ;
VAL_ 56 C_CluDispCmdAVN 0 "No Action" 1 "Oil consumption" 2 "Speed" 3 "TBT" 4 "Reserved" 5 "Reserved" 6 "Reserved" 7 "Invalid" ;
VAL_ 56 HU_FLSeatHeatVRcmd 0 "Init" 1 "Unused" 2 "Seat Heat&Vent OFF" 3 "Seat_Vent_Low" 4 "Seat_Vent_Mid" 5 "Seat_Vent_High" 6 "Seat_Heat_Low" 7 "Seat_Heat_Mid" 8 "Seat_Heat_High" 9 "Unused" 10 "Unused" 11 "Unused" 12 "Unused" 13 "Unused" 14 "Unused" 15 "Invalid" ;
VAL_ 56 HU_FRSeatHeatVRcmd 0 "Init" 1 "Unused" 2 "Seat Heat&Vent OFF" 3 "Seat_Vent_Low" 4 "Seat_Vent_Mid" 5 "Seat_Vent_High" 6 "Seat_Heat_Low" 7 "Seat_Heat_Mid" 8 "Seat_Heat_High" 9 "Unused" 10 "Unused" 11 "Unused" 12 "Unused" 13 "Unused" 14 "Unused" 15 "Invalid" ;
VAL_ 369 HU_VehiclePwr 0 "Key out or Audio OFF" 1 "Not used" 2 "ACC or Audio ON" 3 "KBD Wake-up" 4 "Not used" 5 "Not used" 6 "Not used" 7 "Not used" 8 "Not used" 9 "Not used" 10 "Not used" 11 "Not used" 12 "Not used" 13 "Not used" 14 "Not used" 15 "Invalid" ;
VAL_ 448 HU_VRActivity 0 "Deactivated" 1 "Activated" 2 "reserved" 3 "Invalid" ;
VAL_ 232 C_SHVU_DTC_Mode 0 "Default" 1 "DTC Mode" 2 "Normal Mode" 3 "Invalid" ;
VAL_ 61 C_CtrlDrLockRlyIBOX 0 "Off (default)" 1 "On (remote Lock Command)" ;
VAL_ 61 C_CtrlDrUnlockRlyIBOX 0 "0ff" 1 "On (Remote Unlock Command)" ;
VAL_ 61 C_PanicFromIBOX 0 "Off" 1 "On (Remote Horn and Hazard On)" ;
VAL_ 61 C_HazardFromIBOX 0 "Off" 1 "On (Remote Hazard On)" ;
VAL_ 61 C_TeleHeatingCmdIBOX 0 "Off (default)" 1 "On(Remote Heating On)" 2 "Reserved" 3 "Invalid" ;
VAL_ 61 C_PreCrankReq 0 "Default" 1 "Req On" 2 "Not Support" 3 "Invalid" ;
VAL_ 61 C_TeleDrvSeatOpCmdIBOX 0 "Init" 1 "Unused" 2 "Seat Heat&Vent OFF" 3 "Seat_Vent_Low" 4 "Seat_Vent_Mid" 5 "Seat_Vent_High" 6 "Seat_Heat_Low" 7 "Seat_Heat_Mid" 8 "Seat_Heat_High" 9 "Unused" 10 "Unused" 11 "Unused" 12 "Unused" 13 "Unused" 14 "Unused" 15 "Invalid" ;
VAL_ 61 C_TeleAstSeatOpCmdIBOX 0 "Init" 1 "Unused" 2 "Seat Heat&Vent OFF" 3 "Seat_Vent_Low" 4 "Seat_Vent_Mid" 5 "Seat_Vent_High" 6 "Seat_Heat_Low" 7 "Seat_Heat_Mid" 8 "Seat_Heat_High" 9 "Unused" 10 "Unused" 11 "Unused" 12 "Unused" 13 "Unused" 14 "Unused" 15 "Invalid" ;
VAL_ 371 HU_AliveStatus 0 "Not Ready" 1 "On Mode" 2 "Head Unit Update Mode" 3 "Invalid" ;
VAL_ 371 HU_DistanceUnit 0 "Km" 1 "Mile" 2 "Reserved" 3 "Invalid" ;
VAL_ 371 HU_TempUnit 0 "Off" 1 "℃(Centigrade)" 2 "℉(Fahrenheit)" 3 "Invalid" ;
VAL_ 371 CAM_Request 0 "Off" 1 "Rear view" 2 "Panorama view + top view" 3 "Panorama" 4 "BVM_Left" 5 "BVM_Right" 6 "Room mirror view" 7 "Invalid" ;
VAL_ 371 CF_AVN_ProfileIDRValue 0 "Default" 1 "Guest" 2 "Profile 1" 3 "Profile 2" 4 "reserved" 5 "reserved" 6 "reserved" 7 "reserved" 8 "reserved" 9 "reserved" 10 "reserved" 11 "reserved" 12 "reserved" 13 "reserved" 14 "reserved" 15 "Invalid" ;
VAL_ 372 HU_TeleSoCAlertValueSet 0 "0x0~0x64:0~100%" 100 "0x0~0x64:0~100%" 101 "0x65~0xFE:reserved" 254 "0x65~0xFE:reserved" 255 "Invaild" ;
VAL_ 372 HU_TeleVehicleStatusReq 0 "Do not Request" 1 "Request" 2 "reserved" 3 "Invalid" ;
VAL_ 1101 NMSleepFlag_CLU 0 "Alive" 1 "SleepInd" 3 "SleepAck" ;
VAL_ 1101 NMCommandCode_CLU 1 "Alive" 2 "Ring" 4 "Limphome" ;
VAL_ 1088 NMSleepFlag_H_U 0 "Alive" 1 "SleepInd" 3 "SleepAck" ;
VAL_ 1088 NMCommandCode_H_U 1 "Alive" 2 "Ring" 4 "Limphome" ;
VAL_ 1109 NMSleepFlag_CGW 0 "Alive" 1 "SleepInd" 3 "SleepAck" ;
VAL_ 1109 NMCommandCode_CGW 1 "Alive" 2 "Ring" 4 "Limphome" ;
